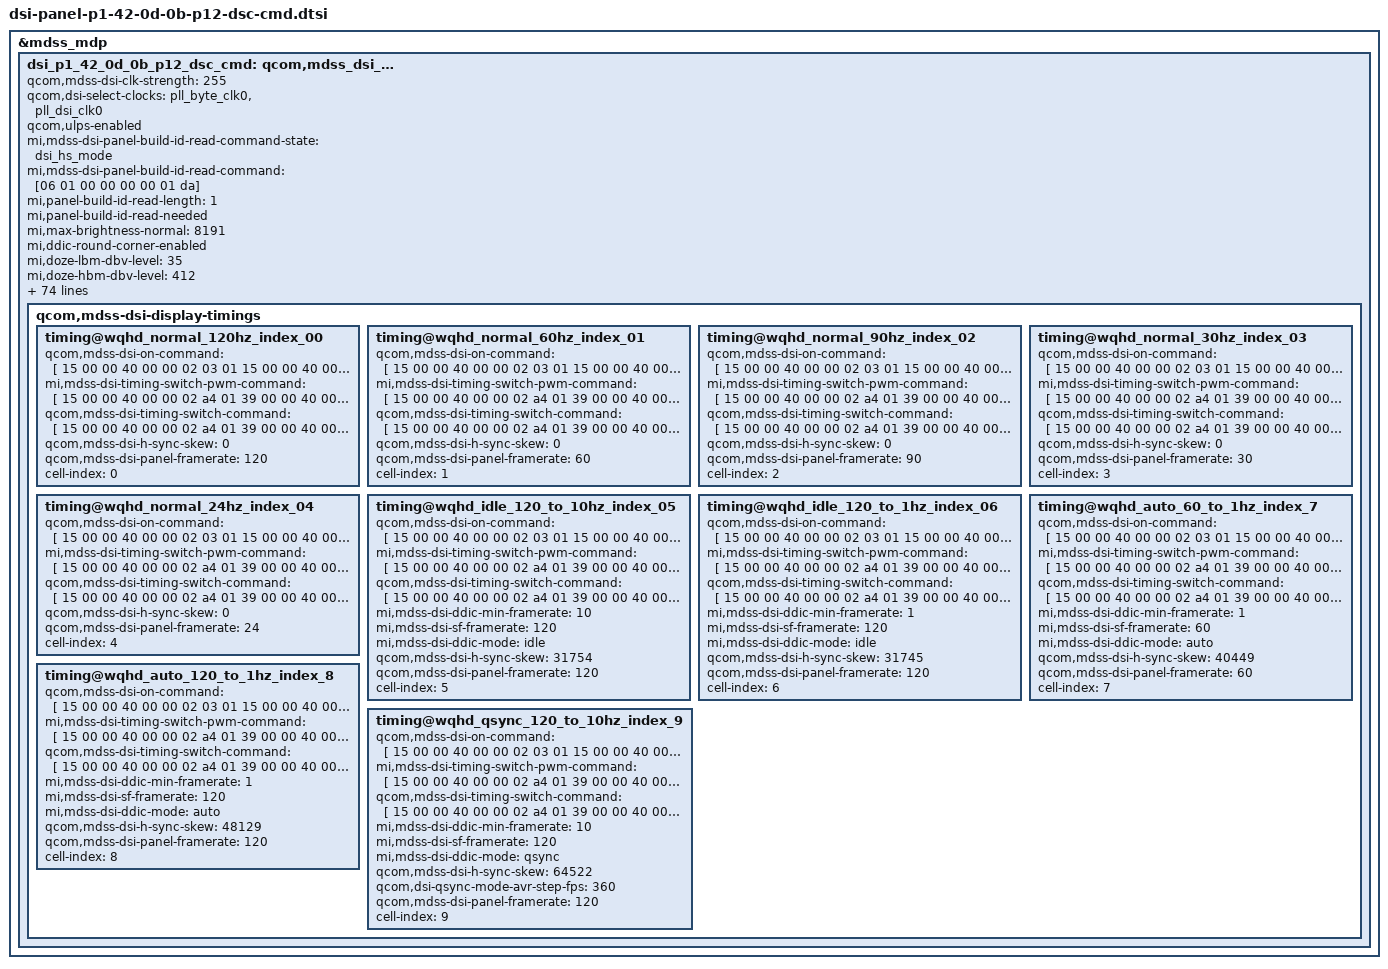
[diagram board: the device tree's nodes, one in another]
/* Xiaomi 17 Ultra panel configuration, OS4.0.7.0.XPACNXM. */

&mdss_mdp {
	dsi_p1_42_0d_0b_p12_dsc_cmd: qcom,mdss_dsi_p1_42_0d_0b_p12_dsc_cmd {
		qcom,mdss-dsi-clk-strength = <255>;
		qcom,dsi-select-clocks = "pll_byte_clk0", "pll_dsi_clk0";
		qcom,ulps-enabled;
		mi,mdss-dsi-panel-build-id-read-command-state = "dsi_hs_mode";
		mi,mdss-dsi-panel-build-id-read-command = [06 01 00 00 00 00 01 da];
		mi,panel-build-id-read-length = <1>;
		mi,panel-build-id-read-needed;
		mi,max-brightness-normal = <8191>;
		mi,ddic-round-corner-enabled;
		mi,doze-lbm-dbv-level = <35>;
		mi,doze-hbm-dbv-level = <412>;
		mi,mdss-dsi-panel-flatmode-on-status-value = <0>;
		mi,mdss-dsi-panel-flatmode-status-read-length = <1>;
		mi,mdss-dsi-panel-flatmode-status-command-state = "dsi_hs_mode";
		mi,mdss-dsi-panel-flatmode-status-command = [06 01 00 01 00 00 01 5f];
		mi,flatmode-status-check-enabled;
		mi,mdss-fac-brightness-max-level = <8191>;
		mi,mdss-dsi-fac-bl-max-level = <8191>;
		mi,mdss-dsi-panel-cell-id-read-length = <13>;
		mi,mdss-dsi-panel-cell-id-read-command-state = "dsi_hs_mode";
		mi,mdss-dsi-panel-cell-id-read-command = [06 01 00 00 00 00 01 5a];
		mi,mdss-dsi-panel-wp-read-length = <8>;
		mi,mdss-dsi-panel-wp-read-command-state = "dsi_hs_mode";
		mi,mdss-dsi-panel-wp-read-command = [06 01 00 00 00 00 01 5c];
		mi,esd-err-irq-gpio-flag = <8196>;
		mi,esd-err-irq-gpio = <&tlmm 97 8196>;
		mi,default-dc-flag;
		mi,dc-feature-enabled;
		mi,panel-on-dimming-delay = <120>;
		mi,panel-id = <20529 4328715>;
		qcom,platform-pmic-reset-gpio = <&tlmm 171 0>;
		qcom,platform-reset-gpio = <&tlmm 98 0>;
		qcom,mdss-brightness-init-level = <916>;
		qcom,mdss-brightness-max-level = <16383>;
		qcom,bl-dsc-cmd-state = "dsi_hs_mode";
		qcom,mdss-dsi-bl-max-level = <16383>;
		qcom,mdss-dsi-bl-min-level = <7>;
		qcom,mdss-dsi-bl-pmic-control-type = "bl_ctrl_dcs";
		qcom,panel-supply-entries = <&dsi_panel_pwr_supply_p1_0b>;
		qcom,mdss-disable-cesta-hw-sleep;
		qcom,mdss-dsi-dma-schedule-window = <50>;
		qcom,mdss-dsi-dma-schedule-line = <1>;
		qcom,mdss-dsi-panel-blackness-level = <3230>;
		qcom,mdss-dsi-panel-peak-brightness = <32000000>;
		qcom,mdss-dsi-panel-hdr-color-primaries = <14500 15500 32000 17000 15500 30000 8000 3000>;
		qcom,mdss-dsi-panel-hdr-enabled;
		qcom,bl-update-flag = "delay_until_first_frame";
		qcom,mdss-dsi-bl-inverted-dbv;
		qcom,mdss-dsi-lp11-init;
		qcom,mdss-dsi-tx-eot-append;
		qcom,mdss-dsi-te-dcs-command = <1>;
		qcom,mdss-dsi-wr-mem-continue = <60>;
		qcom,mdss-dsi-wr-mem-start = <44>;
		qcom,mdss-dsi-te-pin-select = <1>;
		qcom,mdss-pan-physical-height-dimension = <1580>;
		qcom,mdss-pan-physical-width-dimension = <727>;
		qcom,mdss-dsi-reset-sequence = <1 1 0 1 1 10>;
		qcom,mdss-dsi-mdp-trigger = "none";
		qcom,mdss-dsi-dma-trigger = "trigger_sw";
		qcom,mdss-dsi-color-order = "rgb_swap_rgb";
		qcom,mdss-dsi-lane-3-state;
		qcom,mdss-dsi-lane-2-state;
		qcom,mdss-dsi-lane-1-state;
		qcom,mdss-dsi-lane-0-state;
		qcom,mdss-dsi-bllp-power-mode;
		qcom,mdss-dsi-bllp-eof-power-mode;
		qcom,mdss-dsi-traffic-mode = "burst_mode";
		qcom,dsi-phy-num = <0>;
		qcom,dsi-ctrl-num = <0>;
		qcom,mdss-dsi-bpp = <30>;
		qcom,mdss-dsi-virtual-channel-id = <0>;
		qcom,mdss-dsi-panel-physical-type = "oled";
		qcom,mdss-dsi-panel-type = "dsi_cmd_mode";
		qcom,mdss-dsi-panel-name = "xiaomi p1 42 0d 0b prim cmd mode dsc dsi panel";

		qcom,mdss-dsi-display-timings {
			timing@wqhd_normal_120hz_index_00 {
				#include "dsi-panel-p1-42-0d-0b-p12-dsc-cmd-common.dtsi"
				qcom,mdss-dsi-on-command = [
					15 00 00 40 00 00 02 03 01 15 00 00 40 00 00 02
					35 00 15 00 00 40 00 00 02 53 20 39 00 00 40 00
					00 03 51 00 00 15 00 00 40 00 00 02 6f 02 15 00
					00 40 00 00 02 59 09 15 00 00 40 00 00 02 6c 00
					15 00 00 40 00 00 02 6d 00 39 00 00 40 00 00 81
					70 12 00 00 ab 30 80 0a 30 04 b0 00 10 02 58 02
					58 02 00 02 2c 00 20 01 98 00 08 00 0c 06 67 05
					b9 18 00 10 f0 07 10 20 00 06 0f 0f 33 0e 1c 2a
					38 46 54 62 69 70 77 79 7b 7d 7e 02 02 22 00 2a
					40 2a be 3a fc 3a fa 3a f8 3b 38 3b 78 3b b6 4b
					b6 4b f4 4b f4 6c 34 84 74 74 00 00 00 00 00 00
					00 00 00 00 00 00 00 00 00 00 00 00 00 00 00 00
					00 00 00 00 00 00 00 00 00 00 00 00 00 00 00 00
					00 39 00 00 40 00 00 03 ff 5a 81 15 00 00 40 00
					00 02 65 03 15 00 00 40 00 00 02 f3 04 15 00 00
					40 00 00 02 65 05 15 00 00 40 00 00 02 f3 48 39
					00 00 40 00 00 03 f0 aa 10 15 00 00 40 00 00 02
					65 0a 15 00 00 40 00 00 02 eb 10 39 00 00 40 00
					00 03 ff 5a 80 15 00 00 40 00 00 02 65 0e 15 00
					00 40 00 00 02 f9 a1 39 00 00 40 00 00 03 ff 5a
					81 15 00 00 40 00 00 02 65 02 39 00 00 40 00 00
					03 fb 63 73 39 00 00 40 00 00 03 f0 aa 10 15 00
					00 40 00 00 02 65 0b 39 00 00 40 00 00 05 d0 e4
					0f 20 40 15 00 00 40 00 00 02 65 15 39 00 00 40
					00 00 13 d1 be 40 40 40 40 0c 00 00 46 1f 1f 00
					00 40 0c 46 1f 1f 39 00 00 40 00 00 14 d9 39 68
					00 00 00 0b 0a 0d 0c 02 00 00 02 07 06 00 06 02
					0d 15 00 00 40 00 00 02 72 01 39 00 00 40 00 00
					03 ff 5a 83 15 00 00 40 00 00 02 65 0b 15 00 00
					40 00 00 02 f8 05 39 00 00 40 00 00 03 f0 aa 11
					15 00 00 40 00 00 02 c3 31 39 00 00 40 00 00 03
					f0 aa 18 15 00 00 40 00 00 02 b0 80 39 00 00 40
					00 00 03 f0 aa 19 15 00 00 40 00 00 02 c0 e0 39
					00 00 40 00 00 03 f0 aa 1a 15 00 00 40 00 00 02
					b0 01 39 00 00 40 00 00 03 f0 aa 10 39 00 00 40
					00 00 04 eb 00 00 30 39 00 00 40 00 00 08 ea 0f
					41 00 88 48 cb 01 15 00 00 40 00 00 02 65 0d 39
					00 00 40 00 00 04 ea 0c 00 01 15 00 00 40 00 00
					02 65 10 39 00 00 40 00 00 04 ea 0c 80 01 15 00
					00 40 00 00 02 65 13 39 00 00 40 00 00 04 ea c8
					ae 01 15 00 00 40 00 00 02 65 16 39 00 00 40 00
					00 04 ea 64 c1 01 15 00 00 40 00 00 02 65 19 39
					00 00 40 00 00 04 ea 98 a5 01 15 00 00 40 00 00
					02 65 28 39 00 00 40 00 00 04 ea 0c 00 00 39 00
					00 40 00 00 03 f0 aa 00 39 00 00 00 00 00 03 ff
					5a 00 05 00 00 00 78 00 01 11 39 00 00 40 00 00
					03 f0 aa 10 15 00 00 40 00 00 02 65 02 39 00 00
					40 00 00 03 cf 24 13 15 00 00 40 00 00 02 65 0b
					39 00 00 40 00 00 03 cf dd 79 39 00 00 40 00 00
					03 f0 aa 16 39 00 00 40 00 00 16 e3 00 01 00 00
					00 00 00 00 00 00 00 00 00 00 00 00 00 00 00 00
					00 39 00 00 40 00 00 16 e4 00 03 00 00 00 00 00
					00 00 00 00 00 00 00 00 00 00 00 00 00 00 39 00
					00 40 00 00 16 e5 00 04 00 00 00 00 00 00 00 00
					00 00 00 00 00 00 00 00 00 00 00 39 00 00 40 00
					00 16 e6 01 03 0b 00 00 00 00 00 00 00 00 00 00
					00 00 00 00 00 00 00 00 39 00 00 40 00 00 16 e7
					03 03 0b 0b 77 00 00 00 00 0e e0 00 00 00 00 00
					00 00 00 00 00 39 00 00 40 00 00 16 e8 02 0b 0b
					77 00 00 00 00 00 ee 00 00 00 00 00 00 00 00 00
					00 00 39 00 00 40 00 00 16 e9 02 08 08 59 00 00
					00 00 00 ee 00 00 00 00 00 00 00 00 00 00 00 39
					00 00 40 00 00 16 ea 00 0b 00 00 00 00 00 00 00
					00 00 00 00 00 00 00 00 00 00 00 00 39 00 00 40
					00 00 16 eb 02 01 03 ef 00 00 00 00 00 00 00 00
					00 00 00 00 00 00 00 00 00 39 00 00 40 00 00 16
					ec 00 01 00 00 00 00 00 00 00 40 00 00 00 00 00
					00 00 00 00 00 00 39 00 00 40 00 00 1f e0 f0 f1
					f2 f3 f4 f5 f6 00 00 00 f0 f1 f2 f3 f4 f5 f6 00
					00 00 f0 f1 f2 f3 f4 f5 f6 00 00 00 39 00 00 40
					00 00 15 ed f0 f1 f2 f3 f4 f5 f6 f7 f8 00 f0 f1
					f2 f3 f4 f5 f6 f7 f8 00 39 00 00 40 00 00 15 ee
					f0 f1 f2 f3 f4 f5 f6 f7 f8 00 f0 f1 f2 f3 f4 f5
					f6 f7 f8 00 39 00 00 40 00 00 03 f0 aa 12 15 00
					00 00 00 00 02 c7 fe 39 00 00 40 00 00 03 f0 aa
					14 15 00 00 40 00 00 02 65 0c 39 00 00 40 00 00
					03 b5 17 0b 39 00 00 40 00 00 05 bc 10 10 00 1d
					15 00 00 40 00 00 02 65 0c 39 00 00 40 00 00 03
					b6 10 0c 39 00 00 40 00 00 05 bd 10 10 00 22 15
					00 00 40 00 00 02 65 0c 39 00 00 40 00 00 05 c6
					02 06 1e 02 39 00 00 40 00 00 06 ca 10 10 00 1f
					22 39 00 00 40 00 00 03 f0 aa 1b 15 00 00 40 00
					00 02 65 09 39 00 00 00 00 00 04 de 1f 02 02 15
					00 00 40 00 00 02 6c 00 39 00 00 40 00 00 03 75
					00 00 39 00 00 40 00 00 04 71 00 00 00 39 00 00
					40 00 00 03 f0 aa 16 15 00 00 40 00 00 02 d0 00
					15 00 00 40 00 00 02 65 01 15 00 00 40 00 00 02
					d1 00 15 00 00 40 00 00 02 d2 01 15 00 00 40 00
					00 02 76 00 15 00 00 40 00 00 02 77 00 39 00 00
					40 00 00 03 f0 aa 10 15 00 00 40 00 00 02 cf 17
					39 00 00 40 00 00 03 f0 aa 17 15 00 00 40 00 00
					02 c2 80 05 00 00 00 00 00 01 29 39 00 00 40 00
					00 03 f0 aa 17 39 00 00 40 00 00 02 b0 b0 39 00
					00 40 00 00 05 b1 08 06 06 00 39 00 00 40 00 00
					37 b2 00 40 00 00 40 00 00 20 20 00 40 00 00 40
					00 00 20 20 00 00 00 00 e0 00 00 00 20 00 00 20
					00 00 20 00 00 20 00 00 00 00 00 00 00 00 18 00
					00 18 00 00 44 00 00 00 39 00 00 40 00 00 25 b3
					88 b8 00 88 b8 80 80 c0 80 00 40 00 00 40 00 00
					40 00 08 38 00 08 38 00 00 40 00 00 40 00 00 40
					00 00 40 00 39 00 00 40 00 00 1a b4 00 03 06 0c
					18 03 06 0c 18 03 06 0c 18 03 06 0c 18 03 06 0c
					18 03 06 0c 18 39 00 00 40 00 00 0a b5 00 00 00
					00 00 00 00 00 00 39 00 00 40 00 00 31 b6 1f 1f
					1f 1f 1f 1f 1f 1f 1f 1f 1f 1f 1f 1f 1f 1f 1f 1f
					1f 1f 1f 1f 1f 1f 1f 1f 1f 1f 1f 1f 1f 1f 1f 1f
					1f 1f 1f 1f 1f 1f 1f 1f 1f 1f 1f 1f 1f 1f 39 00
					00 00 00 00 1e b7 00 12 34 12 34 52 34 56 34 56
					74 56 78 33 94 26 64 19 98 0c cc 33 94 26 64 19
					98 0c cc 39 00 00 40 00 00 03 f0 aa 10 15 00 00
					40 00 00 02 65 0b 39 00 00 40 00 00 03 cf dd 79
					39 00 00 00 00 00 03 f0 aa 00 39 00 00 40 00 00
					03 f0 aa 19 39 00 00 40 00 00 03 c7 00 00 15 00
					00 40 00 00 02 c4 80 39 00 00 40 00 00 0d c8 ec
					00 00 00 00 00 03 60 00 00 00 00 39 00 00 40 00
					00 0d c8 03 f0 00 00 00 00 00 30 40 00 00 00 39
					00 00 40 00 00 0d c8 03 f0 00 fc 00 00 00 10 00
					00 00 00 39 00 00 40 00 00 0d c8 00 20 00 03 f0
					00 50 a0 c2 08 20 41 39 00 00 40 00 00 0d c8 d4
					00 00 00 00 00 2c 00 00 00 00 00 39 00 00 40 00
					00 0d c8 20 40 00 00 00 00 03 df fe 00 00 00 39
					00 00 40 00 00 0d c8 10 1f c1 f8 00 00 10 10 3e
					04 10 00 39 00 00 40 00 00 0d c8 04 00 00 fb ff
					c0 60 82 06 14 30 c1 39 00 00 40 00 00 0d c8 00
					00 00 00 00 00 03 f0 00 00 00 00 39 00 00 40 00
					00 0d c8 f7 cf 80 00 00 00 07 ef ff 00 00 00 39
					00 00 40 00 00 0d c8 03 f0 00 fc 00 00 03 f0 00
					03 f0 00 39 00 00 40 00 00 0d c8 00 2f bf 00 00
					00 50 81 83 08 20 41 15 00 00 00 00 00 02 c4 00
					39 00 00 40 00 00 03 f0 aa 19 39 00 00 40 00 00
					03 c7 00 15 15 00 00 40 00 00 02 c4 80 39 00 00
					40 00 00 0d c8 f0 00 00 00 00 00 f8 20 00 00 00
					00 39 00 00 40 00 00 0d c8 ff ff c0 00 00 00 f3
					ef ff 00 00 00 39 00 00 40 00 00 0d c8 f3 ff ff
					fc 00 00 fb ff c0 ff f0 00 39 00 00 40 00 00 0d
					c8 f7 df bf 00 0f c0 5c a1 c4 0c 20 81 39 00 00
					40 00 00 0d c8 f4 00 00 00 00 00 ff f0 00 00 00
					00 39 00 00 40 00 00 0d c8 ff ff c0 00 00 00 f7
					ff c0 00 00 00 39 00 00 40 00 00 0d c8 fb ef ff
					00 00 00 fb ff ff fc 00 00 39 00 00 40 00 00 0d
					c8 ff ff ff ff f0 00 3c 81 84 0c 20 41 39 00 00
					40 00 00 0d c8 f4 00 00 00 00 00 f4 00 00 00 00
					00 39 00 00 40 00 00 0d c8 f8 0f c0 00 00 00 f7
					ff c0 00 00 00 39 00 00 40 00 00 0d c8 f7 d0 00
					00 00 00 f7 ef fe ff f0 00 39 00 00 40 00 00 0d
					c8 f8 0f c1 03 ff c0 5c 81 02 08 20 40 15 00 00
					00 00 00 02 c4 00 39 00 00 40 00 00 03 f0 aa 19
					39 00 00 40 00 00 03 c7 00 2a 15 00 00 40 00 00
					02 c4 80 39 00 00 40 00 00 0d c8 f4 00 00 00 00
					00 f4 00 00 00 00 00 39 00 00 40 00 00 0d c8 f7
					ef c0 00 00 00 f7 ff c0 00 00 00 39 00 00 40 00
					00 0d c8 fb f0 3f 00 00 00 f3 ef bf ff f0 00 39
					00 00 40 00 00 0d c8 ff ff ff fc 00 00 54 81 84
					0c 20 41 39 00 00 40 00 00 0d c8 f8 00 00 00 00
					00 f7 f0 00 00 00 00 39 00 00 40 00 00 0d c8 f7
					f0 00 00 00 00 f7 ff c0 00 00 00 39 00 00 40 00
					00 0d c8 fb ff fe fc 00 00 f7 ff c0 00 00 00 39
					00 00 40 00 00 0d c8 ff ff c0 00 00 00 50 71 43
					08 10 41 39 00 00 40 00 00 0d c8 f8 00 00 00 00
					00 f7 f0 00 00 00 00 39 00 00 40 00 00 0d c8 f3
					ff 00 00 00 00 f7 b0 c0 00 00 00 39 00 00 40 00
					00 0d c8 f8 3f ff f0 00 00 fb ff ff fc 00 00 39
					00 00 40 00 00 0d c8 ff f0 00 13 f0 00 50 71 03
					08 20 41 15 00 00 00 00 00 02 c4 00 39 00 00 40
					00 00 03 f0 aa 19 39 00 00 40 00 00 03 c7 00 3f
					15 00 00 40 00 00 02 c4 80 39 00 00 40 00 00 0d
					c8 20 40 40 60 60 60 80 80 80 80 a0 a0 39 00 00
					40 00 00 0d c8 a0 a0 a0 c0 c0 c0 c0 c0 c0 e0 e0
					e0 39 00 00 40 00 00 0d c8 e0 e0 e0 e0 ff ff ff
					ff ff ff ff ff 39 00 00 40 00 00 0d c8 1b 1c 2f
					1e 4c 5b 1f 56 5c 6e a0 a0 39 00 00 40 00 00 0d
					c8 a0 a0 a0 c0 c0 c0 c0 c0 c0 e0 e0 e0 39 00 00
					40 00 00 0d c8 e0 e0 e0 e0 ff ff ff ff ff ff ff
					ff 39 00 00 40 00 00 0d c8 20 40 40 60 60 60 80
					80 80 80 a0 a0 39 00 00 40 00 00 0d c8 a0 a0 a0
					c0 c0 c0 c0 c0 c0 e0 e0 e0 39 00 00 40 00 00 0d
					c8 e0 e0 e0 e0 ff ff ff ff ff ff ff ff 15 00 00
					00 00 00 02 c4 00 39 00 00 40 00 00 03 f0 aa 19
					39 00 00 40 00 00 03 c7 00 c6 15 00 00 40 00 00
					02 c4 80 39 00 00 40 00 00 0d c8 f8 00 00 00 00
					00 d8 00 00 00 00 00 39 00 00 40 00 00 0d c8 03
					f0 00 00 00 00 00 00 40 00 00 00 39 00 00 40 00
					00 0d c8 ec 00 00 fc 00 00 00 00 00 00 00 00 39
					00 00 40 00 00 0d c8 00 00 00 03 f0 00 50 50 c2
					08 20 41 39 00 00 40 00 00 0d c8 c8 00 00 00 00
					00 00 00 00 00 00 00 39 00 00 40 00 00 0d c8 00
					40 00 00 00 00 0b df fe 00 00 00 39 00 00 40 00
					00 0d c8 fc 1f c1 f8 00 00 fc 10 3e 04 10 00 39
					00 00 40 00 00 0d c8 00 00 00 fb ff c0 78 82 06
					14 30 c1 39 00 00 40 00 00 0d c8 00 00 00 00 00
					00 03 f0 00 00 00 00 39 00 00 40 00 00 0d c8 f7
					cf 80 00 00 00 07 ef ff 00 00 00 39 00 00 40 00
					00 0d c8 03 f0 00 fc 00 00 03 f0 00 03 f0 00 39
					00 00 40 00 00 0d c8 00 2f bf 00 00 00 50 81 83
					08 20 41 15 00 00 00 00 00 02 c4 00 39 00 00 40
					00 00 03 f0 aa 19 39 00 00 40 00 00 03 c7 00 db
					15 00 00 40 00 00 02 c4 80 39 00 00 40 00 00 0d
					c8 f0 00 00 00 00 00 f8 20 00 00 00 00 39 00 00
					40 00 00 0d c8 ff ff c0 00 00 00 f3 ef ff 00 00
					00 39 00 00 40 00 00 0d c8 f3 ff ff fc 00 00 fb
					ff c0 ff f0 00 39 00 00 40 00 00 0d c8 f7 df bf
					00 0f c0 5c a1 c4 0c 20 81 39 00 00 40 00 00 0d
					c8 f8 00 00 00 00 00 ff f0 00 00 00 00 39 00 00
					40 00 00 0d c8 ff ff c0 00 00 00 f7 ff c0 00 00
					00 39 00 00 40 00 00 0d c8 fb ef ff 00 00 00 fb
					ff ff fc 00 00 39 00 00 40 00 00 0d c8 ff ff ff
					ff f0 00 3c 81 84 0c 20 41 39 00 00 40 00 00 0d
					c8 f4 00 00 00 00 00 f4 00 00 00 00 00 39 00 00
					40 00 00 0d c8 f8 0f c0 00 00 00 f7 ff c0 00 00
					00 39 00 00 40 00 00 0d c8 f7 d0 00 00 00 00 f7
					ef fe ff f0 00 39 00 00 40 00 00 0d c8 f8 0f c1
					03 ff c0 5c 81 02 08 20 40 15 00 00 00 00 00 02
					c4 00 39 00 00 40 00 00 03 f0 aa 19 39 00 00 40
					00 00 03 c7 01 05 15 00 00 40 00 00 02 c4 80 39
					00 00 40 00 00 0d c8 20 40 40 60 60 60 80 80 80
					80 a0 a0 39 00 00 40 00 00 0d c8 a0 a0 a0 c0 c0
					c0 c0 c0 c0 e0 e0 e0 39 00 00 40 00 00 0d c8 e0
					e0 e0 e0 ff ff ff ff ff ff ff ff 39 00 00 40 00
					00 0d c8 20 40 40 60 60 60 80 80 80 80 a0 a0 39
					00 00 40 00 00 0d c8 a0 a0 a0 c0 c0 c0 c0 c0 c0
					e0 e0 e0 39 00 00 40 00 00 0d c8 e0 e0 e0 e0 ff
					ff ff ff ff ff ff ff 39 00 00 40 00 00 0d c8 20
					40 40 60 60 60 80 80 80 80 a0 a0 39 00 00 40 00
					00 0d c8 a0 a0 a0 c0 c0 c0 c0 c0 c0 e0 e0 e0 39
					00 00 40 00 00 0d c8 e0 e0 e0 e0 ff ff ff ff ff
					ff ff ff 15 00 00 00 00 00 02 c4 00
				];
				mi,mdss-dsi-timing-switch-pwm-command = [
					15 00 00 40 00 00 02 a4 01 39 00 00 40 00 00 03
					f0 aa 14 15 00 00 40 00 00 02 65 0c 39 00 00 40
					00 00 03 b5 18 0c 39 00 00 40 00 00 05 bc 10 10
					00 1e 15 00 00 40 00 00 02 65 0c 39 00 00 40 00
					00 03 b6 0f 0b 39 00 00 40 00 00 05 bd 10 10 00
					21 15 00 00 40 00 00 02 65 0c 39 00 00 40 00 00
					05 c6 03 07 1f 03 39 00 00 40 00 00 06 ca 10 10
					00 1e 13 39 00 00 40 00 00 03 f0 aa 1b 15 00 00
					40 00 00 02 65 09 39 00 00 40 00 00 04 de 1e 01
					03 15 00 00 00 00 00 02 a4 00 15 00 00 40 00 00
					02 6c 02 39 00 00 40 00 00 03 75 00 00 39 00 00
					40 00 00 04 71 00 00 00 39 00 00 40 00 00 03 f0
					aa 16 15 00 00 40 00 00 02 d0 00 15 00 00 40 00
					00 02 65 07 15 00 00 40 00 00 02 d1 02 15 00 00
					40 00 00 02 d2 01 15 00 00 40 00 00 02 65 02 39
					00 00 40 00 00 04 d2 03 65 0f 15 00 00 40 00 00
					02 76 01 15 00 00 40 00 00 02 77 05 39 00 00 40
					00 00 03 f0 aa 10 15 00 00 40 00 00 02 cf 09 15
					00 00 00 00 00 02 a6 01
				];
				qcom,mdss-dsi-timing-switch-command = [
					15 00 00 40 00 00 02 a4 01 39 00 00 40 00 00 03
					f0 aa 14 15 00 00 40 00 00 02 65 0c 39 00 00 40
					00 00 03 b5 17 0b 39 00 00 40 00 00 05 bc 10 10
					00 1d 15 00 00 40 00 00 02 65 0c 39 00 00 40 00
					00 03 b6 10 0c 39 00 00 40 00 00 05 bd 10 10 00
					22 15 00 00 40 00 00 02 65 0c 39 00 00 40 00 00
					05 c6 02 06 1e 02 39 00 00 40 00 00 06 ca 10 10
					00 1f 22 39 00 00 40 00 00 03 f0 aa 1b 15 00 00
					40 00 00 02 65 09 39 00 00 40 00 00 04 de 1f 02
					02 15 00 00 00 00 00 02 a4 00 15 00 00 40 00 00
					02 6c 00 39 00 00 40 00 00 03 75 00 00 39 00 00
					40 00 00 04 71 00 00 00 39 00 00 40 00 00 03 f0
					aa 16 15 00 00 40 00 00 02 d0 00 15 00 00 40 00
					00 02 65 01 15 00 00 40 00 00 02 d1 00 15 00 00
					40 00 00 02 d2 01 15 00 00 40 00 00 02 76 00 15
					00 00 40 00 00 02 77 00 39 00 00 40 00 00 03 f0
					aa 10 15 00 00 40 00 00 02 cf 17 39 00 00 40 00
					00 03 f0 aa 17 15 00 00 40 00 00 02 c2 80 15 00
					00 00 00 00 02 a6 01
				];
				qcom,mdss-dsi-h-sync-skew = <0>;
				qcom,mdss-dsi-panel-framerate = <120>;
				cell-index = <0>;
			};

			timing@wqhd_normal_60hz_index_01 {
				#include "dsi-panel-p1-42-0d-0b-p12-dsc-cmd-common.dtsi"
				qcom,mdss-dsi-on-command = [
					15 00 00 40 00 00 02 03 01 15 00 00 40 00 00 02
					35 00 15 00 00 40 00 00 02 53 20 39 00 00 40 00
					00 03 51 00 00 15 00 00 40 00 00 02 6f 02 15 00
					00 40 00 00 02 59 09 15 00 00 40 00 00 02 6c 00
					15 00 00 40 00 00 02 6d 00 39 00 00 40 00 00 81
					70 12 00 00 ab 30 80 0a 30 04 b0 00 10 02 58 02
					58 02 00 02 2c 00 20 01 98 00 08 00 0c 06 67 05
					b9 18 00 10 f0 07 10 20 00 06 0f 0f 33 0e 1c 2a
					38 46 54 62 69 70 77 79 7b 7d 7e 02 02 22 00 2a
					40 2a be 3a fc 3a fa 3a f8 3b 38 3b 78 3b b6 4b
					b6 4b f4 4b f4 6c 34 84 74 74 00 00 00 00 00 00
					00 00 00 00 00 00 00 00 00 00 00 00 00 00 00 00
					00 00 00 00 00 00 00 00 00 00 00 00 00 00 00 00
					00 39 00 00 40 00 00 03 ff 5a 81 15 00 00 40 00
					00 02 65 03 15 00 00 40 00 00 02 f3 04 15 00 00
					40 00 00 02 65 05 15 00 00 40 00 00 02 f3 48 39
					00 00 40 00 00 03 f0 aa 10 15 00 00 40 00 00 02
					65 0a 15 00 00 40 00 00 02 eb 10 39 00 00 40 00
					00 03 ff 5a 80 15 00 00 40 00 00 02 65 0e 15 00
					00 40 00 00 02 f9 a1 39 00 00 40 00 00 03 ff 5a
					81 15 00 00 40 00 00 02 65 02 39 00 00 40 00 00
					03 fb 63 73 39 00 00 40 00 00 03 f0 aa 10 15 00
					00 40 00 00 02 65 0b 39 00 00 40 00 00 05 d0 e4
					0f 20 40 15 00 00 40 00 00 02 65 15 39 00 00 40
					00 00 13 d1 be 40 40 40 40 0c 00 00 46 1f 1f 00
					00 40 0c 46 1f 1f 39 00 00 40 00 00 14 d9 39 68
					00 00 00 0b 0a 0d 0c 02 00 00 02 07 06 00 06 02
					0d 15 00 00 40 00 00 02 72 01 39 00 00 40 00 00
					03 ff 5a 83 15 00 00 40 00 00 02 65 0b 15 00 00
					40 00 00 02 f8 05 39 00 00 40 00 00 03 f0 aa 11
					15 00 00 40 00 00 02 c3 31 39 00 00 40 00 00 03
					f0 aa 18 15 00 00 40 00 00 02 b0 80 39 00 00 40
					00 00 03 f0 aa 19 15 00 00 40 00 00 02 c0 e0 39
					00 00 40 00 00 03 f0 aa 1a 15 00 00 40 00 00 02
					b0 01 39 00 00 40 00 00 03 f0 aa 10 39 00 00 40
					00 00 04 eb 00 00 30 39 00 00 40 00 00 08 ea 0f
					41 00 88 48 cb 01 15 00 00 40 00 00 02 65 0d 39
					00 00 40 00 00 04 ea 0c 00 01 15 00 00 40 00 00
					02 65 10 39 00 00 40 00 00 04 ea 0c 80 01 15 00
					00 40 00 00 02 65 13 39 00 00 40 00 00 04 ea c8
					ae 01 15 00 00 40 00 00 02 65 16 39 00 00 40 00
					00 04 ea 64 c1 01 15 00 00 40 00 00 02 65 19 39
					00 00 40 00 00 04 ea 98 a5 01 15 00 00 40 00 00
					02 65 28 39 00 00 40 00 00 04 ea 0c 00 00 39 00
					00 40 00 00 03 f0 aa 00 39 00 00 00 00 00 03 ff
					5a 00 05 00 00 00 78 00 01 11 39 00 00 40 00 00
					03 f0 aa 10 15 00 00 40 00 00 02 65 02 39 00 00
					40 00 00 03 cf 24 13 15 00 00 40 00 00 02 65 0b
					39 00 00 40 00 00 03 cf dd 79 39 00 00 40 00 00
					03 f0 aa 16 39 00 00 40 00 00 16 e3 00 01 00 00
					00 00 00 00 00 00 00 00 00 00 00 00 00 00 00 00
					00 39 00 00 40 00 00 16 e4 00 03 00 00 00 00 00
					00 00 00 00 00 00 00 00 00 00 00 00 00 00 39 00
					00 40 00 00 16 e5 00 04 00 00 00 00 00 00 00 00
					00 00 00 00 00 00 00 00 00 00 00 39 00 00 40 00
					00 16 e6 01 03 0b 00 00 00 00 00 00 00 00 00 00
					00 00 00 00 00 00 00 00 39 00 00 40 00 00 16 e7
					03 03 0b 0b 77 00 00 00 00 0e e0 00 00 00 00 00
					00 00 00 00 00 39 00 00 40 00 00 16 e8 02 0b 0b
					77 00 00 00 00 00 ee 00 00 00 00 00 00 00 00 00
					00 00 39 00 00 40 00 00 16 e9 02 08 08 59 00 00
					00 00 00 ee 00 00 00 00 00 00 00 00 00 00 00 39
					00 00 40 00 00 16 ea 00 0b 00 00 00 00 00 00 00
					00 00 00 00 00 00 00 00 00 00 00 00 39 00 00 40
					00 00 16 eb 02 01 03 ef 00 00 00 00 00 00 00 00
					00 00 00 00 00 00 00 00 00 39 00 00 40 00 00 16
					ec 00 01 00 00 00 00 00 00 00 40 00 00 00 00 00
					00 00 00 00 00 00 39 00 00 40 00 00 1f e0 f0 f1
					f2 f3 f4 f5 f6 00 00 00 f0 f1 f2 f3 f4 f5 f6 00
					00 00 f0 f1 f2 f3 f4 f5 f6 00 00 00 39 00 00 40
					00 00 15 ed f0 f1 f2 f3 f4 f5 f6 f7 f8 00 f0 f1
					f2 f3 f4 f5 f6 f7 f8 00 39 00 00 40 00 00 15 ee
					f0 f1 f2 f3 f4 f5 f6 f7 f8 00 f0 f1 f2 f3 f4 f5
					f6 f7 f8 00 39 00 00 40 00 00 03 f0 aa 12 15 00
					00 00 00 00 02 c7 fe 39 00 00 40 00 00 03 f0 aa
					14 15 00 00 40 00 00 02 65 0c 39 00 00 40 00 00
					03 b5 17 0b 39 00 00 40 00 00 05 bc 10 10 00 1d
					15 00 00 40 00 00 02 65 0c 39 00 00 40 00 00 03
					b6 10 0c 39 00 00 40 00 00 05 bd 10 10 00 22 15
					00 00 40 00 00 02 65 0c 39 00 00 40 00 00 05 c6
					02 06 1e 02 39 00 00 40 00 00 06 ca 10 10 00 1f
					22 39 00 00 40 00 00 03 f0 aa 1b 15 00 00 40 00
					00 02 65 09 39 00 00 00 00 00 04 de 1f 02 02 15
					00 00 40 00 00 02 6c 00 39 00 00 40 00 00 03 75
					c0 00 39 00 00 40 00 00 04 71 01 00 01 39 00 00
					40 00 00 03 f0 aa 16 15 00 00 40 00 00 02 d0 00
					15 00 00 40 00 00 02 65 01 15 00 00 40 00 00 02
					d1 00 15 00 00 40 00 00 02 d2 01 15 00 00 40 00
					00 02 65 02 39 00 00 40 00 00 04 d2 0a 53 0f 15
					00 00 40 00 00 02 76 01 15 00 00 40 00 00 02 77
					03 39 00 00 40 00 00 03 f0 aa 10 15 00 00 40 00
					00 02 cf 09 39 00 00 40 00 00 03 f0 aa 17 15 00
					00 40 00 00 02 c2 80 05 00 00 00 00 00 01 29 39
					00 00 40 00 00 03 f0 aa 17 39 00 00 40 00 00 02
					b0 b0 39 00 00 40 00 00 05 b1 08 06 06 00 39 00
					00 40 00 00 37 b2 00 40 00 00 40 00 00 20 20 00
					40 00 00 40 00 00 20 20 00 00 00 00 e0 00 00 00
					20 00 00 20 00 00 20 00 00 20 00 00 00 00 00 00
					00 00 18 00 00 18 00 00 44 00 00 00 39 00 00 40
					00 00 25 b3 88 b8 00 88 b8 80 80 c0 80 00 40 00
					00 40 00 00 40 00 08 38 00 08 38 00 00 40 00 00
					40 00 00 40 00 00 40 00 39 00 00 40 00 00 1a b4
					00 03 06 0c 18 03 06 0c 18 03 06 0c 18 03 06 0c
					18 03 06 0c 18 03 06 0c 18 39 00 00 40 00 00 0a
					b5 00 00 00 00 00 00 00 00 00 39 00 00 40 00 00
					31 b6 1f 1f 1f 1f 1f 1f 1f 1f 1f 1f 1f 1f 1f 1f
					1f 1f 1f 1f 1f 1f 1f 1f 1f 1f 1f 1f 1f 1f 1f 1f
					1f 1f 1f 1f 1f 1f 1f 1f 1f 1f 1f 1f 1f 1f 1f 1f
					1f 1f 39 00 00 00 00 00 1e b7 00 12 34 12 34 52
					34 56 34 56 74 56 78 33 94 26 64 19 98 0c cc 33
					94 26 64 19 98 0c cc 39 00 00 40 00 00 03 f0 aa
					10 15 00 00 40 00 00 02 65 0b 39 00 00 40 00 00
					03 cf dd 79 39 00 00 00 00 00 03 f0 aa 00 39 00
					00 40 00 00 03 f0 aa 19 39 00 00 40 00 00 03 c7
					00 00 15 00 00 40 00 00 02 c4 80 39 00 00 40 00
					00 0d c8 ec 00 00 00 00 00 03 60 00 00 00 00 39
					00 00 40 00 00 0d c8 03 f0 00 00 00 00 00 30 40
					00 00 00 39 00 00 40 00 00 0d c8 03 f0 00 fc 00
					00 00 10 00 00 00 00 39 00 00 40 00 00 0d c8 00
					20 00 03 f0 00 50 a0 c2 08 20 41 39 00 00 40 00
					00 0d c8 d4 00 00 00 00 00 2c 00 00 00 00 00 39
					00 00 40 00 00 0d c8 20 40 00 00 00 00 03 df fe
					00 00 00 39 00 00 40 00 00 0d c8 10 1f c1 f8 00
					00 10 10 3e 04 10 00 39 00 00 40 00 00 0d c8 04
					00 00 fb ff c0 60 82 06 14 30 c1 39 00 00 40 00
					00 0d c8 00 00 00 00 00 00 03 f0 00 00 00 00 39
					00 00 40 00 00 0d c8 f7 cf 80 00 00 00 07 ef ff
					00 00 00 39 00 00 40 00 00 0d c8 03 f0 00 fc 00
					00 03 f0 00 03 f0 00 39 00 00 40 00 00 0d c8 00
					2f bf 00 00 00 50 81 83 08 20 41 15 00 00 00 00
					00 02 c4 00 39 00 00 40 00 00 03 f0 aa 19 39 00
					00 40 00 00 03 c7 00 15 15 00 00 40 00 00 02 c4
					80 39 00 00 40 00 00 0d c8 f0 00 00 00 00 00 f8
					20 00 00 00 00 39 00 00 40 00 00 0d c8 ff ff c0
					00 00 00 f3 ef ff 00 00 00 39 00 00 40 00 00 0d
					c8 f3 ff ff fc 00 00 fb ff c0 ff f0 00 39 00 00
					40 00 00 0d c8 f7 df bf 00 0f c0 5c a1 c4 0c 20
					81 39 00 00 40 00 00 0d c8 f4 00 00 00 00 00 ff
					f0 00 00 00 00 39 00 00 40 00 00 0d c8 ff ff c0
					00 00 00 f7 ff c0 00 00 00 39 00 00 40 00 00 0d
					c8 fb ef ff 00 00 00 fb ff ff fc 00 00 39 00 00
					40 00 00 0d c8 ff ff ff ff f0 00 3c 81 84 0c 20
					41 39 00 00 40 00 00 0d c8 f4 00 00 00 00 00 f4
					00 00 00 00 00 39 00 00 40 00 00 0d c8 f8 0f c0
					00 00 00 f7 ff c0 00 00 00 39 00 00 40 00 00 0d
					c8 f7 d0 00 00 00 00 f7 ef fe ff f0 00 39 00 00
					40 00 00 0d c8 f8 0f c1 03 ff c0 5c 81 02 08 20
					40 15 00 00 00 00 00 02 c4 00 39 00 00 40 00 00
					03 f0 aa 19 39 00 00 40 00 00 03 c7 00 2a 15 00
					00 40 00 00 02 c4 80 39 00 00 40 00 00 0d c8 f4
					00 00 00 00 00 f4 00 00 00 00 00 39 00 00 40 00
					00 0d c8 f7 ef c0 00 00 00 f7 ff c0 00 00 00 39
					00 00 40 00 00 0d c8 fb f0 3f 00 00 00 f3 ef bf
					ff f0 00 39 00 00 40 00 00 0d c8 ff ff ff fc 00
					00 54 81 84 0c 20 41 39 00 00 40 00 00 0d c8 f8
					00 00 00 00 00 f7 f0 00 00 00 00 39 00 00 40 00
					00 0d c8 f7 f0 00 00 00 00 f7 ff c0 00 00 00 39
					00 00 40 00 00 0d c8 fb ff fe fc 00 00 f7 ff c0
					00 00 00 39 00 00 40 00 00 0d c8 ff ff c0 00 00
					00 50 71 43 08 10 41 39 00 00 40 00 00 0d c8 f8
					00 00 00 00 00 f7 f0 00 00 00 00 39 00 00 40 00
					00 0d c8 f3 ff 00 00 00 00 f7 b0 c0 00 00 00 39
					00 00 40 00 00 0d c8 f8 3f ff f0 00 00 fb ff ff
					fc 00 00 39 00 00 40 00 00 0d c8 ff f0 00 13 f0
					00 50 71 03 08 20 41 15 00 00 00 00 00 02 c4 00
					39 00 00 40 00 00 03 f0 aa 19 39 00 00 40 00 00
					03 c7 00 3f 15 00 00 40 00 00 02 c4 80 39 00 00
					40 00 00 0d c8 20 40 40 60 60 60 80 80 80 80 a0
					a0 39 00 00 40 00 00 0d c8 a0 a0 a0 c0 c0 c0 c0
					c0 c0 e0 e0 e0 39 00 00 40 00 00 0d c8 e0 e0 e0
					e0 ff ff ff ff ff ff ff ff 39 00 00 40 00 00 0d
					c8 1b 1c 2f 1e 4c 5b 1f 56 5c 6e a0 a0 39 00 00
					40 00 00 0d c8 a0 a0 a0 c0 c0 c0 c0 c0 c0 e0 e0
					e0 39 00 00 40 00 00 0d c8 e0 e0 e0 e0 ff ff ff
					ff ff ff ff ff 39 00 00 40 00 00 0d c8 20 40 40
					60 60 60 80 80 80 80 a0 a0 39 00 00 40 00 00 0d
					c8 a0 a0 a0 c0 c0 c0 c0 c0 c0 e0 e0 e0 39 00 00
					40 00 00 0d c8 e0 e0 e0 e0 ff ff ff ff ff ff ff
					ff 15 00 00 00 00 00 02 c4 00 39 00 00 40 00 00
					03 f0 aa 19 39 00 00 40 00 00 03 c7 00 c6 15 00
					00 40 00 00 02 c4 80 39 00 00 40 00 00 0d c8 f8
					00 00 00 00 00 d8 00 00 00 00 00 39 00 00 40 00
					00 0d c8 03 f0 00 00 00 00 00 00 40 00 00 00 39
					00 00 40 00 00 0d c8 ec 00 00 fc 00 00 00 00 00
					00 00 00 39 00 00 40 00 00 0d c8 00 00 00 03 f0
					00 50 50 c2 08 20 41 39 00 00 40 00 00 0d c8 c8
					00 00 00 00 00 00 00 00 00 00 00 39 00 00 40 00
					00 0d c8 00 40 00 00 00 00 0b df fe 00 00 00 39
					00 00 40 00 00 0d c8 fc 1f c1 f8 00 00 fc 10 3e
					04 10 00 39 00 00 40 00 00 0d c8 00 00 00 fb ff
					c0 78 82 06 14 30 c1 39 00 00 40 00 00 0d c8 00
					00 00 00 00 00 03 f0 00 00 00 00 39 00 00 40 00
					00 0d c8 f7 cf 80 00 00 00 07 ef ff 00 00 00 39
					00 00 40 00 00 0d c8 03 f0 00 fc 00 00 03 f0 00
					03 f0 00 39 00 00 40 00 00 0d c8 00 2f bf 00 00
					00 50 81 83 08 20 41 15 00 00 00 00 00 02 c4 00
					39 00 00 40 00 00 03 f0 aa 19 39 00 00 40 00 00
					03 c7 00 db 15 00 00 40 00 00 02 c4 80 39 00 00
					40 00 00 0d c8 f0 00 00 00 00 00 f8 20 00 00 00
					00 39 00 00 40 00 00 0d c8 ff ff c0 00 00 00 f3
					ef ff 00 00 00 39 00 00 40 00 00 0d c8 f3 ff ff
					fc 00 00 fb ff c0 ff f0 00 39 00 00 40 00 00 0d
					c8 f7 df bf 00 0f c0 5c a1 c4 0c 20 81 39 00 00
					40 00 00 0d c8 f8 00 00 00 00 00 ff f0 00 00 00
					00 39 00 00 40 00 00 0d c8 ff ff c0 00 00 00 f7
					ff c0 00 00 00 39 00 00 40 00 00 0d c8 fb ef ff
					00 00 00 fb ff ff fc 00 00 39 00 00 40 00 00 0d
					c8 ff ff ff ff f0 00 3c 81 84 0c 20 41 39 00 00
					40 00 00 0d c8 f4 00 00 00 00 00 f4 00 00 00 00
					00 39 00 00 40 00 00 0d c8 f8 0f c0 00 00 00 f7
					ff c0 00 00 00 39 00 00 40 00 00 0d c8 f7 d0 00
					00 00 00 f7 ef fe ff f0 00 39 00 00 40 00 00 0d
					c8 f8 0f c1 03 ff c0 5c 81 02 08 20 40 15 00 00
					00 00 00 02 c4 00 39 00 00 40 00 00 03 f0 aa 19
					39 00 00 40 00 00 03 c7 01 05 15 00 00 40 00 00
					02 c4 80 39 00 00 40 00 00 0d c8 20 40 40 60 60
					60 80 80 80 80 a0 a0 39 00 00 40 00 00 0d c8 a0
					a0 a0 c0 c0 c0 c0 c0 c0 e0 e0 e0 39 00 00 40 00
					00 0d c8 e0 e0 e0 e0 ff ff ff ff ff ff ff ff 39
					00 00 40 00 00 0d c8 20 40 40 60 60 60 80 80 80
					80 a0 a0 39 00 00 40 00 00 0d c8 a0 a0 a0 c0 c0
					c0 c0 c0 c0 e0 e0 e0 39 00 00 40 00 00 0d c8 e0
					e0 e0 e0 ff ff ff ff ff ff ff ff 39 00 00 40 00
					00 0d c8 20 40 40 60 60 60 80 80 80 80 a0 a0 39
					00 00 40 00 00 0d c8 a0 a0 a0 c0 c0 c0 c0 c0 c0
					e0 e0 e0 39 00 00 40 00 00 0d c8 e0 e0 e0 e0 ff
					ff ff ff ff ff ff ff 15 00 00 00 00 00 02 c4 00
				];
				mi,mdss-dsi-timing-switch-pwm-command = [
					15 00 00 40 00 00 02 a4 01 39 00 00 40 00 00 03
					f0 aa 14 15 00 00 40 00 00 02 65 0c 39 00 00 40
					00 00 03 b5 18 0c 39 00 00 40 00 00 05 bc 10 10
					00 1e 15 00 00 40 00 00 02 65 0c 39 00 00 40 00
					00 03 b6 0f 0b 39 00 00 40 00 00 05 bd 10 10 00
					21 15 00 00 40 00 00 02 65 0c 39 00 00 40 00 00
					05 c6 03 07 1f 03 39 00 00 40 00 00 06 ca 10 10
					00 1e 13 39 00 00 40 00 00 03 f0 aa 1b 15 00 00
					40 00 00 02 65 09 39 00 00 40 00 00 04 de 1e 01
					03 15 00 00 00 00 00 02 a4 00 15 00 00 40 00 00
					02 6c 02 39 00 00 40 00 00 03 75 c0 00 39 00 00
					40 00 00 04 71 01 00 01 39 00 00 40 00 00 03 f0
					aa 16 15 00 00 40 00 00 02 d0 00 15 00 00 40 00
					00 02 65 07 15 00 00 40 00 00 02 d1 02 15 00 00
					40 00 00 02 d2 01 15 00 00 40 00 00 02 65 02 39
					00 00 40 00 00 04 d2 03 65 0f 15 00 00 40 00 00
					02 76 01 15 00 00 40 00 00 02 77 0b 39 00 00 40
					00 00 03 f0 aa 10 15 00 00 40 00 00 02 cf 09 15
					00 00 00 00 00 02 a6 01
				];
				qcom,mdss-dsi-timing-switch-command = [
					15 00 00 40 00 00 02 a4 01 39 00 00 40 00 00 03
					f0 aa 14 15 00 00 40 00 00 02 65 0c 39 00 00 40
					00 00 03 b5 17 0b 39 00 00 40 00 00 05 bc 10 10
					00 1d 15 00 00 40 00 00 02 65 0c 39 00 00 40 00
					00 03 b6 10 0c 39 00 00 40 00 00 05 bd 10 10 00
					22 15 00 00 40 00 00 02 65 0c 39 00 00 40 00 00
					05 c6 02 06 1e 02 39 00 00 40 00 00 06 ca 10 10
					00 1f 22 39 00 00 40 00 00 03 f0 aa 1b 15 00 00
					40 00 00 02 65 09 39 00 00 40 00 00 04 de 1f 02
					02 15 00 00 00 00 00 02 a4 00 15 00 00 40 00 00
					02 6c 00 39 00 00 40 00 00 03 75 c0 00 39 00 00
					40 00 00 04 71 01 00 01 39 00 00 40 00 00 03 f0
					aa 16 15 00 00 40 00 00 02 d0 00 15 00 00 40 00
					00 02 65 01 15 00 00 40 00 00 02 d1 00 15 00 00
					40 00 00 02 d2 01 15 00 00 40 00 00 02 65 02 39
					00 00 40 00 00 04 d2 0a 53 0f 15 00 00 40 00 00
					02 76 01 15 00 00 40 00 00 02 77 03 39 00 00 40
					00 00 03 f0 aa 10 15 00 00 40 00 00 02 cf 09 39
					00 00 40 00 00 03 f0 aa 17 15 00 00 40 00 00 02
					c2 80 15 00 00 00 00 00 02 a6 01
				];
				qcom,mdss-dsi-h-sync-skew = <0>;
				qcom,mdss-dsi-panel-framerate = <60>;
				cell-index = <1>;
			};

			timing@wqhd_normal_90hz_index_02 {
				#include "dsi-panel-p1-42-0d-0b-p12-dsc-cmd-common.dtsi"
				qcom,mdss-dsi-on-command = [
					15 00 00 40 00 00 02 03 01 15 00 00 40 00 00 02
					35 00 15 00 00 40 00 00 02 53 20 39 00 00 40 00
					00 03 51 00 00 15 00 00 40 00 00 02 6f 02 15 00
					00 40 00 00 02 59 09 15 00 00 40 00 00 02 6c 00
					15 00 00 40 00 00 02 6d 00 39 00 00 40 00 00 81
					70 12 00 00 ab 30 80 0a 30 04 b0 00 10 02 58 02
					58 02 00 02 2c 00 20 01 98 00 08 00 0c 06 67 05
					b9 18 00 10 f0 07 10 20 00 06 0f 0f 33 0e 1c 2a
					38 46 54 62 69 70 77 79 7b 7d 7e 02 02 22 00 2a
					40 2a be 3a fc 3a fa 3a f8 3b 38 3b 78 3b b6 4b
					b6 4b f4 4b f4 6c 34 84 74 74 00 00 00 00 00 00
					00 00 00 00 00 00 00 00 00 00 00 00 00 00 00 00
					00 00 00 00 00 00 00 00 00 00 00 00 00 00 00 00
					00 39 00 00 40 00 00 03 ff 5a 81 15 00 00 40 00
					00 02 65 03 15 00 00 40 00 00 02 f3 04 15 00 00
					40 00 00 02 65 05 15 00 00 40 00 00 02 f3 48 39
					00 00 40 00 00 03 f0 aa 10 15 00 00 40 00 00 02
					65 0a 15 00 00 40 00 00 02 eb 10 39 00 00 40 00
					00 03 ff 5a 80 15 00 00 40 00 00 02 65 0e 15 00
					00 40 00 00 02 f9 a1 39 00 00 40 00 00 03 ff 5a
					81 15 00 00 40 00 00 02 65 02 39 00 00 40 00 00
					03 fb 63 73 39 00 00 40 00 00 03 f0 aa 10 15 00
					00 40 00 00 02 65 0b 39 00 00 40 00 00 05 d0 e4
					0f 20 40 15 00 00 40 00 00 02 65 15 39 00 00 40
					00 00 13 d1 be 40 40 40 40 0c 00 00 46 1f 1f 00
					00 40 0c 46 1f 1f 39 00 00 40 00 00 14 d9 39 68
					00 00 00 0b 0a 0d 0c 02 00 00 02 07 06 00 06 02
					0d 15 00 00 40 00 00 02 72 01 39 00 00 40 00 00
					03 ff 5a 83 15 00 00 40 00 00 02 65 0b 15 00 00
					40 00 00 02 f8 05 39 00 00 40 00 00 03 f0 aa 11
					15 00 00 40 00 00 02 c3 31 39 00 00 40 00 00 03
					f0 aa 18 15 00 00 40 00 00 02 b0 80 39 00 00 40
					00 00 03 f0 aa 19 15 00 00 40 00 00 02 c0 e0 39
					00 00 40 00 00 03 f0 aa 1a 15 00 00 40 00 00 02
					b0 01 39 00 00 40 00 00 03 f0 aa 10 39 00 00 40
					00 00 04 eb 00 00 30 39 00 00 40 00 00 08 ea 0f
					41 00 88 48 cb 01 15 00 00 40 00 00 02 65 0d 39
					00 00 40 00 00 04 ea 0c 00 01 15 00 00 40 00 00
					02 65 10 39 00 00 40 00 00 04 ea 0c 80 01 15 00
					00 40 00 00 02 65 13 39 00 00 40 00 00 04 ea c8
					ae 01 15 00 00 40 00 00 02 65 16 39 00 00 40 00
					00 04 ea 64 c1 01 15 00 00 40 00 00 02 65 19 39
					00 00 40 00 00 04 ea 98 a5 01 15 00 00 40 00 00
					02 65 28 39 00 00 40 00 00 04 ea 0c 00 00 39 00
					00 40 00 00 03 f0 aa 00 39 00 00 00 00 00 03 ff
					5a 00 05 00 00 00 78 00 01 11 39 00 00 40 00 00
					03 f0 aa 10 15 00 00 40 00 00 02 65 02 39 00 00
					40 00 00 03 cf 24 13 15 00 00 40 00 00 02 65 0b
					39 00 00 40 00 00 03 cf dd 79 39 00 00 40 00 00
					03 f0 aa 16 39 00 00 40 00 00 16 e3 00 01 00 00
					00 00 00 00 00 00 00 00 00 00 00 00 00 00 00 00
					00 39 00 00 40 00 00 16 e4 00 03 00 00 00 00 00
					00 00 00 00 00 00 00 00 00 00 00 00 00 00 39 00
					00 40 00 00 16 e5 00 04 00 00 00 00 00 00 00 00
					00 00 00 00 00 00 00 00 00 00 00 39 00 00 40 00
					00 16 e6 01 03 0b 00 00 00 00 00 00 00 00 00 00
					00 00 00 00 00 00 00 00 39 00 00 40 00 00 16 e7
					03 03 0b 0b 77 00 00 00 00 0e e0 00 00 00 00 00
					00 00 00 00 00 39 00 00 40 00 00 16 e8 02 0b 0b
					77 00 00 00 00 00 ee 00 00 00 00 00 00 00 00 00
					00 00 39 00 00 40 00 00 16 e9 02 08 08 59 00 00
					00 00 00 ee 00 00 00 00 00 00 00 00 00 00 00 39
					00 00 40 00 00 16 ea 00 0b 00 00 00 00 00 00 00
					00 00 00 00 00 00 00 00 00 00 00 00 39 00 00 40
					00 00 16 eb 02 01 03 ef 00 00 00 00 00 00 00 00
					00 00 00 00 00 00 00 00 00 39 00 00 40 00 00 16
					ec 00 01 00 00 00 00 00 00 00 40 00 00 00 00 00
					00 00 00 00 00 00 39 00 00 40 00 00 1f e0 f0 f1
					f2 f3 f4 f5 f6 00 00 00 f0 f1 f2 f3 f4 f5 f6 00
					00 00 f0 f1 f2 f3 f4 f5 f6 00 00 00 39 00 00 40
					00 00 15 ed f0 f1 f2 f3 f4 f5 f6 f7 f8 00 f0 f1
					f2 f3 f4 f5 f6 f7 f8 00 39 00 00 40 00 00 15 ee
					f0 f1 f2 f3 f4 f5 f6 f7 f8 00 f0 f1 f2 f3 f4 f5
					f6 f7 f8 00 39 00 00 40 00 00 03 f0 aa 12 15 00
					00 00 00 00 02 c7 fe 39 00 00 40 00 00 03 f0 aa
					14 15 00 00 40 00 00 02 65 0c 39 00 00 40 00 00
					03 b5 17 0b 39 00 00 40 00 00 05 bc 10 10 00 1d
					15 00 00 40 00 00 02 65 0c 39 00 00 40 00 00 03
					b6 10 0c 39 00 00 40 00 00 05 bd 10 10 00 22 15
					00 00 40 00 00 02 65 0c 39 00 00 40 00 00 05 c6
					02 06 1e 02 39 00 00 40 00 00 06 ca 10 10 00 1f
					22 39 00 00 40 00 00 03 f0 aa 1b 15 00 00 40 00
					00 02 65 09 39 00 00 00 00 00 04 de 1f 02 02 15
					00 00 40 00 00 02 6c 01 39 00 00 40 00 00 03 75
					c0 06 39 00 00 40 00 00 04 71 00 00 00 39 00 00
					40 00 00 03 f0 aa 16 15 00 00 40 00 00 02 d0 03
					15 00 00 40 00 00 02 65 04 15 00 00 40 00 00 02
					d1 02 15 00 00 40 00 00 02 d2 01 15 00 00 40 00
					00 02 65 02 39 00 00 40 00 00 04 d2 0d ca 0f 15
					00 00 40 00 00 02 76 01 15 00 00 40 00 00 02 77
					01 39 00 00 40 00 00 03 f0 aa 10 15 00 00 40 00
					00 02 cf 09 39 00 00 40 00 00 03 f0 aa 17 15 00
					00 40 00 00 02 c2 80 05 00 00 00 00 00 01 29 39
					00 00 40 00 00 03 f0 aa 17 39 00 00 40 00 00 02
					b0 b0 39 00 00 40 00 00 05 b1 08 06 06 00 39 00
					00 40 00 00 37 b2 00 40 00 00 40 00 00 20 20 00
					40 00 00 40 00 00 20 20 00 00 00 00 e0 00 00 00
					20 00 00 20 00 00 20 00 00 20 00 00 00 00 00 00
					00 00 18 00 00 18 00 00 44 00 00 00 39 00 00 40
					00 00 25 b3 88 b8 00 88 b8 80 80 c0 80 00 40 00
					00 40 00 00 40 00 08 38 00 08 38 00 00 40 00 00
					40 00 00 40 00 00 40 00 39 00 00 40 00 00 1a b4
					00 03 06 0c 18 03 06 0c 18 03 06 0c 18 03 06 0c
					18 03 06 0c 18 03 06 0c 18 39 00 00 40 00 00 0a
					b5 00 00 00 00 00 00 00 00 00 39 00 00 40 00 00
					31 b6 1f 1f 1f 1f 1f 1f 1f 1f 1f 1f 1f 1f 1f 1f
					1f 1f 1f 1f 1f 1f 1f 1f 1f 1f 1f 1f 1f 1f 1f 1f
					1f 1f 1f 1f 1f 1f 1f 1f 1f 1f 1f 1f 1f 1f 1f 1f
					1f 1f 39 00 00 00 00 00 1e b7 00 12 34 12 34 52
					34 56 34 56 74 56 78 33 94 26 64 19 98 0c cc 33
					94 26 64 19 98 0c cc 39 00 00 40 00 00 03 f0 aa
					10 15 00 00 40 00 00 02 65 0b 39 00 00 40 00 00
					03 cf dd 79 39 00 00 00 00 00 03 f0 aa 00 39 00
					00 40 00 00 03 f0 aa 19 39 00 00 40 00 00 03 c7
					00 00 15 00 00 40 00 00 02 c4 80 39 00 00 40 00
					00 0d c8 ec 00 00 00 00 00 03 60 00 00 00 00 39
					00 00 40 00 00 0d c8 03 f0 00 00 00 00 00 30 40
					00 00 00 39 00 00 40 00 00 0d c8 03 f0 00 fc 00
					00 00 10 00 00 00 00 39 00 00 40 00 00 0d c8 00
					20 00 03 f0 00 50 a0 c2 08 20 41 39 00 00 40 00
					00 0d c8 d4 00 00 00 00 00 2c 00 00 00 00 00 39
					00 00 40 00 00 0d c8 20 40 00 00 00 00 03 df fe
					00 00 00 39 00 00 40 00 00 0d c8 10 1f c1 f8 00
					00 10 10 3e 04 10 00 39 00 00 40 00 00 0d c8 04
					00 00 fb ff c0 60 82 06 14 30 c1 39 00 00 40 00
					00 0d c8 00 00 00 00 00 00 03 f0 00 00 00 00 39
					00 00 40 00 00 0d c8 f7 cf 80 00 00 00 07 ef ff
					00 00 00 39 00 00 40 00 00 0d c8 03 f0 00 fc 00
					00 03 f0 00 03 f0 00 39 00 00 40 00 00 0d c8 00
					2f bf 00 00 00 50 81 83 08 20 41 15 00 00 00 00
					00 02 c4 00 39 00 00 40 00 00 03 f0 aa 19 39 00
					00 40 00 00 03 c7 00 15 15 00 00 40 00 00 02 c4
					80 39 00 00 40 00 00 0d c8 f0 00 00 00 00 00 f8
					20 00 00 00 00 39 00 00 40 00 00 0d c8 ff ff c0
					00 00 00 f3 ef ff 00 00 00 39 00 00 40 00 00 0d
					c8 f3 ff ff fc 00 00 fb ff c0 ff f0 00 39 00 00
					40 00 00 0d c8 f7 df bf 00 0f c0 5c a1 c4 0c 20
					81 39 00 00 40 00 00 0d c8 f4 00 00 00 00 00 ff
					f0 00 00 00 00 39 00 00 40 00 00 0d c8 ff ff c0
					00 00 00 f7 ff c0 00 00 00 39 00 00 40 00 00 0d
					c8 fb ef ff 00 00 00 fb ff ff fc 00 00 39 00 00
					40 00 00 0d c8 ff ff ff ff f0 00 3c 81 84 0c 20
					41 39 00 00 40 00 00 0d c8 f4 00 00 00 00 00 f4
					00 00 00 00 00 39 00 00 40 00 00 0d c8 f8 0f c0
					00 00 00 f7 ff c0 00 00 00 39 00 00 40 00 00 0d
					c8 f7 d0 00 00 00 00 f7 ef fe ff f0 00 39 00 00
					40 00 00 0d c8 f8 0f c1 03 ff c0 5c 81 02 08 20
					40 15 00 00 00 00 00 02 c4 00 39 00 00 40 00 00
					03 f0 aa 19 39 00 00 40 00 00 03 c7 00 2a 15 00
					00 40 00 00 02 c4 80 39 00 00 40 00 00 0d c8 f4
					00 00 00 00 00 f4 00 00 00 00 00 39 00 00 40 00
					00 0d c8 f7 ef c0 00 00 00 f7 ff c0 00 00 00 39
					00 00 40 00 00 0d c8 fb f0 3f 00 00 00 f3 ef bf
					ff f0 00 39 00 00 40 00 00 0d c8 ff ff ff fc 00
					00 54 81 84 0c 20 41 39 00 00 40 00 00 0d c8 f8
					00 00 00 00 00 f7 f0 00 00 00 00 39 00 00 40 00
					00 0d c8 f7 f0 00 00 00 00 f7 ff c0 00 00 00 39
					00 00 40 00 00 0d c8 fb ff fe fc 00 00 f7 ff c0
					00 00 00 39 00 00 40 00 00 0d c8 ff ff c0 00 00
					00 50 71 43 08 10 41 39 00 00 40 00 00 0d c8 f8
					00 00 00 00 00 f7 f0 00 00 00 00 39 00 00 40 00
					00 0d c8 f3 ff 00 00 00 00 f7 b0 c0 00 00 00 39
					00 00 40 00 00 0d c8 f8 3f ff f0 00 00 fb ff ff
					fc 00 00 39 00 00 40 00 00 0d c8 ff f0 00 13 f0
					00 50 71 03 08 20 41 15 00 00 00 00 00 02 c4 00
					39 00 00 40 00 00 03 f0 aa 19 39 00 00 40 00 00
					03 c7 00 3f 15 00 00 40 00 00 02 c4 80 39 00 00
					40 00 00 0d c8 20 40 40 60 60 60 80 80 80 80 a0
					a0 39 00 00 40 00 00 0d c8 a0 a0 a0 c0 c0 c0 c0
					c0 c0 e0 e0 e0 39 00 00 40 00 00 0d c8 e0 e0 e0
					e0 ff ff ff ff ff ff ff ff 39 00 00 40 00 00 0d
					c8 1b 1c 2f 1e 4c 5b 1f 56 5c 6e a0 a0 39 00 00
					40 00 00 0d c8 a0 a0 a0 c0 c0 c0 c0 c0 c0 e0 e0
					e0 39 00 00 40 00 00 0d c8 e0 e0 e0 e0 ff ff ff
					ff ff ff ff ff 39 00 00 40 00 00 0d c8 20 40 40
					60 60 60 80 80 80 80 a0 a0 39 00 00 40 00 00 0d
					c8 a0 a0 a0 c0 c0 c0 c0 c0 c0 e0 e0 e0 39 00 00
					40 00 00 0d c8 e0 e0 e0 e0 ff ff ff ff ff ff ff
					ff 15 00 00 00 00 00 02 c4 00 39 00 00 40 00 00
					03 f0 aa 19 39 00 00 40 00 00 03 c7 00 c6 15 00
					00 40 00 00 02 c4 80 39 00 00 40 00 00 0d c8 f8
					00 00 00 00 00 d8 00 00 00 00 00 39 00 00 40 00
					00 0d c8 03 f0 00 00 00 00 00 00 40 00 00 00 39
					00 00 40 00 00 0d c8 ec 00 00 fc 00 00 00 00 00
					00 00 00 39 00 00 40 00 00 0d c8 00 00 00 03 f0
					00 50 50 c2 08 20 41 39 00 00 40 00 00 0d c8 c8
					00 00 00 00 00 00 00 00 00 00 00 39 00 00 40 00
					00 0d c8 00 40 00 00 00 00 0b df fe 00 00 00 39
					00 00 40 00 00 0d c8 fc 1f c1 f8 00 00 fc 10 3e
					04 10 00 39 00 00 40 00 00 0d c8 00 00 00 fb ff
					c0 78 82 06 14 30 c1 39 00 00 40 00 00 0d c8 00
					00 00 00 00 00 03 f0 00 00 00 00 39 00 00 40 00
					00 0d c8 f7 cf 80 00 00 00 07 ef ff 00 00 00 39
					00 00 40 00 00 0d c8 03 f0 00 fc 00 00 03 f0 00
					03 f0 00 39 00 00 40 00 00 0d c8 00 2f bf 00 00
					00 50 81 83 08 20 41 15 00 00 00 00 00 02 c4 00
					39 00 00 40 00 00 03 f0 aa 19 39 00 00 40 00 00
					03 c7 00 db 15 00 00 40 00 00 02 c4 80 39 00 00
					40 00 00 0d c8 f0 00 00 00 00 00 f8 20 00 00 00
					00 39 00 00 40 00 00 0d c8 ff ff c0 00 00 00 f3
					ef ff 00 00 00 39 00 00 40 00 00 0d c8 f3 ff ff
					fc 00 00 fb ff c0 ff f0 00 39 00 00 40 00 00 0d
					c8 f7 df bf 00 0f c0 5c a1 c4 0c 20 81 39 00 00
					40 00 00 0d c8 f8 00 00 00 00 00 ff f0 00 00 00
					00 39 00 00 40 00 00 0d c8 ff ff c0 00 00 00 f7
					ff c0 00 00 00 39 00 00 40 00 00 0d c8 fb ef ff
					00 00 00 fb ff ff fc 00 00 39 00 00 40 00 00 0d
					c8 ff ff ff ff f0 00 3c 81 84 0c 20 41 39 00 00
					40 00 00 0d c8 f4 00 00 00 00 00 f4 00 00 00 00
					00 39 00 00 40 00 00 0d c8 f8 0f c0 00 00 00 f7
					ff c0 00 00 00 39 00 00 40 00 00 0d c8 f7 d0 00
					00 00 00 f7 ef fe ff f0 00 39 00 00 40 00 00 0d
					c8 f8 0f c1 03 ff c0 5c 81 02 08 20 40 15 00 00
					00 00 00 02 c4 00 39 00 00 40 00 00 03 f0 aa 19
					39 00 00 40 00 00 03 c7 01 05 15 00 00 40 00 00
					02 c4 80 39 00 00 40 00 00 0d c8 20 40 40 60 60
					60 80 80 80 80 a0 a0 39 00 00 40 00 00 0d c8 a0
					a0 a0 c0 c0 c0 c0 c0 c0 e0 e0 e0 39 00 00 40 00
					00 0d c8 e0 e0 e0 e0 ff ff ff ff ff ff ff ff 39
					00 00 40 00 00 0d c8 20 40 40 60 60 60 80 80 80
					80 a0 a0 39 00 00 40 00 00 0d c8 a0 a0 a0 c0 c0
					c0 c0 c0 c0 e0 e0 e0 39 00 00 40 00 00 0d c8 e0
					e0 e0 e0 ff ff ff ff ff ff ff ff 39 00 00 40 00
					00 0d c8 20 40 40 60 60 60 80 80 80 80 a0 a0 39
					00 00 40 00 00 0d c8 a0 a0 a0 c0 c0 c0 c0 c0 c0
					e0 e0 e0 39 00 00 40 00 00 0d c8 e0 e0 e0 e0 ff
					ff ff ff ff ff ff ff 15 00 00 00 00 00 02 c4 00
				];
				mi,mdss-dsi-timing-switch-pwm-command = [
					15 00 00 40 00 00 02 a4 01 39 00 00 40 00 00 03
					f0 aa 14 15 00 00 40 00 00 02 65 0c 39 00 00 40
					00 00 03 b5 18 0c 39 00 00 40 00 00 05 bc 10 10
					00 1e 15 00 00 40 00 00 02 65 0c 39 00 00 40 00
					00 03 b6 0f 0b 39 00 00 40 00 00 05 bd 10 10 00
					21 15 00 00 40 00 00 02 65 0c 39 00 00 40 00 00
					05 c6 03 07 1f 03 39 00 00 40 00 00 06 ca 10 10
					00 1e 13 39 00 00 40 00 00 03 f0 aa 1b 15 00 00
					40 00 00 02 65 09 39 00 00 40 00 00 04 de 1e 01
					03 15 00 00 00 00 00 02 a4 00 15 00 00 40 00 00
					02 6c 02 39 00 00 40 00 00 03 75 c0 00 39 00 00
					40 00 00 04 71 01 10 00 39 00 00 40 00 00 03 f0
					aa 16 15 00 00 40 00 00 02 d0 00 15 00 00 40 00
					00 02 65 07 15 00 00 40 00 00 02 d1 02 15 00 00
					40 00 00 02 d2 01 15 00 00 40 00 00 02 65 02 39
					00 00 40 00 00 04 d2 03 65 0f 15 00 00 40 00 00
					02 76 01 15 00 00 40 00 00 02 77 07 39 00 00 40
					00 00 03 f0 aa 10 15 00 00 40 00 00 02 cf 09 15
					00 00 00 00 00 02 a6 01
				];
				qcom,mdss-dsi-timing-switch-command = [
					15 00 00 40 00 00 02 a4 01 39 00 00 40 00 00 03
					f0 aa 14 15 00 00 40 00 00 02 65 0c 39 00 00 40
					00 00 03 b5 17 0b 39 00 00 40 00 00 05 bc 10 10
					00 1d 15 00 00 40 00 00 02 65 0c 39 00 00 40 00
					00 03 b6 10 0c 39 00 00 40 00 00 05 bd 10 10 00
					22 15 00 00 40 00 00 02 65 0c 39 00 00 40 00 00
					05 c6 02 06 1e 02 39 00 00 40 00 00 06 ca 10 10
					00 1f 22 39 00 00 40 00 00 03 f0 aa 1b 15 00 00
					40 00 00 02 65 09 39 00 00 40 00 00 04 de 1f 02
					02 15 00 00 00 00 00 02 a4 00 15 00 00 40 00 00
					02 6c 01 39 00 00 40 00 00 03 75 c0 06 39 00 00
					40 00 00 04 71 00 00 00 39 00 00 40 00 00 03 f0
					aa 16 15 00 00 40 00 00 02 d0 03 15 00 00 40 00
					00 02 65 04 15 00 00 40 00 00 02 d1 02 15 00 00
					40 00 00 02 d2 01 15 00 00 40 00 00 02 65 02 39
					00 00 40 00 00 04 d2 0d ca 0f 15 00 00 40 00 00
					02 76 01 15 00 00 40 00 00 02 77 01 39 00 00 40
					00 00 03 f0 aa 10 15 00 00 40 00 00 02 cf 09 39
					00 00 40 00 00 03 f0 aa 17 15 00 00 40 00 00 02
					c2 80 15 00 00 00 00 00 02 a6 01
				];
				qcom,mdss-dsi-h-sync-skew = <0>;
				qcom,mdss-dsi-panel-framerate = <90>;
				cell-index = <2>;
			};

			timing@wqhd_normal_30hz_index_03 {
				#include "dsi-panel-p1-42-0d-0b-p12-dsc-cmd-common.dtsi"
				qcom,mdss-dsi-on-command = [
					15 00 00 40 00 00 02 03 01 15 00 00 40 00 00 02
					35 00 15 00 00 40 00 00 02 53 20 39 00 00 40 00
					00 03 51 00 00 15 00 00 40 00 00 02 6f 02 15 00
					00 40 00 00 02 59 09 15 00 00 40 00 00 02 6c 00
					15 00 00 40 00 00 02 6d 00 39 00 00 40 00 00 81
					70 12 00 00 ab 30 80 0a 30 04 b0 00 10 02 58 02
					58 02 00 02 2c 00 20 01 98 00 08 00 0c 06 67 05
					b9 18 00 10 f0 07 10 20 00 06 0f 0f 33 0e 1c 2a
					38 46 54 62 69 70 77 79 7b 7d 7e 02 02 22 00 2a
					40 2a be 3a fc 3a fa 3a f8 3b 38 3b 78 3b b6 4b
					b6 4b f4 4b f4 6c 34 84 74 74 00 00 00 00 00 00
					00 00 00 00 00 00 00 00 00 00 00 00 00 00 00 00
					00 00 00 00 00 00 00 00 00 00 00 00 00 00 00 00
					00 39 00 00 40 00 00 03 ff 5a 81 15 00 00 40 00
					00 02 65 03 15 00 00 40 00 00 02 f3 04 15 00 00
					40 00 00 02 65 05 15 00 00 40 00 00 02 f3 48 39
					00 00 40 00 00 03 f0 aa 10 15 00 00 40 00 00 02
					65 0a 15 00 00 40 00 00 02 eb 10 39 00 00 40 00
					00 03 ff 5a 80 15 00 00 40 00 00 02 65 0e 15 00
					00 40 00 00 02 f9 a1 39 00 00 40 00 00 03 ff 5a
					81 15 00 00 40 00 00 02 65 02 39 00 00 40 00 00
					03 fb 63 73 39 00 00 40 00 00 03 f0 aa 10 15 00
					00 40 00 00 02 65 0b 39 00 00 40 00 00 05 d0 e4
					0f 20 40 15 00 00 40 00 00 02 65 15 39 00 00 40
					00 00 13 d1 be 40 40 40 40 0c 00 00 46 1f 1f 00
					00 40 0c 46 1f 1f 39 00 00 40 00 00 14 d9 39 68
					00 00 00 0b 0a 0d 0c 02 00 00 02 07 06 00 06 02
					0d 15 00 00 40 00 00 02 72 01 39 00 00 40 00 00
					03 ff 5a 83 15 00 00 40 00 00 02 65 0b 15 00 00
					40 00 00 02 f8 05 39 00 00 40 00 00 03 f0 aa 11
					15 00 00 40 00 00 02 c3 31 39 00 00 40 00 00 03
					f0 aa 18 15 00 00 40 00 00 02 b0 80 39 00 00 40
					00 00 03 f0 aa 19 15 00 00 40 00 00 02 c0 e0 39
					00 00 40 00 00 03 f0 aa 1a 15 00 00 40 00 00 02
					b0 01 39 00 00 40 00 00 03 f0 aa 10 39 00 00 40
					00 00 04 eb 00 00 30 39 00 00 40 00 00 08 ea 0f
					41 00 88 48 cb 01 15 00 00 40 00 00 02 65 0d 39
					00 00 40 00 00 04 ea 0c 00 01 15 00 00 40 00 00
					02 65 10 39 00 00 40 00 00 04 ea 0c 80 01 15 00
					00 40 00 00 02 65 13 39 00 00 40 00 00 04 ea c8
					ae 01 15 00 00 40 00 00 02 65 16 39 00 00 40 00
					00 04 ea 64 c1 01 15 00 00 40 00 00 02 65 19 39
					00 00 40 00 00 04 ea 98 a5 01 15 00 00 40 00 00
					02 65 28 39 00 00 40 00 00 04 ea 0c 00 00 39 00
					00 40 00 00 03 f0 aa 00 39 00 00 00 00 00 03 ff
					5a 00 05 00 00 00 78 00 01 11 39 00 00 40 00 00
					03 f0 aa 10 15 00 00 40 00 00 02 65 02 39 00 00
					40 00 00 03 cf 24 13 15 00 00 40 00 00 02 65 0b
					39 00 00 40 00 00 03 cf dd 79 39 00 00 40 00 00
					03 f0 aa 16 39 00 00 40 00 00 16 e3 00 01 00 00
					00 00 00 00 00 00 00 00 00 00 00 00 00 00 00 00
					00 39 00 00 40 00 00 16 e4 00 03 00 00 00 00 00
					00 00 00 00 00 00 00 00 00 00 00 00 00 00 39 00
					00 40 00 00 16 e5 00 04 00 00 00 00 00 00 00 00
					00 00 00 00 00 00 00 00 00 00 00 39 00 00 40 00
					00 16 e6 01 03 0b 00 00 00 00 00 00 00 00 00 00
					00 00 00 00 00 00 00 00 39 00 00 40 00 00 16 e7
					03 03 0b 0b 77 00 00 00 00 0e e0 00 00 00 00 00
					00 00 00 00 00 39 00 00 40 00 00 16 e8 02 0b 0b
					77 00 00 00 00 00 ee 00 00 00 00 00 00 00 00 00
					00 00 39 00 00 40 00 00 16 e9 02 08 08 59 00 00
					00 00 00 ee 00 00 00 00 00 00 00 00 00 00 00 39
					00 00 40 00 00 16 ea 00 0b 00 00 00 00 00 00 00
					00 00 00 00 00 00 00 00 00 00 00 00 39 00 00 40
					00 00 16 eb 02 01 03 ef 00 00 00 00 00 00 00 00
					00 00 00 00 00 00 00 00 00 39 00 00 40 00 00 16
					ec 00 01 00 00 00 00 00 00 00 40 00 00 00 00 00
					00 00 00 00 00 00 39 00 00 40 00 00 1f e0 f0 f1
					f2 f3 f4 f5 f6 00 00 00 f0 f1 f2 f3 f4 f5 f6 00
					00 00 f0 f1 f2 f3 f4 f5 f6 00 00 00 39 00 00 40
					00 00 15 ed f0 f1 f2 f3 f4 f5 f6 f7 f8 00 f0 f1
					f2 f3 f4 f5 f6 f7 f8 00 39 00 00 40 00 00 15 ee
					f0 f1 f2 f3 f4 f5 f6 f7 f8 00 f0 f1 f2 f3 f4 f5
					f6 f7 f8 00 39 00 00 40 00 00 03 f0 aa 12 15 00
					00 00 00 00 02 c7 fe 39 00 00 40 00 00 03 f0 aa
					14 15 00 00 40 00 00 02 65 0c 39 00 00 40 00 00
					03 b5 17 0b 39 00 00 40 00 00 05 bc 10 10 00 1d
					15 00 00 40 00 00 02 65 0c 39 00 00 40 00 00 03
					b6 10 0c 39 00 00 40 00 00 05 bd 10 10 00 22 15
					00 00 40 00 00 02 65 0c 39 00 00 40 00 00 05 c6
					02 06 1e 02 39 00 00 40 00 00 06 ca 10 10 00 1f
					22 39 00 00 40 00 00 03 f0 aa 1b 15 00 00 40 00
					00 02 65 09 39 00 00 00 00 00 04 de 1f 02 02 15
					00 00 40 00 00 02 6c 00 39 00 00 40 00 00 03 75
					c0 01 39 00 00 40 00 00 04 71 00 00 00 39 00 00
					40 00 00 03 f0 aa 16 15 00 00 40 00 00 02 d0 00
					15 00 00 40 00 00 02 65 01 15 00 00 40 00 00 02
					d1 01 15 00 00 40 00 00 02 d2 01 15 00 00 40 00
					00 02 65 02 39 00 00 40 00 00 04 d2 0a 53 0f 15
					00 00 40 00 00 02 76 01 15 00 00 40 00 00 02 77
					07 39 00 00 40 00 00 03 f0 aa 10 15 00 00 40 00
					00 02 cf 09 39 00 00 40 00 00 03 f0 aa 17 15 00
					00 40 00 00 02 c2 80 05 00 00 00 00 00 01 29 39
					00 00 40 00 00 03 f0 aa 17 39 00 00 40 00 00 02
					b0 b0 39 00 00 40 00 00 05 b1 08 06 06 00 39 00
					00 40 00 00 37 b2 00 40 00 00 40 00 00 20 20 00
					40 00 00 40 00 00 20 20 00 00 00 00 e0 00 00 00
					20 00 00 20 00 00 20 00 00 20 00 00 00 00 00 00
					00 00 18 00 00 18 00 00 44 00 00 00 39 00 00 40
					00 00 25 b3 88 b8 00 88 b8 80 80 c0 80 00 40 00
					00 40 00 00 40 00 08 38 00 08 38 00 00 40 00 00
					40 00 00 40 00 00 40 00 39 00 00 40 00 00 1a b4
					00 03 06 0c 18 03 06 0c 18 03 06 0c 18 03 06 0c
					18 03 06 0c 18 03 06 0c 18 39 00 00 40 00 00 0a
					b5 00 00 00 00 00 00 00 00 00 39 00 00 40 00 00
					31 b6 1f 1f 1f 1f 1f 1f 1f 1f 1f 1f 1f 1f 1f 1f
					1f 1f 1f 1f 1f 1f 1f 1f 1f 1f 1f 1f 1f 1f 1f 1f
					1f 1f 1f 1f 1f 1f 1f 1f 1f 1f 1f 1f 1f 1f 1f 1f
					1f 1f 39 00 00 00 00 00 1e b7 00 12 34 12 34 52
					34 56 34 56 74 56 78 33 94 26 64 19 98 0c cc 33
					94 26 64 19 98 0c cc 39 00 00 40 00 00 03 f0 aa
					10 15 00 00 40 00 00 02 65 0b 39 00 00 40 00 00
					03 cf dd 79 39 00 00 00 00 00 03 f0 aa 00 39 00
					00 40 00 00 03 f0 aa 19 39 00 00 40 00 00 03 c7
					00 00 15 00 00 40 00 00 02 c4 80 39 00 00 40 00
					00 0d c8 ec 00 00 00 00 00 03 60 00 00 00 00 39
					00 00 40 00 00 0d c8 03 f0 00 00 00 00 00 30 40
					00 00 00 39 00 00 40 00 00 0d c8 03 f0 00 fc 00
					00 00 10 00 00 00 00 39 00 00 40 00 00 0d c8 00
					20 00 03 f0 00 50 a0 c2 08 20 41 39 00 00 40 00
					00 0d c8 d4 00 00 00 00 00 2c 00 00 00 00 00 39
					00 00 40 00 00 0d c8 20 40 00 00 00 00 03 df fe
					00 00 00 39 00 00 40 00 00 0d c8 10 1f c1 f8 00
					00 10 10 3e 04 10 00 39 00 00 40 00 00 0d c8 04
					00 00 fb ff c0 60 82 06 14 30 c1 39 00 00 40 00
					00 0d c8 00 00 00 00 00 00 03 f0 00 00 00 00 39
					00 00 40 00 00 0d c8 f7 cf 80 00 00 00 07 ef ff
					00 00 00 39 00 00 40 00 00 0d c8 03 f0 00 fc 00
					00 03 f0 00 03 f0 00 39 00 00 40 00 00 0d c8 00
					2f bf 00 00 00 50 81 83 08 20 41 15 00 00 00 00
					00 02 c4 00 39 00 00 40 00 00 03 f0 aa 19 39 00
					00 40 00 00 03 c7 00 15 15 00 00 40 00 00 02 c4
					80 39 00 00 40 00 00 0d c8 f0 00 00 00 00 00 f8
					20 00 00 00 00 39 00 00 40 00 00 0d c8 ff ff c0
					00 00 00 f3 ef ff 00 00 00 39 00 00 40 00 00 0d
					c8 f3 ff ff fc 00 00 fb ff c0 ff f0 00 39 00 00
					40 00 00 0d c8 f7 df bf 00 0f c0 5c a1 c4 0c 20
					81 39 00 00 40 00 00 0d c8 f4 00 00 00 00 00 ff
					f0 00 00 00 00 39 00 00 40 00 00 0d c8 ff ff c0
					00 00 00 f7 ff c0 00 00 00 39 00 00 40 00 00 0d
					c8 fb ef ff 00 00 00 fb ff ff fc 00 00 39 00 00
					40 00 00 0d c8 ff ff ff ff f0 00 3c 81 84 0c 20
					41 39 00 00 40 00 00 0d c8 f4 00 00 00 00 00 f4
					00 00 00 00 00 39 00 00 40 00 00 0d c8 f8 0f c0
					00 00 00 f7 ff c0 00 00 00 39 00 00 40 00 00 0d
					c8 f7 d0 00 00 00 00 f7 ef fe ff f0 00 39 00 00
					40 00 00 0d c8 f8 0f c1 03 ff c0 5c 81 02 08 20
					40 15 00 00 00 00 00 02 c4 00 39 00 00 40 00 00
					03 f0 aa 19 39 00 00 40 00 00 03 c7 00 2a 15 00
					00 40 00 00 02 c4 80 39 00 00 40 00 00 0d c8 f4
					00 00 00 00 00 f4 00 00 00 00 00 39 00 00 40 00
					00 0d c8 f7 ef c0 00 00 00 f7 ff c0 00 00 00 39
					00 00 40 00 00 0d c8 fb f0 3f 00 00 00 f3 ef bf
					ff f0 00 39 00 00 40 00 00 0d c8 ff ff ff fc 00
					00 54 81 84 0c 20 41 39 00 00 40 00 00 0d c8 f8
					00 00 00 00 00 f7 f0 00 00 00 00 39 00 00 40 00
					00 0d c8 f7 f0 00 00 00 00 f7 ff c0 00 00 00 39
					00 00 40 00 00 0d c8 fb ff fe fc 00 00 f7 ff c0
					00 00 00 39 00 00 40 00 00 0d c8 ff ff c0 00 00
					00 50 71 43 08 10 41 39 00 00 40 00 00 0d c8 f8
					00 00 00 00 00 f7 f0 00 00 00 00 39 00 00 40 00
					00 0d c8 f3 ff 00 00 00 00 f7 b0 c0 00 00 00 39
					00 00 40 00 00 0d c8 f8 3f ff f0 00 00 fb ff ff
					fc 00 00 39 00 00 40 00 00 0d c8 ff f0 00 13 f0
					00 50 71 03 08 20 41 15 00 00 00 00 00 02 c4 00
					39 00 00 40 00 00 03 f0 aa 19 39 00 00 40 00 00
					03 c7 00 3f 15 00 00 40 00 00 02 c4 80 39 00 00
					40 00 00 0d c8 20 40 40 60 60 60 80 80 80 80 a0
					a0 39 00 00 40 00 00 0d c8 a0 a0 a0 c0 c0 c0 c0
					c0 c0 e0 e0 e0 39 00 00 40 00 00 0d c8 e0 e0 e0
					e0 ff ff ff ff ff ff ff ff 39 00 00 40 00 00 0d
					c8 1b 1c 2f 1e 4c 5b 1f 56 5c 6e a0 a0 39 00 00
					40 00 00 0d c8 a0 a0 a0 c0 c0 c0 c0 c0 c0 e0 e0
					e0 39 00 00 40 00 00 0d c8 e0 e0 e0 e0 ff ff ff
					ff ff ff ff ff 39 00 00 40 00 00 0d c8 20 40 40
					60 60 60 80 80 80 80 a0 a0 39 00 00 40 00 00 0d
					c8 a0 a0 a0 c0 c0 c0 c0 c0 c0 e0 e0 e0 39 00 00
					40 00 00 0d c8 e0 e0 e0 e0 ff ff ff ff ff ff ff
					ff 15 00 00 00 00 00 02 c4 00 39 00 00 40 00 00
					03 f0 aa 19 39 00 00 40 00 00 03 c7 00 c6 15 00
					00 40 00 00 02 c4 80 39 00 00 40 00 00 0d c8 f8
					00 00 00 00 00 d8 00 00 00 00 00 39 00 00 40 00
					00 0d c8 03 f0 00 00 00 00 00 00 40 00 00 00 39
					00 00 40 00 00 0d c8 ec 00 00 fc 00 00 00 00 00
					00 00 00 39 00 00 40 00 00 0d c8 00 00 00 03 f0
					00 50 50 c2 08 20 41 39 00 00 40 00 00 0d c8 c8
					00 00 00 00 00 00 00 00 00 00 00 39 00 00 40 00
					00 0d c8 00 40 00 00 00 00 0b df fe 00 00 00 39
					00 00 40 00 00 0d c8 fc 1f c1 f8 00 00 fc 10 3e
					04 10 00 39 00 00 40 00 00 0d c8 00 00 00 fb ff
					c0 78 82 06 14 30 c1 39 00 00 40 00 00 0d c8 00
					00 00 00 00 00 03 f0 00 00 00 00 39 00 00 40 00
					00 0d c8 f7 cf 80 00 00 00 07 ef ff 00 00 00 39
					00 00 40 00 00 0d c8 03 f0 00 fc 00 00 03 f0 00
					03 f0 00 39 00 00 40 00 00 0d c8 00 2f bf 00 00
					00 50 81 83 08 20 41 15 00 00 00 00 00 02 c4 00
					39 00 00 40 00 00 03 f0 aa 19 39 00 00 40 00 00
					03 c7 00 db 15 00 00 40 00 00 02 c4 80 39 00 00
					40 00 00 0d c8 f0 00 00 00 00 00 f8 20 00 00 00
					00 39 00 00 40 00 00 0d c8 ff ff c0 00 00 00 f3
					ef ff 00 00 00 39 00 00 40 00 00 0d c8 f3 ff ff
					fc 00 00 fb ff c0 ff f0 00 39 00 00 40 00 00 0d
					c8 f7 df bf 00 0f c0 5c a1 c4 0c 20 81 39 00 00
					40 00 00 0d c8 f8 00 00 00 00 00 ff f0 00 00 00
					00 39 00 00 40 00 00 0d c8 ff ff c0 00 00 00 f7
					ff c0 00 00 00 39 00 00 40 00 00 0d c8 fb ef ff
					00 00 00 fb ff ff fc 00 00 39 00 00 40 00 00 0d
					c8 ff ff ff ff f0 00 3c 81 84 0c 20 41 39 00 00
					40 00 00 0d c8 f4 00 00 00 00 00 f4 00 00 00 00
					00 39 00 00 40 00 00 0d c8 f8 0f c0 00 00 00 f7
					ff c0 00 00 00 39 00 00 40 00 00 0d c8 f7 d0 00
					00 00 00 f7 ef fe ff f0 00 39 00 00 40 00 00 0d
					c8 f8 0f c1 03 ff c0 5c 81 02 08 20 40 15 00 00
					00 00 00 02 c4 00 39 00 00 40 00 00 03 f0 aa 19
					39 00 00 40 00 00 03 c7 01 05 15 00 00 40 00 00
					02 c4 80 39 00 00 40 00 00 0d c8 20 40 40 60 60
					60 80 80 80 80 a0 a0 39 00 00 40 00 00 0d c8 a0
					a0 a0 c0 c0 c0 c0 c0 c0 e0 e0 e0 39 00 00 40 00
					00 0d c8 e0 e0 e0 e0 ff ff ff ff ff ff ff ff 39
					00 00 40 00 00 0d c8 20 40 40 60 60 60 80 80 80
					80 a0 a0 39 00 00 40 00 00 0d c8 a0 a0 a0 c0 c0
					c0 c0 c0 c0 e0 e0 e0 39 00 00 40 00 00 0d c8 e0
					e0 e0 e0 ff ff ff ff ff ff ff ff 39 00 00 40 00
					00 0d c8 20 40 40 60 60 60 80 80 80 80 a0 a0 39
					00 00 40 00 00 0d c8 a0 a0 a0 c0 c0 c0 c0 c0 c0
					e0 e0 e0 39 00 00 40 00 00 0d c8 e0 e0 e0 e0 ff
					ff ff ff ff ff ff ff 15 00 00 00 00 00 02 c4 00
				];
				mi,mdss-dsi-timing-switch-pwm-command = [
					15 00 00 40 00 00 02 a4 01 39 00 00 40 00 00 03
					f0 aa 14 15 00 00 40 00 00 02 65 0c 39 00 00 40
					00 00 03 b5 18 0c 39 00 00 40 00 00 05 bc 10 10
					00 1e 15 00 00 40 00 00 02 65 0c 39 00 00 40 00
					00 03 b6 0f 0b 39 00 00 40 00 00 05 bd 10 10 00
					21 15 00 00 40 00 00 02 65 0c 39 00 00 40 00 00
					05 c6 03 07 1f 03 39 00 00 40 00 00 06 ca 10 10
					00 1e 13 39 00 00 40 00 00 03 f0 aa 1b 15 00 00
					40 00 00 02 65 09 39 00 00 40 00 00 04 de 1e 01
					03 15 00 00 00 00 00 02 a4 00 15 00 00 40 00 00
					02 6c 02 39 00 00 40 00 00 03 75 c0 01 39 00 00
					40 00 00 04 71 00 00 00 39 00 00 40 00 00 03 f0
					aa 16 15 00 00 40 00 00 02 d0 00 15 00 00 40 00
					00 02 65 07 15 00 00 40 00 00 02 d1 05 15 00 00
					40 00 00 02 d2 01 15 00 00 40 00 00 02 65 02 39
					00 00 40 00 00 04 d2 03 65 0f 15 00 00 40 00 00
					02 76 01 15 00 00 40 00 00 02 77 17 39 00 00 40
					00 00 03 f0 aa 10 15 00 00 40 00 00 02 cf 09 15
					00 00 00 00 00 02 a6 01
				];
				qcom,mdss-dsi-timing-switch-command = [
					15 00 00 40 00 00 02 a4 01 39 00 00 40 00 00 03
					f0 aa 14 15 00 00 40 00 00 02 65 0c 39 00 00 40
					00 00 03 b5 17 0b 39 00 00 40 00 00 05 bc 10 10
					00 1d 15 00 00 40 00 00 02 65 0c 39 00 00 40 00
					00 03 b6 10 0c 39 00 00 40 00 00 05 bd 10 10 00
					22 15 00 00 40 00 00 02 65 0c 39 00 00 40 00 00
					05 c6 02 06 1e 02 39 00 00 40 00 00 06 ca 10 10
					00 1f 22 39 00 00 40 00 00 03 f0 aa 1b 15 00 00
					40 00 00 02 65 09 39 00 00 40 00 00 04 de 1f 02
					02 15 00 00 00 00 00 02 a4 00 15 00 00 40 00 00
					02 6c 00 39 00 00 40 00 00 03 75 c0 01 39 00 00
					40 00 00 04 71 00 00 00 39 00 00 40 00 00 03 f0
					aa 16 15 00 00 40 00 00 02 d0 00 15 00 00 40 00
					00 02 65 01 15 00 00 40 00 00 02 d1 01 15 00 00
					40 00 00 02 d2 01 15 00 00 40 00 00 02 65 02 39
					00 00 40 00 00 04 d2 0a 53 0f 15 00 00 40 00 00
					02 76 01 15 00 00 40 00 00 02 77 07 39 00 00 40
					00 00 03 f0 aa 10 15 00 00 40 00 00 02 cf 09 39
					00 00 40 00 00 03 f0 aa 17 15 00 00 40 00 00 02
					c2 80 15 00 00 00 00 00 02 a6 01
				];
				qcom,mdss-dsi-h-sync-skew = <0>;
				qcom,mdss-dsi-panel-framerate = <30>;
				cell-index = <3>;
			};

			timing@wqhd_normal_24hz_index_04 {
				#include "dsi-panel-p1-42-0d-0b-p12-dsc-cmd-common.dtsi"
				qcom,mdss-dsi-on-command = [
					15 00 00 40 00 00 02 03 01 15 00 00 40 00 00 02
					35 00 15 00 00 40 00 00 02 53 20 39 00 00 40 00
					00 03 51 00 00 15 00 00 40 00 00 02 6f 02 15 00
					00 40 00 00 02 59 09 15 00 00 40 00 00 02 6c 00
					15 00 00 40 00 00 02 6d 00 39 00 00 40 00 00 81
					70 12 00 00 ab 30 80 0a 30 04 b0 00 10 02 58 02
					58 02 00 02 2c 00 20 01 98 00 08 00 0c 06 67 05
					b9 18 00 10 f0 07 10 20 00 06 0f 0f 33 0e 1c 2a
					38 46 54 62 69 70 77 79 7b 7d 7e 02 02 22 00 2a
					40 2a be 3a fc 3a fa 3a f8 3b 38 3b 78 3b b6 4b
					b6 4b f4 4b f4 6c 34 84 74 74 00 00 00 00 00 00
					00 00 00 00 00 00 00 00 00 00 00 00 00 00 00 00
					00 00 00 00 00 00 00 00 00 00 00 00 00 00 00 00
					00 39 00 00 40 00 00 03 ff 5a 81 15 00 00 40 00
					00 02 65 03 15 00 00 40 00 00 02 f3 04 15 00 00
					40 00 00 02 65 05 15 00 00 40 00 00 02 f3 48 39
					00 00 40 00 00 03 f0 aa 10 15 00 00 40 00 00 02
					65 0a 15 00 00 40 00 00 02 eb 10 39 00 00 40 00
					00 03 ff 5a 80 15 00 00 40 00 00 02 65 0e 15 00
					00 40 00 00 02 f9 a1 39 00 00 40 00 00 03 ff 5a
					81 15 00 00 40 00 00 02 65 02 39 00 00 40 00 00
					03 fb 63 73 39 00 00 40 00 00 03 f0 aa 10 15 00
					00 40 00 00 02 65 0b 39 00 00 40 00 00 05 d0 e4
					0f 20 40 15 00 00 40 00 00 02 65 15 39 00 00 40
					00 00 13 d1 be 40 40 40 40 0c 00 00 46 1f 1f 00
					00 40 0c 46 1f 1f 39 00 00 40 00 00 14 d9 39 68
					00 00 00 0b 0a 0d 0c 02 00 00 02 07 06 00 06 02
					0d 15 00 00 40 00 00 02 72 01 39 00 00 40 00 00
					03 ff 5a 83 15 00 00 40 00 00 02 65 0b 15 00 00
					40 00 00 02 f8 05 39 00 00 40 00 00 03 f0 aa 11
					15 00 00 40 00 00 02 c3 31 39 00 00 40 00 00 03
					f0 aa 18 15 00 00 40 00 00 02 b0 80 39 00 00 40
					00 00 03 f0 aa 19 15 00 00 40 00 00 02 c0 e0 39
					00 00 40 00 00 03 f0 aa 1a 15 00 00 40 00 00 02
					b0 01 39 00 00 40 00 00 03 f0 aa 10 39 00 00 40
					00 00 04 eb 00 00 30 39 00 00 40 00 00 08 ea 0f
					41 00 88 48 cb 01 15 00 00 40 00 00 02 65 0d 39
					00 00 40 00 00 04 ea 0c 00 01 15 00 00 40 00 00
					02 65 10 39 00 00 40 00 00 04 ea 0c 80 01 15 00
					00 40 00 00 02 65 13 39 00 00 40 00 00 04 ea c8
					ae 01 15 00 00 40 00 00 02 65 16 39 00 00 40 00
					00 04 ea 64 c1 01 15 00 00 40 00 00 02 65 19 39
					00 00 40 00 00 04 ea 98 a5 01 15 00 00 40 00 00
					02 65 28 39 00 00 40 00 00 04 ea 0c 00 00 39 00
					00 40 00 00 03 f0 aa 00 39 00 00 00 00 00 03 ff
					5a 00 05 00 00 00 78 00 01 11 39 00 00 40 00 00
					03 f0 aa 10 15 00 00 40 00 00 02 65 02 39 00 00
					40 00 00 03 cf 24 13 15 00 00 40 00 00 02 65 0b
					39 00 00 40 00 00 03 cf dd 79 39 00 00 40 00 00
					03 f0 aa 16 39 00 00 40 00 00 16 e3 00 01 00 00
					00 00 00 00 00 00 00 00 00 00 00 00 00 00 00 00
					00 39 00 00 40 00 00 16 e4 00 03 00 00 00 00 00
					00 00 00 00 00 00 00 00 00 00 00 00 00 00 39 00
					00 40 00 00 16 e5 00 04 00 00 00 00 00 00 00 00
					00 00 00 00 00 00 00 00 00 00 00 39 00 00 40 00
					00 16 e6 01 03 0b 00 00 00 00 00 00 00 00 00 00
					00 00 00 00 00 00 00 00 39 00 00 40 00 00 16 e7
					03 03 0b 0b 77 00 00 00 00 0e e0 00 00 00 00 00
					00 00 00 00 00 39 00 00 40 00 00 16 e8 02 0b 0b
					77 00 00 00 00 00 ee 00 00 00 00 00 00 00 00 00
					00 00 39 00 00 40 00 00 16 e9 02 08 08 59 00 00
					00 00 00 ee 00 00 00 00 00 00 00 00 00 00 00 39
					00 00 40 00 00 16 ea 00 0b 00 00 00 00 00 00 00
					00 00 00 00 00 00 00 00 00 00 00 00 39 00 00 40
					00 00 16 eb 02 01 03 ef 00 00 00 00 00 00 00 00
					00 00 00 00 00 00 00 00 00 39 00 00 40 00 00 16
					ec 00 01 00 00 00 00 00 00 00 40 00 00 00 00 00
					00 00 00 00 00 00 39 00 00 40 00 00 1f e0 f0 f1
					f2 f3 f4 f5 f6 00 00 00 f0 f1 f2 f3 f4 f5 f6 00
					00 00 f0 f1 f2 f3 f4 f5 f6 00 00 00 39 00 00 40
					00 00 15 ed f0 f1 f2 f3 f4 f5 f6 f7 f8 00 f0 f1
					f2 f3 f4 f5 f6 f7 f8 00 39 00 00 40 00 00 15 ee
					f0 f1 f2 f3 f4 f5 f6 f7 f8 00 f0 f1 f2 f3 f4 f5
					f6 f7 f8 00 39 00 00 40 00 00 03 f0 aa 12 15 00
					00 00 00 00 02 c7 fe 39 00 00 40 00 00 03 f0 aa
					14 15 00 00 40 00 00 02 65 0c 39 00 00 40 00 00
					03 b5 17 0b 39 00 00 40 00 00 05 bc 10 10 00 1d
					15 00 00 40 00 00 02 65 0c 39 00 00 40 00 00 03
					b6 10 0c 39 00 00 40 00 00 05 bd 10 10 00 22 15
					00 00 40 00 00 02 65 0c 39 00 00 40 00 00 05 c6
					02 06 1e 02 39 00 00 40 00 00 06 ca 10 10 00 1f
					22 39 00 00 40 00 00 03 f0 aa 1b 15 00 00 40 00
					00 02 65 09 39 00 00 00 00 00 04 de 1f 02 02 15
					00 00 40 00 00 02 6c 00 39 00 00 40 00 00 03 75
					c0 02 39 00 00 40 00 00 04 71 00 00 00 39 00 00
					40 00 00 03 f0 aa 16 15 00 00 40 00 00 02 d0 00
					15 00 00 40 00 00 02 65 01 15 00 00 40 00 00 02
					d1 01 15 00 00 40 00 00 02 d2 01 15 00 00 40 00
					00 02 65 02 39 00 00 40 00 00 04 d2 0a 53 0f 15
					00 00 40 00 00 02 76 01 15 00 00 40 00 00 02 77
					09 39 00 00 40 00 00 03 f0 aa 10 15 00 00 40 00
					00 02 cf 09 39 00 00 40 00 00 03 f0 aa 17 15 00
					00 40 00 00 02 c2 80 05 00 00 00 00 00 01 29 39
					00 00 40 00 00 03 f0 aa 17 39 00 00 40 00 00 02
					b0 b0 39 00 00 40 00 00 05 b1 08 06 06 00 39 00
					00 40 00 00 37 b2 00 40 00 00 40 00 00 20 20 00
					40 00 00 40 00 00 20 20 00 00 00 00 e0 00 00 00
					20 00 00 20 00 00 20 00 00 20 00 00 00 00 00 00
					00 00 18 00 00 18 00 00 44 00 00 00 39 00 00 40
					00 00 25 b3 88 b8 00 88 b8 80 80 c0 80 00 40 00
					00 40 00 00 40 00 08 38 00 08 38 00 00 40 00 00
					40 00 00 40 00 00 40 00 39 00 00 40 00 00 1a b4
					00 03 06 0c 18 03 06 0c 18 03 06 0c 18 03 06 0c
					18 03 06 0c 18 03 06 0c 18 39 00 00 40 00 00 0a
					b5 00 00 00 00 00 00 00 00 00 39 00 00 40 00 00
					31 b6 1f 1f 1f 1f 1f 1f 1f 1f 1f 1f 1f 1f 1f 1f
					1f 1f 1f 1f 1f 1f 1f 1f 1f 1f 1f 1f 1f 1f 1f 1f
					1f 1f 1f 1f 1f 1f 1f 1f 1f 1f 1f 1f 1f 1f 1f 1f
					1f 1f 39 00 00 00 00 00 1e b7 00 12 34 12 34 52
					34 56 34 56 74 56 78 33 94 26 64 19 98 0c cc 33
					94 26 64 19 98 0c cc 39 00 00 40 00 00 03 f0 aa
					10 15 00 00 40 00 00 02 65 0b 39 00 00 40 00 00
					03 cf dd 79 39 00 00 00 00 00 03 f0 aa 00 39 00
					00 40 00 00 03 f0 aa 19 39 00 00 40 00 00 03 c7
					00 00 15 00 00 40 00 00 02 c4 80 39 00 00 40 00
					00 0d c8 ec 00 00 00 00 00 03 60 00 00 00 00 39
					00 00 40 00 00 0d c8 03 f0 00 00 00 00 00 30 40
					00 00 00 39 00 00 40 00 00 0d c8 03 f0 00 fc 00
					00 00 10 00 00 00 00 39 00 00 40 00 00 0d c8 00
					20 00 03 f0 00 50 a0 c2 08 20 41 39 00 00 40 00
					00 0d c8 d4 00 00 00 00 00 2c 00 00 00 00 00 39
					00 00 40 00 00 0d c8 20 40 00 00 00 00 03 df fe
					00 00 00 39 00 00 40 00 00 0d c8 10 1f c1 f8 00
					00 10 10 3e 04 10 00 39 00 00 40 00 00 0d c8 04
					00 00 fb ff c0 60 82 06 14 30 c1 39 00 00 40 00
					00 0d c8 00 00 00 00 00 00 03 f0 00 00 00 00 39
					00 00 40 00 00 0d c8 f7 cf 80 00 00 00 07 ef ff
					00 00 00 39 00 00 40 00 00 0d c8 03 f0 00 fc 00
					00 03 f0 00 03 f0 00 39 00 00 40 00 00 0d c8 00
					2f bf 00 00 00 50 81 83 08 20 41 15 00 00 00 00
					00 02 c4 00 39 00 00 40 00 00 03 f0 aa 19 39 00
					00 40 00 00 03 c7 00 15 15 00 00 40 00 00 02 c4
					80 39 00 00 40 00 00 0d c8 f0 00 00 00 00 00 f8
					20 00 00 00 00 39 00 00 40 00 00 0d c8 ff ff c0
					00 00 00 f3 ef ff 00 00 00 39 00 00 40 00 00 0d
					c8 f3 ff ff fc 00 00 fb ff c0 ff f0 00 39 00 00
					40 00 00 0d c8 f7 df bf 00 0f c0 5c a1 c4 0c 20
					81 39 00 00 40 00 00 0d c8 f4 00 00 00 00 00 ff
					f0 00 00 00 00 39 00 00 40 00 00 0d c8 ff ff c0
					00 00 00 f7 ff c0 00 00 00 39 00 00 40 00 00 0d
					c8 fb ef ff 00 00 00 fb ff ff fc 00 00 39 00 00
					40 00 00 0d c8 ff ff ff ff f0 00 3c 81 84 0c 20
					41 39 00 00 40 00 00 0d c8 f4 00 00 00 00 00 f4
					00 00 00 00 00 39 00 00 40 00 00 0d c8 f8 0f c0
					00 00 00 f7 ff c0 00 00 00 39 00 00 40 00 00 0d
					c8 f7 d0 00 00 00 00 f7 ef fe ff f0 00 39 00 00
					40 00 00 0d c8 f8 0f c1 03 ff c0 5c 81 02 08 20
					40 15 00 00 00 00 00 02 c4 00 39 00 00 40 00 00
					03 f0 aa 19 39 00 00 40 00 00 03 c7 00 2a 15 00
					00 40 00 00 02 c4 80 39 00 00 40 00 00 0d c8 f4
					00 00 00 00 00 f4 00 00 00 00 00 39 00 00 40 00
					00 0d c8 f7 ef c0 00 00 00 f7 ff c0 00 00 00 39
					00 00 40 00 00 0d c8 fb f0 3f 00 00 00 f3 ef bf
					ff f0 00 39 00 00 40 00 00 0d c8 ff ff ff fc 00
					00 54 81 84 0c 20 41 39 00 00 40 00 00 0d c8 f8
					00 00 00 00 00 f7 f0 00 00 00 00 39 00 00 40 00
					00 0d c8 f7 f0 00 00 00 00 f7 ff c0 00 00 00 39
					00 00 40 00 00 0d c8 fb ff fe fc 00 00 f7 ff c0
					00 00 00 39 00 00 40 00 00 0d c8 ff ff c0 00 00
					00 50 71 43 08 10 41 39 00 00 40 00 00 0d c8 f8
					00 00 00 00 00 f7 f0 00 00 00 00 39 00 00 40 00
					00 0d c8 f3 ff 00 00 00 00 f7 b0 c0 00 00 00 39
					00 00 40 00 00 0d c8 f8 3f ff f0 00 00 fb ff ff
					fc 00 00 39 00 00 40 00 00 0d c8 ff f0 00 13 f0
					00 50 71 03 08 20 41 15 00 00 00 00 00 02 c4 00
					39 00 00 40 00 00 03 f0 aa 19 39 00 00 40 00 00
					03 c7 00 3f 15 00 00 40 00 00 02 c4 80 39 00 00
					40 00 00 0d c8 20 40 40 60 60 60 80 80 80 80 a0
					a0 39 00 00 40 00 00 0d c8 a0 a0 a0 c0 c0 c0 c0
					c0 c0 e0 e0 e0 39 00 00 40 00 00 0d c8 e0 e0 e0
					e0 ff ff ff ff ff ff ff ff 39 00 00 40 00 00 0d
					c8 1b 1c 2f 1e 4c 5b 1f 56 5c 6e a0 a0 39 00 00
					40 00 00 0d c8 a0 a0 a0 c0 c0 c0 c0 c0 c0 e0 e0
					e0 39 00 00 40 00 00 0d c8 e0 e0 e0 e0 ff ff ff
					ff ff ff ff ff 39 00 00 40 00 00 0d c8 20 40 40
					60 60 60 80 80 80 80 a0 a0 39 00 00 40 00 00 0d
					c8 a0 a0 a0 c0 c0 c0 c0 c0 c0 e0 e0 e0 39 00 00
					40 00 00 0d c8 e0 e0 e0 e0 ff ff ff ff ff ff ff
					ff 15 00 00 00 00 00 02 c4 00 39 00 00 40 00 00
					03 f0 aa 19 39 00 00 40 00 00 03 c7 00 c6 15 00
					00 40 00 00 02 c4 80 39 00 00 40 00 00 0d c8 f8
					00 00 00 00 00 d8 00 00 00 00 00 39 00 00 40 00
					00 0d c8 03 f0 00 00 00 00 00 00 40 00 00 00 39
					00 00 40 00 00 0d c8 ec 00 00 fc 00 00 00 00 00
					00 00 00 39 00 00 40 00 00 0d c8 00 00 00 03 f0
					00 50 50 c2 08 20 41 39 00 00 40 00 00 0d c8 c8
					00 00 00 00 00 00 00 00 00 00 00 39 00 00 40 00
					00 0d c8 00 40 00 00 00 00 0b df fe 00 00 00 39
					00 00 40 00 00 0d c8 fc 1f c1 f8 00 00 fc 10 3e
					04 10 00 39 00 00 40 00 00 0d c8 00 00 00 fb ff
					c0 78 82 06 14 30 c1 39 00 00 40 00 00 0d c8 00
					00 00 00 00 00 03 f0 00 00 00 00 39 00 00 40 00
					00 0d c8 f7 cf 80 00 00 00 07 ef ff 00 00 00 39
					00 00 40 00 00 0d c8 03 f0 00 fc 00 00 03 f0 00
					03 f0 00 39 00 00 40 00 00 0d c8 00 2f bf 00 00
					00 50 81 83 08 20 41 15 00 00 00 00 00 02 c4 00
					39 00 00 40 00 00 03 f0 aa 19 39 00 00 40 00 00
					03 c7 00 db 15 00 00 40 00 00 02 c4 80 39 00 00
					40 00 00 0d c8 f0 00 00 00 00 00 f8 20 00 00 00
					00 39 00 00 40 00 00 0d c8 ff ff c0 00 00 00 f3
					ef ff 00 00 00 39 00 00 40 00 00 0d c8 f3 ff ff
					fc 00 00 fb ff c0 ff f0 00 39 00 00 40 00 00 0d
					c8 f7 df bf 00 0f c0 5c a1 c4 0c 20 81 39 00 00
					40 00 00 0d c8 f8 00 00 00 00 00 ff f0 00 00 00
					00 39 00 00 40 00 00 0d c8 ff ff c0 00 00 00 f7
					ff c0 00 00 00 39 00 00 40 00 00 0d c8 fb ef ff
					00 00 00 fb ff ff fc 00 00 39 00 00 40 00 00 0d
					c8 ff ff ff ff f0 00 3c 81 84 0c 20 41 39 00 00
					40 00 00 0d c8 f4 00 00 00 00 00 f4 00 00 00 00
					00 39 00 00 40 00 00 0d c8 f8 0f c0 00 00 00 f7
					ff c0 00 00 00 39 00 00 40 00 00 0d c8 f7 d0 00
					00 00 00 f7 ef fe ff f0 00 39 00 00 40 00 00 0d
					c8 f8 0f c1 03 ff c0 5c 81 02 08 20 40 15 00 00
					00 00 00 02 c4 00 39 00 00 40 00 00 03 f0 aa 19
					39 00 00 40 00 00 03 c7 01 05 15 00 00 40 00 00
					02 c4 80 39 00 00 40 00 00 0d c8 20 40 40 60 60
					60 80 80 80 80 a0 a0 39 00 00 40 00 00 0d c8 a0
					a0 a0 c0 c0 c0 c0 c0 c0 e0 e0 e0 39 00 00 40 00
					00 0d c8 e0 e0 e0 e0 ff ff ff ff ff ff ff ff 39
					00 00 40 00 00 0d c8 20 40 40 60 60 60 80 80 80
					80 a0 a0 39 00 00 40 00 00 0d c8 a0 a0 a0 c0 c0
					c0 c0 c0 c0 e0 e0 e0 39 00 00 40 00 00 0d c8 e0
					e0 e0 e0 ff ff ff ff ff ff ff ff 39 00 00 40 00
					00 0d c8 20 40 40 60 60 60 80 80 80 80 a0 a0 39
					00 00 40 00 00 0d c8 a0 a0 a0 c0 c0 c0 c0 c0 c0
					e0 e0 e0 39 00 00 40 00 00 0d c8 e0 e0 e0 e0 ff
					ff ff ff ff ff ff ff 15 00 00 00 00 00 02 c4 00
				];
				mi,mdss-dsi-timing-switch-pwm-command = [
					15 00 00 40 00 00 02 a4 01 39 00 00 40 00 00 03
					f0 aa 14 15 00 00 40 00 00 02 65 0c 39 00 00 40
					00 00 03 b5 18 0c 39 00 00 40 00 00 05 bc 10 10
					00 1e 15 00 00 40 00 00 02 65 0c 39 00 00 40 00
					00 03 b6 0f 0b 39 00 00 40 00 00 05 bd 10 10 00
					21 15 00 00 40 00 00 02 65 0c 39 00 00 40 00 00
					05 c6 03 07 1f 03 39 00 00 40 00 00 06 ca 10 10
					00 1e 13 39 00 00 40 00 00 03 f0 aa 1b 15 00 00
					40 00 00 02 65 09 39 00 00 40 00 00 04 de 1e 01
					03 15 00 00 00 00 00 02 a4 00 15 00 00 40 00 00
					02 6c 02 39 00 00 40 00 00 03 75 c0 02 39 00 00
					40 00 00 04 71 00 00 00 39 00 00 40 00 00 03 f0
					aa 16 15 00 00 40 00 00 02 d0 00 15 00 00 40 00
					00 02 65 07 15 00 00 40 00 00 02 d1 0b 15 00 00
					40 00 00 02 d2 01 15 00 00 40 00 00 02 65 02 39
					00 00 40 00 00 04 d2 03 65 0f 15 00 00 40 00 00
					02 76 01 15 00 00 40 00 00 02 77 1d 39 00 00 40
					00 00 03 f0 aa 10 15 00 00 40 00 00 02 cf 09 15
					00 00 00 00 00 02 a6 01
				];
				qcom,mdss-dsi-timing-switch-command = [
					15 00 00 40 00 00 02 a4 01 39 00 00 40 00 00 03
					f0 aa 14 15 00 00 40 00 00 02 65 0c 39 00 00 40
					00 00 03 b5 17 0b 39 00 00 40 00 00 05 bc 10 10
					00 1d 15 00 00 40 00 00 02 65 0c 39 00 00 40 00
					00 03 b6 10 0c 39 00 00 40 00 00 05 bd 10 10 00
					22 15 00 00 40 00 00 02 65 0c 39 00 00 40 00 00
					05 c6 02 06 1e 02 39 00 00 40 00 00 06 ca 10 10
					00 1f 22 39 00 00 40 00 00 03 f0 aa 1b 15 00 00
					40 00 00 02 65 09 39 00 00 40 00 00 04 de 1f 02
					02 15 00 00 00 00 00 02 a4 00 15 00 00 40 00 00
					02 6c 00 39 00 00 40 00 00 03 75 c0 02 39 00 00
					40 00 00 04 71 00 00 00 39 00 00 40 00 00 03 f0
					aa 16 15 00 00 40 00 00 02 d0 00 15 00 00 40 00
					00 02 65 01 15 00 00 40 00 00 02 d1 01 15 00 00
					40 00 00 02 d2 01 15 00 00 40 00 00 02 65 02 39
					00 00 40 00 00 04 d2 0a 53 0f 15 00 00 40 00 00
					02 76 01 15 00 00 40 00 00 02 77 09 39 00 00 40
					00 00 03 f0 aa 10 15 00 00 40 00 00 02 cf 09 39
					00 00 40 00 00 03 f0 aa 17 15 00 00 40 00 00 02
					c2 80 15 00 00 00 00 00 02 a6 01
				];
				qcom,mdss-dsi-h-sync-skew = <0>;
				qcom,mdss-dsi-panel-framerate = <24>;
				cell-index = <4>;
			};

			timing@wqhd_idle_120_to_10hz_index_05 {
				#include "dsi-panel-p1-42-0d-0b-p12-dsc-cmd-common.dtsi"
				qcom,mdss-dsi-on-command = [
					15 00 00 40 00 00 02 03 01 15 00 00 40 00 00 02
					35 00 15 00 00 40 00 00 02 53 20 39 00 00 40 00
					00 03 51 00 00 15 00 00 40 00 00 02 6f 02 15 00
					00 40 00 00 02 59 09 15 00 00 40 00 00 02 6c 00
					15 00 00 40 00 00 02 6d 00 39 00 00 40 00 00 81
					70 12 00 00 ab 30 80 0a 30 04 b0 00 10 02 58 02
					58 02 00 02 2c 00 20 01 98 00 08 00 0c 06 67 05
					b9 18 00 10 f0 07 10 20 00 06 0f 0f 33 0e 1c 2a
					38 46 54 62 69 70 77 79 7b 7d 7e 02 02 22 00 2a
					40 2a be 3a fc 3a fa 3a f8 3b 38 3b 78 3b b6 4b
					b6 4b f4 4b f4 6c 34 84 74 74 00 00 00 00 00 00
					00 00 00 00 00 00 00 00 00 00 00 00 00 00 00 00
					00 00 00 00 00 00 00 00 00 00 00 00 00 00 00 00
					00 39 00 00 40 00 00 03 ff 5a 81 15 00 00 40 00
					00 02 65 03 15 00 00 40 00 00 02 f3 04 15 00 00
					40 00 00 02 65 05 15 00 00 40 00 00 02 f3 48 39
					00 00 40 00 00 03 f0 aa 10 15 00 00 40 00 00 02
					65 0a 15 00 00 40 00 00 02 eb 10 39 00 00 40 00
					00 03 ff 5a 80 15 00 00 40 00 00 02 65 0e 15 00
					00 40 00 00 02 f9 a1 39 00 00 40 00 00 03 ff 5a
					81 15 00 00 40 00 00 02 65 02 39 00 00 40 00 00
					03 fb 63 73 39 00 00 40 00 00 03 f0 aa 10 15 00
					00 40 00 00 02 65 0b 39 00 00 40 00 00 05 d0 e4
					0f 20 40 15 00 00 40 00 00 02 65 15 39 00 00 40
					00 00 13 d1 be 40 40 40 40 0c 00 00 46 1f 1f 00
					00 40 0c 46 1f 1f 39 00 00 40 00 00 14 d9 39 68
					00 00 00 0b 0a 0d 0c 02 00 00 02 07 06 00 06 02
					0d 15 00 00 40 00 00 02 72 01 39 00 00 40 00 00
					03 ff 5a 83 15 00 00 40 00 00 02 65 0b 15 00 00
					40 00 00 02 f8 05 39 00 00 40 00 00 03 f0 aa 11
					15 00 00 40 00 00 02 c3 31 39 00 00 40 00 00 03
					f0 aa 18 15 00 00 40 00 00 02 b0 80 39 00 00 40
					00 00 03 f0 aa 19 15 00 00 40 00 00 02 c0 e0 39
					00 00 40 00 00 03 f0 aa 1a 15 00 00 40 00 00 02
					b0 01 39 00 00 40 00 00 03 f0 aa 10 39 00 00 40
					00 00 04 eb 00 00 30 39 00 00 40 00 00 08 ea 0f
					41 00 88 48 cb 01 15 00 00 40 00 00 02 65 0d 39
					00 00 40 00 00 04 ea 0c 00 01 15 00 00 40 00 00
					02 65 10 39 00 00 40 00 00 04 ea 0c 80 01 15 00
					00 40 00 00 02 65 13 39 00 00 40 00 00 04 ea c8
					ae 01 15 00 00 40 00 00 02 65 16 39 00 00 40 00
					00 04 ea 64 c1 01 15 00 00 40 00 00 02 65 19 39
					00 00 40 00 00 04 ea 98 a5 01 15 00 00 40 00 00
					02 65 28 39 00 00 40 00 00 04 ea 0c 00 00 39 00
					00 40 00 00 03 f0 aa 00 39 00 00 00 00 00 03 ff
					5a 00 05 00 00 00 78 00 01 11 39 00 00 40 00 00
					03 f0 aa 10 15 00 00 40 00 00 02 65 02 39 00 00
					40 00 00 03 cf 24 13 15 00 00 40 00 00 02 65 0b
					39 00 00 40 00 00 03 cf dd 79 39 00 00 40 00 00
					03 f0 aa 16 39 00 00 40 00 00 16 e3 00 01 00 00
					00 00 00 00 00 00 00 00 00 00 00 00 00 00 00 00
					00 39 00 00 40 00 00 16 e4 00 03 00 00 00 00 00
					00 00 00 00 00 00 00 00 00 00 00 00 00 00 39 00
					00 40 00 00 16 e5 00 04 00 00 00 00 00 00 00 00
					00 00 00 00 00 00 00 00 00 00 00 39 00 00 40 00
					00 16 e6 01 03 0b 00 00 00 00 00 00 00 00 00 00
					00 00 00 00 00 00 00 00 39 00 00 40 00 00 16 e7
					03 03 0b 0b 77 00 00 00 00 0e e0 00 00 00 00 00
					00 00 00 00 00 39 00 00 40 00 00 16 e8 02 0b 0b
					77 00 00 00 00 00 ee 00 00 00 00 00 00 00 00 00
					00 00 39 00 00 40 00 00 16 e9 02 08 08 59 00 00
					00 00 00 ee 00 00 00 00 00 00 00 00 00 00 00 39
					00 00 40 00 00 16 ea 00 0b 00 00 00 00 00 00 00
					00 00 00 00 00 00 00 00 00 00 00 00 39 00 00 40
					00 00 16 eb 02 01 03 ef 00 00 00 00 00 00 00 00
					00 00 00 00 00 00 00 00 00 39 00 00 40 00 00 16
					ec 00 01 00 00 00 00 00 00 00 40 00 00 00 00 00
					00 00 00 00 00 00 39 00 00 40 00 00 1f e0 f0 f1
					f2 f3 f4 f5 f6 00 00 00 f0 f1 f2 f3 f4 f5 f6 00
					00 00 f0 f1 f2 f3 f4 f5 f6 00 00 00 39 00 00 40
					00 00 15 ed f0 f1 f2 f3 f4 f5 f6 f7 f8 00 f0 f1
					f2 f3 f4 f5 f6 f7 f8 00 39 00 00 40 00 00 15 ee
					f0 f1 f2 f3 f4 f5 f6 f7 f8 00 f0 f1 f2 f3 f4 f5
					f6 f7 f8 00 39 00 00 40 00 00 03 f0 aa 12 15 00
					00 00 00 00 02 c7 fe 39 00 00 40 00 00 03 f0 aa
					14 15 00 00 40 00 00 02 65 0c 39 00 00 40 00 00
					03 b5 17 0b 39 00 00 40 00 00 05 bc 10 10 00 1d
					15 00 00 40 00 00 02 65 0c 39 00 00 40 00 00 03
					b6 10 0c 39 00 00 40 00 00 05 bd 10 10 00 22 15
					00 00 40 00 00 02 65 0c 39 00 00 40 00 00 05 c6
					02 06 1e 02 39 00 00 40 00 00 06 ca 10 10 00 1f
					22 39 00 00 40 00 00 03 f0 aa 1b 15 00 00 40 00
					00 02 65 09 39 00 00 00 00 00 04 de 1f 02 02 15
					00 00 40 00 00 02 6c 00 39 00 00 40 00 00 03 75
					c0 03 39 00 00 40 00 00 04 71 00 00 00 39 00 00
					40 00 00 03 f0 aa 16 15 00 00 40 00 00 02 d0 03
					15 00 00 40 00 00 02 65 01 15 00 00 40 00 00 02
					d1 01 15 00 00 40 00 00 02 d2 01 15 00 00 40 00
					00 02 65 02 39 00 00 40 00 00 04 d2 0a 53 0f 15
					00 00 40 00 00 02 76 01 15 00 00 40 00 00 02 77
					01 39 00 00 40 00 00 03 f0 aa 10 15 00 00 40 00
					00 02 cf 09 39 00 00 40 00 00 03 f0 aa 17 15 00
					00 40 00 00 02 c2 80 05 00 00 00 00 00 01 29 39
					00 00 40 00 00 03 f0 aa 17 39 00 00 40 00 00 02
					b0 b0 39 00 00 40 00 00 05 b1 08 06 06 00 39 00
					00 40 00 00 37 b2 00 40 00 00 40 00 00 20 20 00
					40 00 00 40 00 00 20 20 00 00 00 00 e0 00 00 00
					20 00 00 20 00 00 20 00 00 20 00 00 00 00 00 00
					00 00 18 00 00 18 00 00 44 00 00 00 39 00 00 40
					00 00 25 b3 88 b8 00 88 b8 80 80 c0 80 00 40 00
					00 40 00 00 40 00 08 38 00 08 38 00 00 40 00 00
					40 00 00 40 00 00 40 00 39 00 00 40 00 00 1a b4
					00 03 06 0c 18 03 06 0c 18 03 06 0c 18 03 06 0c
					18 03 06 0c 18 03 06 0c 18 39 00 00 40 00 00 0a
					b5 00 00 00 00 00 00 00 00 00 39 00 00 40 00 00
					31 b6 1f 1f 1f 1f 1f 1f 1f 1f 1f 1f 1f 1f 1f 1f
					1f 1f 1f 1f 1f 1f 1f 1f 1f 1f 1f 1f 1f 1f 1f 1f
					1f 1f 1f 1f 1f 1f 1f 1f 1f 1f 1f 1f 1f 1f 1f 1f
					1f 1f 39 00 00 00 00 00 1e b7 00 12 34 12 34 52
					34 56 34 56 74 56 78 33 94 26 64 19 98 0c cc 33
					94 26 64 19 98 0c cc 39 00 00 40 00 00 03 f0 aa
					10 15 00 00 40 00 00 02 65 0b 39 00 00 40 00 00
					03 cf dd 79 39 00 00 00 00 00 03 f0 aa 00 39 00
					00 40 00 00 03 f0 aa 19 39 00 00 40 00 00 03 c7
					00 00 15 00 00 40 00 00 02 c4 80 39 00 00 40 00
					00 0d c8 ec 00 00 00 00 00 03 60 00 00 00 00 39
					00 00 40 00 00 0d c8 03 f0 00 00 00 00 00 30 40
					00 00 00 39 00 00 40 00 00 0d c8 03 f0 00 fc 00
					00 00 10 00 00 00 00 39 00 00 40 00 00 0d c8 00
					20 00 03 f0 00 50 a0 c2 08 20 41 39 00 00 40 00
					00 0d c8 d4 00 00 00 00 00 2c 00 00 00 00 00 39
					00 00 40 00 00 0d c8 20 40 00 00 00 00 03 df fe
					00 00 00 39 00 00 40 00 00 0d c8 10 1f c1 f8 00
					00 10 10 3e 04 10 00 39 00 00 40 00 00 0d c8 04
					00 00 fb ff c0 60 82 06 14 30 c1 39 00 00 40 00
					00 0d c8 00 00 00 00 00 00 03 f0 00 00 00 00 39
					00 00 40 00 00 0d c8 f7 cf 80 00 00 00 07 ef ff
					00 00 00 39 00 00 40 00 00 0d c8 03 f0 00 fc 00
					00 03 f0 00 03 f0 00 39 00 00 40 00 00 0d c8 00
					2f bf 00 00 00 50 81 83 08 20 41 15 00 00 00 00
					00 02 c4 00 39 00 00 40 00 00 03 f0 aa 19 39 00
					00 40 00 00 03 c7 00 15 15 00 00 40 00 00 02 c4
					80 39 00 00 40 00 00 0d c8 f0 00 00 00 00 00 f8
					20 00 00 00 00 39 00 00 40 00 00 0d c8 ff ff c0
					00 00 00 f3 ef ff 00 00 00 39 00 00 40 00 00 0d
					c8 f3 ff ff fc 00 00 fb ff c0 ff f0 00 39 00 00
					40 00 00 0d c8 f7 df bf 00 0f c0 5c a1 c4 0c 20
					81 39 00 00 40 00 00 0d c8 f4 00 00 00 00 00 ff
					f0 00 00 00 00 39 00 00 40 00 00 0d c8 ff ff c0
					00 00 00 f7 ff c0 00 00 00 39 00 00 40 00 00 0d
					c8 fb ef ff 00 00 00 fb ff ff fc 00 00 39 00 00
					40 00 00 0d c8 ff ff ff ff f0 00 3c 81 84 0c 20
					41 39 00 00 40 00 00 0d c8 f4 00 00 00 00 00 f4
					00 00 00 00 00 39 00 00 40 00 00 0d c8 f8 0f c0
					00 00 00 f7 ff c0 00 00 00 39 00 00 40 00 00 0d
					c8 f7 d0 00 00 00 00 f7 ef fe ff f0 00 39 00 00
					40 00 00 0d c8 f8 0f c1 03 ff c0 5c 81 02 08 20
					40 15 00 00 00 00 00 02 c4 00 39 00 00 40 00 00
					03 f0 aa 19 39 00 00 40 00 00 03 c7 00 2a 15 00
					00 40 00 00 02 c4 80 39 00 00 40 00 00 0d c8 f4
					00 00 00 00 00 f4 00 00 00 00 00 39 00 00 40 00
					00 0d c8 f7 ef c0 00 00 00 f7 ff c0 00 00 00 39
					00 00 40 00 00 0d c8 fb f0 3f 00 00 00 f3 ef bf
					ff f0 00 39 00 00 40 00 00 0d c8 ff ff ff fc 00
					00 54 81 84 0c 20 41 39 00 00 40 00 00 0d c8 f8
					00 00 00 00 00 f7 f0 00 00 00 00 39 00 00 40 00
					00 0d c8 f7 f0 00 00 00 00 f7 ff c0 00 00 00 39
					00 00 40 00 00 0d c8 fb ff fe fc 00 00 f7 ff c0
					00 00 00 39 00 00 40 00 00 0d c8 ff ff c0 00 00
					00 50 71 43 08 10 41 39 00 00 40 00 00 0d c8 f8
					00 00 00 00 00 f7 f0 00 00 00 00 39 00 00 40 00
					00 0d c8 f3 ff 00 00 00 00 f7 b0 c0 00 00 00 39
					00 00 40 00 00 0d c8 f8 3f ff f0 00 00 fb ff ff
					fc 00 00 39 00 00 40 00 00 0d c8 ff f0 00 13 f0
					00 50 71 03 08 20 41 15 00 00 00 00 00 02 c4 00
					39 00 00 40 00 00 03 f0 aa 19 39 00 00 40 00 00
					03 c7 00 3f 15 00 00 40 00 00 02 c4 80 39 00 00
					40 00 00 0d c8 20 40 40 60 60 60 80 80 80 80 a0
					a0 39 00 00 40 00 00 0d c8 a0 a0 a0 c0 c0 c0 c0
					c0 c0 e0 e0 e0 39 00 00 40 00 00 0d c8 e0 e0 e0
					e0 ff ff ff ff ff ff ff ff 39 00 00 40 00 00 0d
					c8 1b 1c 2f 1e 4c 5b 1f 56 5c 6e a0 a0 39 00 00
					40 00 00 0d c8 a0 a0 a0 c0 c0 c0 c0 c0 c0 e0 e0
					e0 39 00 00 40 00 00 0d c8 e0 e0 e0 e0 ff ff ff
					ff ff ff ff ff 39 00 00 40 00 00 0d c8 20 40 40
					60 60 60 80 80 80 80 a0 a0 39 00 00 40 00 00 0d
					c8 a0 a0 a0 c0 c0 c0 c0 c0 c0 e0 e0 e0 39 00 00
					40 00 00 0d c8 e0 e0 e0 e0 ff ff ff ff ff ff ff
					ff 15 00 00 00 00 00 02 c4 00 39 00 00 40 00 00
					03 f0 aa 19 39 00 00 40 00 00 03 c7 00 c6 15 00
					00 40 00 00 02 c4 80 39 00 00 40 00 00 0d c8 f8
					00 00 00 00 00 d8 00 00 00 00 00 39 00 00 40 00
					00 0d c8 03 f0 00 00 00 00 00 00 40 00 00 00 39
					00 00 40 00 00 0d c8 ec 00 00 fc 00 00 00 00 00
					00 00 00 39 00 00 40 00 00 0d c8 00 00 00 03 f0
					00 50 50 c2 08 20 41 39 00 00 40 00 00 0d c8 c8
					00 00 00 00 00 00 00 00 00 00 00 39 00 00 40 00
					00 0d c8 00 40 00 00 00 00 0b df fe 00 00 00 39
					00 00 40 00 00 0d c8 fc 1f c1 f8 00 00 fc 10 3e
					04 10 00 39 00 00 40 00 00 0d c8 00 00 00 fb ff
					c0 78 82 06 14 30 c1 39 00 00 40 00 00 0d c8 00
					00 00 00 00 00 03 f0 00 00 00 00 39 00 00 40 00
					00 0d c8 f7 cf 80 00 00 00 07 ef ff 00 00 00 39
					00 00 40 00 00 0d c8 03 f0 00 fc 00 00 03 f0 00
					03 f0 00 39 00 00 40 00 00 0d c8 00 2f bf 00 00
					00 50 81 83 08 20 41 15 00 00 00 00 00 02 c4 00
					39 00 00 40 00 00 03 f0 aa 19 39 00 00 40 00 00
					03 c7 00 db 15 00 00 40 00 00 02 c4 80 39 00 00
					40 00 00 0d c8 f0 00 00 00 00 00 f8 20 00 00 00
					00 39 00 00 40 00 00 0d c8 ff ff c0 00 00 00 f3
					ef ff 00 00 00 39 00 00 40 00 00 0d c8 f3 ff ff
					fc 00 00 fb ff c0 ff f0 00 39 00 00 40 00 00 0d
					c8 f7 df bf 00 0f c0 5c a1 c4 0c 20 81 39 00 00
					40 00 00 0d c8 f8 00 00 00 00 00 ff f0 00 00 00
					00 39 00 00 40 00 00 0d c8 ff ff c0 00 00 00 f7
					ff c0 00 00 00 39 00 00 40 00 00 0d c8 fb ef ff
					00 00 00 fb ff ff fc 00 00 39 00 00 40 00 00 0d
					c8 ff ff ff ff f0 00 3c 81 84 0c 20 41 39 00 00
					40 00 00 0d c8 f4 00 00 00 00 00 f4 00 00 00 00
					00 39 00 00 40 00 00 0d c8 f8 0f c0 00 00 00 f7
					ff c0 00 00 00 39 00 00 40 00 00 0d c8 f7 d0 00
					00 00 00 f7 ef fe ff f0 00 39 00 00 40 00 00 0d
					c8 f8 0f c1 03 ff c0 5c 81 02 08 20 40 15 00 00
					00 00 00 02 c4 00 39 00 00 40 00 00 03 f0 aa 19
					39 00 00 40 00 00 03 c7 01 05 15 00 00 40 00 00
					02 c4 80 39 00 00 40 00 00 0d c8 20 40 40 60 60
					60 80 80 80 80 a0 a0 39 00 00 40 00 00 0d c8 a0
					a0 a0 c0 c0 c0 c0 c0 c0 e0 e0 e0 39 00 00 40 00
					00 0d c8 e0 e0 e0 e0 ff ff ff ff ff ff ff ff 39
					00 00 40 00 00 0d c8 20 40 40 60 60 60 80 80 80
					80 a0 a0 39 00 00 40 00 00 0d c8 a0 a0 a0 c0 c0
					c0 c0 c0 c0 e0 e0 e0 39 00 00 40 00 00 0d c8 e0
					e0 e0 e0 ff ff ff ff ff ff ff ff 39 00 00 40 00
					00 0d c8 20 40 40 60 60 60 80 80 80 80 a0 a0 39
					00 00 40 00 00 0d c8 a0 a0 a0 c0 c0 c0 c0 c0 c0
					e0 e0 e0 39 00 00 40 00 00 0d c8 e0 e0 e0 e0 ff
					ff ff ff ff ff ff ff 15 00 00 00 00 00 02 c4 00
				];
				mi,mdss-dsi-timing-switch-pwm-command = [
					15 00 00 40 00 00 02 a4 01 39 00 00 40 00 00 03
					f0 aa 14 15 00 00 40 00 00 02 65 0c 39 00 00 40
					00 00 03 b5 18 0c 39 00 00 40 00 00 05 bc 10 10
					00 1e 15 00 00 40 00 00 02 65 0c 39 00 00 40 00
					00 03 b6 0f 0b 39 00 00 40 00 00 05 bd 10 10 00
					21 15 00 00 40 00 00 02 65 0c 39 00 00 40 00 00
					05 c6 03 07 1f 03 39 00 00 40 00 00 06 ca 10 10
					00 1e 13 39 00 00 40 00 00 03 f0 aa 1b 15 00 00
					40 00 00 02 65 09 39 00 00 40 00 00 04 de 1e 01
					03 15 00 00 00 00 00 02 a4 00 15 00 00 40 00 00
					02 6c 02 39 00 00 40 00 00 03 75 c0 07 39 00 00
					40 00 00 04 71 00 00 00 39 00 00 40 00 00 03 f0
					aa 16 15 00 00 40 00 00 02 d0 03 15 00 00 40 00
					00 02 65 07 15 00 00 40 00 00 02 d1 0b 15 00 00
					40 00 00 02 d2 01 15 00 00 40 00 00 02 65 02 39
					00 00 40 00 00 04 d2 03 65 0f 15 00 00 40 00 00
					02 76 01 15 00 00 40 00 00 02 77 05 39 00 00 40
					00 00 03 f0 aa 10 15 00 00 40 00 00 02 cf 09 15
					00 00 00 00 00 02 a6 01
				];
				qcom,mdss-dsi-timing-switch-command = [
					15 00 00 40 00 00 02 a4 01 39 00 00 40 00 00 03
					f0 aa 14 15 00 00 40 00 00 02 65 0c 39 00 00 40
					00 00 03 b5 17 0b 39 00 00 40 00 00 05 bc 10 10
					00 1d 15 00 00 40 00 00 02 65 0c 39 00 00 40 00
					00 03 b6 10 0c 39 00 00 40 00 00 05 bd 10 10 00
					22 15 00 00 40 00 00 02 65 0c 39 00 00 40 00 00
					05 c6 02 06 1e 02 39 00 00 40 00 00 06 ca 10 10
					00 1f 22 39 00 00 40 00 00 03 f0 aa 1b 15 00 00
					40 00 00 02 65 09 39 00 00 40 00 00 04 de 1f 02
					02 15 00 00 00 00 00 02 a4 00 15 00 00 40 00 00
					02 6c 00 39 00 00 40 00 00 03 75 c0 03 39 00 00
					40 00 00 04 71 00 00 00 39 00 00 40 00 00 03 f0
					aa 16 15 00 00 40 00 00 02 d0 03 15 00 00 40 00
					00 02 65 01 15 00 00 40 00 00 02 d1 01 15 00 00
					40 00 00 02 d2 01 15 00 00 40 00 00 02 65 02 39
					00 00 40 00 00 04 d2 0a 53 0f 15 00 00 40 00 00
					02 76 01 15 00 00 40 00 00 02 77 01 39 00 00 40
					00 00 03 f0 aa 10 15 00 00 40 00 00 02 cf 09 39
					00 00 40 00 00 03 f0 aa 17 15 00 00 40 00 00 02
					c2 80 15 00 00 00 00 00 02 a6 01
				];
				mi,mdss-dsi-ddic-min-framerate = <10>;
				mi,mdss-dsi-sf-framerate = <120>;
				mi,mdss-dsi-ddic-mode = "idle";
				qcom,mdss-dsi-h-sync-skew = <31754>;
				qcom,mdss-dsi-panel-framerate = <120>;
				cell-index = <5>;
			};

			timing@wqhd_idle_120_to_1hz_index_06 {
				#include "dsi-panel-p1-42-0d-0b-p12-dsc-cmd-common.dtsi"
				qcom,mdss-dsi-on-command = [
					15 00 00 40 00 00 02 03 01 15 00 00 40 00 00 02
					35 00 15 00 00 40 00 00 02 53 20 39 00 00 40 00
					00 03 51 00 00 15 00 00 40 00 00 02 6f 02 15 00
					00 40 00 00 02 59 09 15 00 00 40 00 00 02 6c 00
					15 00 00 40 00 00 02 6d 00 39 00 00 40 00 00 81
					70 12 00 00 ab 30 80 0a 30 04 b0 00 10 02 58 02
					58 02 00 02 2c 00 20 01 98 00 08 00 0c 06 67 05
					b9 18 00 10 f0 07 10 20 00 06 0f 0f 33 0e 1c 2a
					38 46 54 62 69 70 77 79 7b 7d 7e 02 02 22 00 2a
					40 2a be 3a fc 3a fa 3a f8 3b 38 3b 78 3b b6 4b
					b6 4b f4 4b f4 6c 34 84 74 74 00 00 00 00 00 00
					00 00 00 00 00 00 00 00 00 00 00 00 00 00 00 00
					00 00 00 00 00 00 00 00 00 00 00 00 00 00 00 00
					00 39 00 00 40 00 00 03 ff 5a 81 15 00 00 40 00
					00 02 65 03 15 00 00 40 00 00 02 f3 04 15 00 00
					40 00 00 02 65 05 15 00 00 40 00 00 02 f3 48 39
					00 00 40 00 00 03 f0 aa 10 15 00 00 40 00 00 02
					65 0a 15 00 00 40 00 00 02 eb 10 39 00 00 40 00
					00 03 ff 5a 80 15 00 00 40 00 00 02 65 0e 15 00
					00 40 00 00 02 f9 a1 39 00 00 40 00 00 03 ff 5a
					81 15 00 00 40 00 00 02 65 02 39 00 00 40 00 00
					03 fb 63 73 39 00 00 40 00 00 03 f0 aa 10 15 00
					00 40 00 00 02 65 0b 39 00 00 40 00 00 05 d0 e4
					0f 20 40 15 00 00 40 00 00 02 65 15 39 00 00 40
					00 00 13 d1 be 40 40 40 40 0c 00 00 46 1f 1f 00
					00 40 0c 46 1f 1f 39 00 00 40 00 00 14 d9 39 68
					00 00 00 0b 0a 0d 0c 02 00 00 02 07 06 00 06 02
					0d 15 00 00 40 00 00 02 72 01 39 00 00 40 00 00
					03 ff 5a 83 15 00 00 40 00 00 02 65 0b 15 00 00
					40 00 00 02 f8 05 39 00 00 40 00 00 03 f0 aa 11
					15 00 00 40 00 00 02 c3 31 39 00 00 40 00 00 03
					f0 aa 18 15 00 00 40 00 00 02 b0 80 39 00 00 40
					00 00 03 f0 aa 19 15 00 00 40 00 00 02 c0 e0 39
					00 00 40 00 00 03 f0 aa 1a 15 00 00 40 00 00 02
					b0 01 39 00 00 40 00 00 03 f0 aa 10 39 00 00 40
					00 00 04 eb 00 00 30 39 00 00 40 00 00 08 ea 0f
					41 00 88 48 cb 01 15 00 00 40 00 00 02 65 0d 39
					00 00 40 00 00 04 ea 0c 00 01 15 00 00 40 00 00
					02 65 10 39 00 00 40 00 00 04 ea 0c 80 01 15 00
					00 40 00 00 02 65 13 39 00 00 40 00 00 04 ea c8
					ae 01 15 00 00 40 00 00 02 65 16 39 00 00 40 00
					00 04 ea 64 c1 01 15 00 00 40 00 00 02 65 19 39
					00 00 40 00 00 04 ea 98 a5 01 15 00 00 40 00 00
					02 65 28 39 00 00 40 00 00 04 ea 0c 00 00 39 00
					00 40 00 00 03 f0 aa 00 39 00 00 00 00 00 03 ff
					5a 00 05 00 00 00 78 00 01 11 39 00 00 40 00 00
					03 f0 aa 10 15 00 00 40 00 00 02 65 02 39 00 00
					40 00 00 03 cf 24 13 15 00 00 40 00 00 02 65 0b
					39 00 00 40 00 00 03 cf dd 79 39 00 00 40 00 00
					03 f0 aa 16 39 00 00 40 00 00 16 e3 00 01 00 00
					00 00 00 00 00 00 00 00 00 00 00 00 00 00 00 00
					00 39 00 00 40 00 00 16 e4 00 03 00 00 00 00 00
					00 00 00 00 00 00 00 00 00 00 00 00 00 00 39 00
					00 40 00 00 16 e5 00 04 00 00 00 00 00 00 00 00
					00 00 00 00 00 00 00 00 00 00 00 39 00 00 40 00
					00 16 e6 01 03 0b 00 00 00 00 00 00 00 00 00 00
					00 00 00 00 00 00 00 00 39 00 00 40 00 00 16 e7
					03 03 0b 0b 77 00 00 00 00 0e e0 00 00 00 00 00
					00 00 00 00 00 39 00 00 40 00 00 16 e8 02 0b 0b
					77 00 00 00 00 00 ee 00 00 00 00 00 00 00 00 00
					00 00 39 00 00 40 00 00 16 e9 02 08 08 59 00 00
					00 00 00 ee 00 00 00 00 00 00 00 00 00 00 00 39
					00 00 40 00 00 16 ea 00 0b 00 00 00 00 00 00 00
					00 00 00 00 00 00 00 00 00 00 00 00 39 00 00 40
					00 00 16 eb 02 01 03 ef 00 00 00 00 00 00 00 00
					00 00 00 00 00 00 00 00 00 39 00 00 40 00 00 16
					ec 00 01 00 00 00 00 00 00 00 40 00 00 00 00 00
					00 00 00 00 00 00 39 00 00 40 00 00 1f e0 f0 f1
					f2 f3 f4 f5 f6 00 00 00 f0 f1 f2 f3 f4 f5 f6 00
					00 00 f0 f1 f2 f3 f4 f5 f6 00 00 00 39 00 00 40
					00 00 15 ed f0 f1 f2 f3 f4 f5 f6 f7 f8 00 f0 f1
					f2 f3 f4 f5 f6 f7 f8 00 39 00 00 40 00 00 15 ee
					f0 f1 f2 f3 f4 f5 f6 f7 f8 00 f0 f1 f2 f3 f4 f5
					f6 f7 f8 00 39 00 00 40 00 00 03 f0 aa 12 15 00
					00 00 00 00 02 c7 fe 39 00 00 40 00 00 03 f0 aa
					14 15 00 00 40 00 00 02 65 0c 39 00 00 40 00 00
					03 b5 17 0b 39 00 00 40 00 00 05 bc 10 10 00 1d
					15 00 00 40 00 00 02 65 0c 39 00 00 40 00 00 03
					b6 10 0c 39 00 00 40 00 00 05 bd 10 10 00 22 15
					00 00 40 00 00 02 65 0c 39 00 00 40 00 00 05 c6
					02 06 1e 02 39 00 00 40 00 00 06 ca 10 10 00 1f
					22 39 00 00 40 00 00 03 f0 aa 1b 15 00 00 40 00
					00 02 65 09 39 00 00 00 00 00 04 de 1f 02 02 15
					00 00 40 00 00 02 6c 00 39 00 00 40 00 00 03 75
					c0 04 39 00 00 40 00 00 04 71 00 00 00 39 00 00
					40 00 00 03 f0 aa 16 15 00 00 40 00 00 02 d0 03
					15 00 00 40 00 00 02 65 01 15 00 00 40 00 00 02
					d1 01 15 00 00 40 00 00 02 d2 01 15 00 00 40 00
					00 02 65 02 39 00 00 40 00 00 04 d2 0a 53 0f 15
					00 00 40 00 00 02 76 01 15 00 00 40 00 00 02 77
					01 39 00 00 40 00 00 03 f0 aa 10 15 00 00 40 00
					00 02 cf 09 39 00 00 40 00 00 03 f0 aa 17 15 00
					00 40 00 00 02 c2 80 05 00 00 00 00 00 01 29 39
					00 00 40 00 00 03 f0 aa 17 39 00 00 40 00 00 02
					b0 b0 39 00 00 40 00 00 05 b1 08 06 06 00 39 00
					00 40 00 00 37 b2 00 40 00 00 40 00 00 20 20 00
					40 00 00 40 00 00 20 20 00 00 00 00 e0 00 00 00
					20 00 00 20 00 00 20 00 00 20 00 00 00 00 00 00
					00 00 18 00 00 18 00 00 44 00 00 00 39 00 00 40
					00 00 25 b3 88 b8 00 88 b8 80 80 c0 80 00 40 00
					00 40 00 00 40 00 08 38 00 08 38 00 00 40 00 00
					40 00 00 40 00 00 40 00 39 00 00 40 00 00 1a b4
					00 03 06 0c 18 03 06 0c 18 03 06 0c 18 03 06 0c
					18 03 06 0c 18 03 06 0c 18 39 00 00 40 00 00 0a
					b5 00 00 00 00 00 00 00 00 00 39 00 00 40 00 00
					31 b6 1f 1f 1f 1f 1f 1f 1f 1f 1f 1f 1f 1f 1f 1f
					1f 1f 1f 1f 1f 1f 1f 1f 1f 1f 1f 1f 1f 1f 1f 1f
					1f 1f 1f 1f 1f 1f 1f 1f 1f 1f 1f 1f 1f 1f 1f 1f
					1f 1f 39 00 00 00 00 00 1e b7 00 12 34 12 34 52
					34 56 34 56 74 56 78 33 94 26 64 19 98 0c cc 33
					94 26 64 19 98 0c cc 39 00 00 40 00 00 03 f0 aa
					10 15 00 00 40 00 00 02 65 0b 39 00 00 40 00 00
					03 cf dd 79 39 00 00 00 00 00 03 f0 aa 00 39 00
					00 40 00 00 03 f0 aa 19 39 00 00 40 00 00 03 c7
					00 00 15 00 00 40 00 00 02 c4 80 39 00 00 40 00
					00 0d c8 ec 00 00 00 00 00 03 60 00 00 00 00 39
					00 00 40 00 00 0d c8 03 f0 00 00 00 00 00 30 40
					00 00 00 39 00 00 40 00 00 0d c8 03 f0 00 fc 00
					00 00 10 00 00 00 00 39 00 00 40 00 00 0d c8 00
					20 00 03 f0 00 50 a0 c2 08 20 41 39 00 00 40 00
					00 0d c8 d4 00 00 00 00 00 2c 00 00 00 00 00 39
					00 00 40 00 00 0d c8 20 40 00 00 00 00 03 df fe
					00 00 00 39 00 00 40 00 00 0d c8 10 1f c1 f8 00
					00 10 10 3e 04 10 00 39 00 00 40 00 00 0d c8 04
					00 00 fb ff c0 60 82 06 14 30 c1 39 00 00 40 00
					00 0d c8 00 00 00 00 00 00 03 f0 00 00 00 00 39
					00 00 40 00 00 0d c8 f7 cf 80 00 00 00 07 ef ff
					00 00 00 39 00 00 40 00 00 0d c8 03 f0 00 fc 00
					00 03 f0 00 03 f0 00 39 00 00 40 00 00 0d c8 00
					2f bf 00 00 00 50 81 83 08 20 41 15 00 00 00 00
					00 02 c4 00 39 00 00 40 00 00 03 f0 aa 19 39 00
					00 40 00 00 03 c7 00 15 15 00 00 40 00 00 02 c4
					80 39 00 00 40 00 00 0d c8 f0 00 00 00 00 00 f8
					20 00 00 00 00 39 00 00 40 00 00 0d c8 ff ff c0
					00 00 00 f3 ef ff 00 00 00 39 00 00 40 00 00 0d
					c8 f3 ff ff fc 00 00 fb ff c0 ff f0 00 39 00 00
					40 00 00 0d c8 f7 df bf 00 0f c0 5c a1 c4 0c 20
					81 39 00 00 40 00 00 0d c8 f4 00 00 00 00 00 ff
					f0 00 00 00 00 39 00 00 40 00 00 0d c8 ff ff c0
					00 00 00 f7 ff c0 00 00 00 39 00 00 40 00 00 0d
					c8 fb ef ff 00 00 00 fb ff ff fc 00 00 39 00 00
					40 00 00 0d c8 ff ff ff ff f0 00 3c 81 84 0c 20
					41 39 00 00 40 00 00 0d c8 f4 00 00 00 00 00 f4
					00 00 00 00 00 39 00 00 40 00 00 0d c8 f8 0f c0
					00 00 00 f7 ff c0 00 00 00 39 00 00 40 00 00 0d
					c8 f7 d0 00 00 00 00 f7 ef fe ff f0 00 39 00 00
					40 00 00 0d c8 f8 0f c1 03 ff c0 5c 81 02 08 20
					40 15 00 00 00 00 00 02 c4 00 39 00 00 40 00 00
					03 f0 aa 19 39 00 00 40 00 00 03 c7 00 2a 15 00
					00 40 00 00 02 c4 80 39 00 00 40 00 00 0d c8 f4
					00 00 00 00 00 f4 00 00 00 00 00 39 00 00 40 00
					00 0d c8 f7 ef c0 00 00 00 f7 ff c0 00 00 00 39
					00 00 40 00 00 0d c8 fb f0 3f 00 00 00 f3 ef bf
					ff f0 00 39 00 00 40 00 00 0d c8 ff ff ff fc 00
					00 54 81 84 0c 20 41 39 00 00 40 00 00 0d c8 f8
					00 00 00 00 00 f7 f0 00 00 00 00 39 00 00 40 00
					00 0d c8 f7 f0 00 00 00 00 f7 ff c0 00 00 00 39
					00 00 40 00 00 0d c8 fb ff fe fc 00 00 f7 ff c0
					00 00 00 39 00 00 40 00 00 0d c8 ff ff c0 00 00
					00 50 71 43 08 10 41 39 00 00 40 00 00 0d c8 f8
					00 00 00 00 00 f7 f0 00 00 00 00 39 00 00 40 00
					00 0d c8 f3 ff 00 00 00 00 f7 b0 c0 00 00 00 39
					00 00 40 00 00 0d c8 f8 3f ff f0 00 00 fb ff ff
					fc 00 00 39 00 00 40 00 00 0d c8 ff f0 00 13 f0
					00 50 71 03 08 20 41 15 00 00 00 00 00 02 c4 00
					39 00 00 40 00 00 03 f0 aa 19 39 00 00 40 00 00
					03 c7 00 3f 15 00 00 40 00 00 02 c4 80 39 00 00
					40 00 00 0d c8 20 40 40 60 60 60 80 80 80 80 a0
					a0 39 00 00 40 00 00 0d c8 a0 a0 a0 c0 c0 c0 c0
					c0 c0 e0 e0 e0 39 00 00 40 00 00 0d c8 e0 e0 e0
					e0 ff ff ff ff ff ff ff ff 39 00 00 40 00 00 0d
					c8 1b 1c 2f 1e 4c 5b 1f 56 5c 6e a0 a0 39 00 00
					40 00 00 0d c8 a0 a0 a0 c0 c0 c0 c0 c0 c0 e0 e0
					e0 39 00 00 40 00 00 0d c8 e0 e0 e0 e0 ff ff ff
					ff ff ff ff ff 39 00 00 40 00 00 0d c8 20 40 40
					60 60 60 80 80 80 80 a0 a0 39 00 00 40 00 00 0d
					c8 a0 a0 a0 c0 c0 c0 c0 c0 c0 e0 e0 e0 39 00 00
					40 00 00 0d c8 e0 e0 e0 e0 ff ff ff ff ff ff ff
					ff 15 00 00 00 00 00 02 c4 00 39 00 00 40 00 00
					03 f0 aa 19 39 00 00 40 00 00 03 c7 00 c6 15 00
					00 40 00 00 02 c4 80 39 00 00 40 00 00 0d c8 f8
					00 00 00 00 00 d8 00 00 00 00 00 39 00 00 40 00
					00 0d c8 03 f0 00 00 00 00 00 00 40 00 00 00 39
					00 00 40 00 00 0d c8 ec 00 00 fc 00 00 00 00 00
					00 00 00 39 00 00 40 00 00 0d c8 00 00 00 03 f0
					00 50 50 c2 08 20 41 39 00 00 40 00 00 0d c8 c8
					00 00 00 00 00 00 00 00 00 00 00 39 00 00 40 00
					00 0d c8 00 40 00 00 00 00 0b df fe 00 00 00 39
					00 00 40 00 00 0d c8 fc 1f c1 f8 00 00 fc 10 3e
					04 10 00 39 00 00 40 00 00 0d c8 00 00 00 fb ff
					c0 78 82 06 14 30 c1 39 00 00 40 00 00 0d c8 00
					00 00 00 00 00 03 f0 00 00 00 00 39 00 00 40 00
					00 0d c8 f7 cf 80 00 00 00 07 ef ff 00 00 00 39
					00 00 40 00 00 0d c8 03 f0 00 fc 00 00 03 f0 00
					03 f0 00 39 00 00 40 00 00 0d c8 00 2f bf 00 00
					00 50 81 83 08 20 41 15 00 00 00 00 00 02 c4 00
					39 00 00 40 00 00 03 f0 aa 19 39 00 00 40 00 00
					03 c7 00 db 15 00 00 40 00 00 02 c4 80 39 00 00
					40 00 00 0d c8 f0 00 00 00 00 00 f8 20 00 00 00
					00 39 00 00 40 00 00 0d c8 ff ff c0 00 00 00 f3
					ef ff 00 00 00 39 00 00 40 00 00 0d c8 f3 ff ff
					fc 00 00 fb ff c0 ff f0 00 39 00 00 40 00 00 0d
					c8 f7 df bf 00 0f c0 5c a1 c4 0c 20 81 39 00 00
					40 00 00 0d c8 f8 00 00 00 00 00 ff f0 00 00 00
					00 39 00 00 40 00 00 0d c8 ff ff c0 00 00 00 f7
					ff c0 00 00 00 39 00 00 40 00 00 0d c8 fb ef ff
					00 00 00 fb ff ff fc 00 00 39 00 00 40 00 00 0d
					c8 ff ff ff ff f0 00 3c 81 84 0c 20 41 39 00 00
					40 00 00 0d c8 f4 00 00 00 00 00 f4 00 00 00 00
					00 39 00 00 40 00 00 0d c8 f8 0f c0 00 00 00 f7
					ff c0 00 00 00 39 00 00 40 00 00 0d c8 f7 d0 00
					00 00 00 f7 ef fe ff f0 00 39 00 00 40 00 00 0d
					c8 f8 0f c1 03 ff c0 5c 81 02 08 20 40 15 00 00
					00 00 00 02 c4 00 39 00 00 40 00 00 03 f0 aa 19
					39 00 00 40 00 00 03 c7 01 05 15 00 00 40 00 00
					02 c4 80 39 00 00 40 00 00 0d c8 20 40 40 60 60
					60 80 80 80 80 a0 a0 39 00 00 40 00 00 0d c8 a0
					a0 a0 c0 c0 c0 c0 c0 c0 e0 e0 e0 39 00 00 40 00
					00 0d c8 e0 e0 e0 e0 ff ff ff ff ff ff ff ff 39
					00 00 40 00 00 0d c8 20 40 40 60 60 60 80 80 80
					80 a0 a0 39 00 00 40 00 00 0d c8 a0 a0 a0 c0 c0
					c0 c0 c0 c0 e0 e0 e0 39 00 00 40 00 00 0d c8 e0
					e0 e0 e0 ff ff ff ff ff ff ff ff 39 00 00 40 00
					00 0d c8 20 40 40 60 60 60 80 80 80 80 a0 a0 39
					00 00 40 00 00 0d c8 a0 a0 a0 c0 c0 c0 c0 c0 c0
					e0 e0 e0 39 00 00 40 00 00 0d c8 e0 e0 e0 e0 ff
					ff ff ff ff ff ff ff 15 00 00 00 00 00 02 c4 00
				];
				mi,mdss-dsi-timing-switch-pwm-command = [
					15 00 00 40 00 00 02 a4 01 39 00 00 40 00 00 03
					f0 aa 14 15 00 00 40 00 00 02 65 0c 39 00 00 40
					00 00 03 b5 18 0c 39 00 00 40 00 00 05 bc 10 10
					00 1e 15 00 00 40 00 00 02 65 0c 39 00 00 40 00
					00 03 b6 0f 0b 39 00 00 40 00 00 05 bd 10 10 00
					21 15 00 00 40 00 00 02 65 0c 39 00 00 40 00 00
					05 c6 03 07 1f 03 39 00 00 40 00 00 06 ca 10 10
					00 1e 13 39 00 00 40 00 00 03 f0 aa 1b 15 00 00
					40 00 00 02 65 09 39 00 00 40 00 00 04 de 1e 01
					03 15 00 00 00 00 00 02 a4 00 15 00 00 40 00 00
					02 6c 02 39 00 00 40 00 00 03 75 c0 05 39 00 00
					40 00 00 04 71 00 00 00 39 00 00 40 00 00 03 f0
					aa 16 15 00 00 40 00 00 02 d0 03 15 00 00 40 00
					00 02 65 07 15 00 00 40 00 00 02 d1 0b 15 00 00
					40 00 00 02 d2 01 15 00 00 40 00 00 02 65 02 39
					00 00 40 00 00 04 d2 03 65 0f 15 00 00 40 00 00
					02 76 01 15 00 00 40 00 00 02 77 05 39 00 00 40
					00 00 03 f0 aa 10 15 00 00 40 00 00 02 cf 09 15
					00 00 00 00 00 02 a6 01
				];
				qcom,mdss-dsi-timing-switch-command = [
					15 00 00 40 00 00 02 a4 01 39 00 00 40 00 00 03
					f0 aa 14 15 00 00 40 00 00 02 65 0c 39 00 00 40
					00 00 03 b5 17 0b 39 00 00 40 00 00 05 bc 10 10
					00 1d 15 00 00 40 00 00 02 65 0c 39 00 00 40 00
					00 03 b6 10 0c 39 00 00 40 00 00 05 bd 10 10 00
					22 15 00 00 40 00 00 02 65 0c 39 00 00 40 00 00
					05 c6 02 06 1e 02 39 00 00 40 00 00 06 ca 10 10
					00 1f 22 39 00 00 40 00 00 03 f0 aa 1b 15 00 00
					40 00 00 02 65 09 39 00 00 40 00 00 04 de 1f 02
					02 15 00 00 00 00 00 02 a4 00 15 00 00 40 00 00
					02 6c 00 39 00 00 40 00 00 03 75 c0 04 39 00 00
					40 00 00 04 71 00 00 00 39 00 00 40 00 00 03 f0
					aa 16 15 00 00 40 00 00 02 d0 03 15 00 00 40 00
					00 02 65 01 15 00 00 40 00 00 02 d1 01 15 00 00
					40 00 00 02 d2 01 15 00 00 40 00 00 02 65 02 39
					00 00 40 00 00 04 d2 0a 53 0f 15 00 00 40 00 00
					02 76 01 15 00 00 40 00 00 02 77 01 39 00 00 40
					00 00 03 f0 aa 10 15 00 00 40 00 00 02 cf 09 39
					00 00 40 00 00 03 f0 aa 17 15 00 00 40 00 00 02
					c2 80 15 00 00 00 00 00 02 a6 01
				];
				mi,mdss-dsi-ddic-min-framerate = <1>;
				mi,mdss-dsi-sf-framerate = <120>;
				mi,mdss-dsi-ddic-mode = "idle";
				qcom,mdss-dsi-h-sync-skew = <31745>;
				qcom,mdss-dsi-panel-framerate = <120>;
				cell-index = <6>;
			};

			timing@wqhd_auto_60_to_1hz_index_7 {
				#include "dsi-panel-p1-42-0d-0b-p12-dsc-cmd-common.dtsi"
				qcom,mdss-dsi-on-command = [
					15 00 00 40 00 00 02 03 01 15 00 00 40 00 00 02
					35 00 15 00 00 40 00 00 02 53 20 39 00 00 40 00
					00 03 51 00 00 15 00 00 40 00 00 02 6f 02 15 00
					00 40 00 00 02 59 09 15 00 00 40 00 00 02 6c 00
					15 00 00 40 00 00 02 6d 00 39 00 00 40 00 00 81
					70 12 00 00 ab 30 80 0a 30 04 b0 00 10 02 58 02
					58 02 00 02 2c 00 20 01 98 00 08 00 0c 06 67 05
					b9 18 00 10 f0 07 10 20 00 06 0f 0f 33 0e 1c 2a
					38 46 54 62 69 70 77 79 7b 7d 7e 02 02 22 00 2a
					40 2a be 3a fc 3a fa 3a f8 3b 38 3b 78 3b b6 4b
					b6 4b f4 4b f4 6c 34 84 74 74 00 00 00 00 00 00
					00 00 00 00 00 00 00 00 00 00 00 00 00 00 00 00
					00 00 00 00 00 00 00 00 00 00 00 00 00 00 00 00
					00 39 00 00 40 00 00 03 ff 5a 81 15 00 00 40 00
					00 02 65 03 15 00 00 40 00 00 02 f3 04 15 00 00
					40 00 00 02 65 05 15 00 00 40 00 00 02 f3 48 39
					00 00 40 00 00 03 f0 aa 10 15 00 00 40 00 00 02
					65 0a 15 00 00 40 00 00 02 eb 10 39 00 00 40 00
					00 03 ff 5a 80 15 00 00 40 00 00 02 65 0e 15 00
					00 40 00 00 02 f9 a1 39 00 00 40 00 00 03 ff 5a
					81 15 00 00 40 00 00 02 65 02 39 00 00 40 00 00
					03 fb 63 73 39 00 00 40 00 00 03 f0 aa 10 15 00
					00 40 00 00 02 65 0b 39 00 00 40 00 00 05 d0 e4
					0f 20 40 15 00 00 40 00 00 02 65 15 39 00 00 40
					00 00 13 d1 be 40 40 40 40 0c 00 00 46 1f 1f 00
					00 40 0c 46 1f 1f 39 00 00 40 00 00 14 d9 39 68
					00 00 00 0b 0a 0d 0c 02 00 00 02 07 06 00 06 02
					0d 15 00 00 40 00 00 02 72 01 39 00 00 40 00 00
					03 ff 5a 83 15 00 00 40 00 00 02 65 0b 15 00 00
					40 00 00 02 f8 05 39 00 00 40 00 00 03 f0 aa 11
					15 00 00 40 00 00 02 c3 31 39 00 00 40 00 00 03
					f0 aa 18 15 00 00 40 00 00 02 b0 80 39 00 00 40
					00 00 03 f0 aa 19 15 00 00 40 00 00 02 c0 e0 39
					00 00 40 00 00 03 f0 aa 1a 15 00 00 40 00 00 02
					b0 01 39 00 00 40 00 00 03 f0 aa 10 39 00 00 40
					00 00 04 eb 00 00 30 39 00 00 40 00 00 08 ea 0f
					41 00 88 48 cb 01 15 00 00 40 00 00 02 65 0d 39
					00 00 40 00 00 04 ea 0c 00 01 15 00 00 40 00 00
					02 65 10 39 00 00 40 00 00 04 ea 0c 80 01 15 00
					00 40 00 00 02 65 13 39 00 00 40 00 00 04 ea c8
					ae 01 15 00 00 40 00 00 02 65 16 39 00 00 40 00
					00 04 ea 64 c1 01 15 00 00 40 00 00 02 65 19 39
					00 00 40 00 00 04 ea 98 a5 01 15 00 00 40 00 00
					02 65 28 39 00 00 40 00 00 04 ea 0c 00 00 39 00
					00 40 00 00 03 f0 aa 00 39 00 00 00 00 00 03 ff
					5a 00 05 00 00 00 78 00 01 11 39 00 00 40 00 00
					03 f0 aa 10 15 00 00 40 00 00 02 65 02 39 00 00
					40 00 00 03 cf 24 13 15 00 00 40 00 00 02 65 0b
					39 00 00 40 00 00 03 cf dd 79 39 00 00 40 00 00
					03 f0 aa 16 39 00 00 40 00 00 16 e3 00 01 00 00
					00 00 00 00 00 00 00 00 00 00 00 00 00 00 00 00
					00 39 00 00 40 00 00 16 e4 00 03 00 00 00 00 00
					00 00 00 00 00 00 00 00 00 00 00 00 00 00 39 00
					00 40 00 00 16 e5 00 04 00 00 00 00 00 00 00 00
					00 00 00 00 00 00 00 00 00 00 00 39 00 00 40 00
					00 16 e6 01 03 0b 00 00 00 00 00 00 00 00 00 00
					00 00 00 00 00 00 00 00 39 00 00 40 00 00 16 e7
					03 03 0b 0b 77 00 00 00 00 0e e0 00 00 00 00 00
					00 00 00 00 00 39 00 00 40 00 00 16 e8 02 0b 0b
					77 00 00 00 00 00 ee 00 00 00 00 00 00 00 00 00
					00 00 39 00 00 40 00 00 16 e9 02 08 08 59 00 00
					00 00 00 ee 00 00 00 00 00 00 00 00 00 00 00 39
					00 00 40 00 00 16 ea 00 0b 00 00 00 00 00 00 00
					00 00 00 00 00 00 00 00 00 00 00 00 39 00 00 40
					00 00 16 eb 02 01 03 ef 00 00 00 00 00 00 00 00
					00 00 00 00 00 00 00 00 00 39 00 00 40 00 00 16
					ec 00 01 00 00 00 00 00 00 00 40 00 00 00 00 00
					00 00 00 00 00 00 39 00 00 40 00 00 1f e0 f0 f1
					f2 f3 f4 f5 f6 00 00 00 f0 f1 f2 f3 f4 f5 f6 00
					00 00 f0 f1 f2 f3 f4 f5 f6 00 00 00 39 00 00 40
					00 00 15 ed f0 f1 f2 f3 f4 f5 f6 f7 f8 00 f0 f1
					f2 f3 f4 f5 f6 f7 f8 00 39 00 00 40 00 00 15 ee
					f0 f1 f2 f3 f4 f5 f6 f7 f8 00 f0 f1 f2 f3 f4 f5
					f6 f7 f8 00 39 00 00 40 00 00 03 f0 aa 12 15 00
					00 00 00 00 02 c7 fe 39 00 00 40 00 00 03 f0 aa
					14 15 00 00 40 00 00 02 65 0c 39 00 00 40 00 00
					03 b5 17 0b 39 00 00 40 00 00 05 bc 10 10 00 1d
					15 00 00 40 00 00 02 65 0c 39 00 00 40 00 00 03
					b6 10 0c 39 00 00 40 00 00 05 bd 10 10 00 22 15
					00 00 40 00 00 02 65 0c 39 00 00 40 00 00 05 c6
					02 06 1e 02 39 00 00 40 00 00 06 ca 10 10 00 1f
					22 39 00 00 40 00 00 03 f0 aa 1b 15 00 00 40 00
					00 02 65 09 39 00 00 00 00 00 04 de 1f 02 02 15
					00 00 40 00 00 02 6c 00 39 00 00 40 00 00 03 75
					c0 05 39 00 00 40 00 00 04 71 00 00 00 39 00 00
					40 00 00 03 f0 aa 16 15 00 00 40 00 00 02 d0 01
					15 00 00 40 00 00 02 65 01 15 00 00 40 00 00 02
					d1 03 15 00 00 40 00 00 02 d2 01 15 00 00 40 00
					00 02 65 02 39 00 00 40 00 00 04 d2 0a 53 0f 15
					00 00 40 00 00 02 76 01 15 00 00 40 00 00 02 77
					03 39 00 00 40 00 00 03 f0 aa 10 15 00 00 40 00
					00 02 cf 09 39 00 00 40 00 00 03 f0 aa 17 15 00
					00 40 00 00 02 c2 80 05 00 00 00 00 00 01 29 39
					00 00 40 00 00 03 f0 aa 17 39 00 00 40 00 00 02
					b0 b0 39 00 00 40 00 00 05 b1 08 06 06 00 39 00
					00 40 00 00 37 b2 00 40 00 00 40 00 00 20 20 00
					40 00 00 40 00 00 20 20 00 00 00 00 e0 00 00 00
					20 00 00 20 00 00 20 00 00 20 00 00 00 00 00 00
					00 00 18 00 00 18 00 00 44 00 00 00 39 00 00 40
					00 00 25 b3 88 b8 00 88 b8 80 80 c0 80 00 40 00
					00 40 00 00 40 00 08 38 00 08 38 00 00 40 00 00
					40 00 00 40 00 00 40 00 39 00 00 40 00 00 1a b4
					00 03 06 0c 18 03 06 0c 18 03 06 0c 18 03 06 0c
					18 03 06 0c 18 03 06 0c 18 39 00 00 40 00 00 0a
					b5 00 00 00 00 00 00 00 00 00 39 00 00 40 00 00
					31 b6 1f 1f 1f 1f 1f 1f 1f 1f 1f 1f 1f 1f 1f 1f
					1f 1f 1f 1f 1f 1f 1f 1f 1f 1f 1f 1f 1f 1f 1f 1f
					1f 1f 1f 1f 1f 1f 1f 1f 1f 1f 1f 1f 1f 1f 1f 1f
					1f 1f 39 00 00 00 00 00 1e b7 00 12 34 12 34 52
					34 56 34 56 74 56 78 33 94 26 64 19 98 0c cc 33
					94 26 64 19 98 0c cc 39 00 00 40 00 00 03 f0 aa
					10 15 00 00 40 00 00 02 65 0b 39 00 00 40 00 00
					03 cf dd 79 39 00 00 00 00 00 03 f0 aa 00 39 00
					00 40 00 00 03 f0 aa 19 39 00 00 40 00 00 03 c7
					00 00 15 00 00 40 00 00 02 c4 80 39 00 00 40 00
					00 0d c8 ec 00 00 00 00 00 03 60 00 00 00 00 39
					00 00 40 00 00 0d c8 03 f0 00 00 00 00 00 30 40
					00 00 00 39 00 00 40 00 00 0d c8 03 f0 00 fc 00
					00 00 10 00 00 00 00 39 00 00 40 00 00 0d c8 00
					20 00 03 f0 00 50 a0 c2 08 20 41 39 00 00 40 00
					00 0d c8 d4 00 00 00 00 00 2c 00 00 00 00 00 39
					00 00 40 00 00 0d c8 20 40 00 00 00 00 03 df fe
					00 00 00 39 00 00 40 00 00 0d c8 10 1f c1 f8 00
					00 10 10 3e 04 10 00 39 00 00 40 00 00 0d c8 04
					00 00 fb ff c0 60 82 06 14 30 c1 39 00 00 40 00
					00 0d c8 00 00 00 00 00 00 03 f0 00 00 00 00 39
					00 00 40 00 00 0d c8 f7 cf 80 00 00 00 07 ef ff
					00 00 00 39 00 00 40 00 00 0d c8 03 f0 00 fc 00
					00 03 f0 00 03 f0 00 39 00 00 40 00 00 0d c8 00
					2f bf 00 00 00 50 81 83 08 20 41 15 00 00 00 00
					00 02 c4 00 39 00 00 40 00 00 03 f0 aa 19 39 00
					00 40 00 00 03 c7 00 15 15 00 00 40 00 00 02 c4
					80 39 00 00 40 00 00 0d c8 f0 00 00 00 00 00 f8
					20 00 00 00 00 39 00 00 40 00 00 0d c8 ff ff c0
					00 00 00 f3 ef ff 00 00 00 39 00 00 40 00 00 0d
					c8 f3 ff ff fc 00 00 fb ff c0 ff f0 00 39 00 00
					40 00 00 0d c8 f7 df bf 00 0f c0 5c a1 c4 0c 20
					81 39 00 00 40 00 00 0d c8 f4 00 00 00 00 00 ff
					f0 00 00 00 00 39 00 00 40 00 00 0d c8 ff ff c0
					00 00 00 f7 ff c0 00 00 00 39 00 00 40 00 00 0d
					c8 fb ef ff 00 00 00 fb ff ff fc 00 00 39 00 00
					40 00 00 0d c8 ff ff ff ff f0 00 3c 81 84 0c 20
					41 39 00 00 40 00 00 0d c8 f4 00 00 00 00 00 f4
					00 00 00 00 00 39 00 00 40 00 00 0d c8 f8 0f c0
					00 00 00 f7 ff c0 00 00 00 39 00 00 40 00 00 0d
					c8 f7 d0 00 00 00 00 f7 ef fe ff f0 00 39 00 00
					40 00 00 0d c8 f8 0f c1 03 ff c0 5c 81 02 08 20
					40 15 00 00 00 00 00 02 c4 00 39 00 00 40 00 00
					03 f0 aa 19 39 00 00 40 00 00 03 c7 00 2a 15 00
					00 40 00 00 02 c4 80 39 00 00 40 00 00 0d c8 f4
					00 00 00 00 00 f4 00 00 00 00 00 39 00 00 40 00
					00 0d c8 f7 ef c0 00 00 00 f7 ff c0 00 00 00 39
					00 00 40 00 00 0d c8 fb f0 3f 00 00 00 f3 ef bf
					ff f0 00 39 00 00 40 00 00 0d c8 ff ff ff fc 00
					00 54 81 84 0c 20 41 39 00 00 40 00 00 0d c8 f8
					00 00 00 00 00 f7 f0 00 00 00 00 39 00 00 40 00
					00 0d c8 f7 f0 00 00 00 00 f7 ff c0 00 00 00 39
					00 00 40 00 00 0d c8 fb ff fe fc 00 00 f7 ff c0
					00 00 00 39 00 00 40 00 00 0d c8 ff ff c0 00 00
					00 50 71 43 08 10 41 39 00 00 40 00 00 0d c8 f8
					00 00 00 00 00 f7 f0 00 00 00 00 39 00 00 40 00
					00 0d c8 f3 ff 00 00 00 00 f7 b0 c0 00 00 00 39
					00 00 40 00 00 0d c8 f8 3f ff f0 00 00 fb ff ff
					fc 00 00 39 00 00 40 00 00 0d c8 ff f0 00 13 f0
					00 50 71 03 08 20 41 15 00 00 00 00 00 02 c4 00
					39 00 00 40 00 00 03 f0 aa 19 39 00 00 40 00 00
					03 c7 00 3f 15 00 00 40 00 00 02 c4 80 39 00 00
					40 00 00 0d c8 20 40 40 60 60 60 80 80 80 80 a0
					a0 39 00 00 40 00 00 0d c8 a0 a0 a0 c0 c0 c0 c0
					c0 c0 e0 e0 e0 39 00 00 40 00 00 0d c8 e0 e0 e0
					e0 ff ff ff ff ff ff ff ff 39 00 00 40 00 00 0d
					c8 1b 1c 2f 1e 4c 5b 1f 56 5c 6e a0 a0 39 00 00
					40 00 00 0d c8 a0 a0 a0 c0 c0 c0 c0 c0 c0 e0 e0
					e0 39 00 00 40 00 00 0d c8 e0 e0 e0 e0 ff ff ff
					ff ff ff ff ff 39 00 00 40 00 00 0d c8 20 40 40
					60 60 60 80 80 80 80 a0 a0 39 00 00 40 00 00 0d
					c8 a0 a0 a0 c0 c0 c0 c0 c0 c0 e0 e0 e0 39 00 00
					40 00 00 0d c8 e0 e0 e0 e0 ff ff ff ff ff ff ff
					ff 15 00 00 00 00 00 02 c4 00 39 00 00 40 00 00
					03 f0 aa 19 39 00 00 40 00 00 03 c7 00 c6 15 00
					00 40 00 00 02 c4 80 39 00 00 40 00 00 0d c8 f8
					00 00 00 00 00 d8 00 00 00 00 00 39 00 00 40 00
					00 0d c8 03 f0 00 00 00 00 00 00 40 00 00 00 39
					00 00 40 00 00 0d c8 ec 00 00 fc 00 00 00 00 00
					00 00 00 39 00 00 40 00 00 0d c8 00 00 00 03 f0
					00 50 50 c2 08 20 41 39 00 00 40 00 00 0d c8 c8
					00 00 00 00 00 00 00 00 00 00 00 39 00 00 40 00
					00 0d c8 00 40 00 00 00 00 0b df fe 00 00 00 39
					00 00 40 00 00 0d c8 fc 1f c1 f8 00 00 fc 10 3e
					04 10 00 39 00 00 40 00 00 0d c8 00 00 00 fb ff
					c0 78 82 06 14 30 c1 39 00 00 40 00 00 0d c8 00
					00 00 00 00 00 03 f0 00 00 00 00 39 00 00 40 00
					00 0d c8 f7 cf 80 00 00 00 07 ef ff 00 00 00 39
					00 00 40 00 00 0d c8 03 f0 00 fc 00 00 03 f0 00
					03 f0 00 39 00 00 40 00 00 0d c8 00 2f bf 00 00
					00 50 81 83 08 20 41 15 00 00 00 00 00 02 c4 00
					39 00 00 40 00 00 03 f0 aa 19 39 00 00 40 00 00
					03 c7 00 db 15 00 00 40 00 00 02 c4 80 39 00 00
					40 00 00 0d c8 f0 00 00 00 00 00 f8 20 00 00 00
					00 39 00 00 40 00 00 0d c8 ff ff c0 00 00 00 f3
					ef ff 00 00 00 39 00 00 40 00 00 0d c8 f3 ff ff
					fc 00 00 fb ff c0 ff f0 00 39 00 00 40 00 00 0d
					c8 f7 df bf 00 0f c0 5c a1 c4 0c 20 81 39 00 00
					40 00 00 0d c8 f8 00 00 00 00 00 ff f0 00 00 00
					00 39 00 00 40 00 00 0d c8 ff ff c0 00 00 00 f7
					ff c0 00 00 00 39 00 00 40 00 00 0d c8 fb ef ff
					00 00 00 fb ff ff fc 00 00 39 00 00 40 00 00 0d
					c8 ff ff ff ff f0 00 3c 81 84 0c 20 41 39 00 00
					40 00 00 0d c8 f4 00 00 00 00 00 f4 00 00 00 00
					00 39 00 00 40 00 00 0d c8 f8 0f c0 00 00 00 f7
					ff c0 00 00 00 39 00 00 40 00 00 0d c8 f7 d0 00
					00 00 00 f7 ef fe ff f0 00 39 00 00 40 00 00 0d
					c8 f8 0f c1 03 ff c0 5c 81 02 08 20 40 15 00 00
					00 00 00 02 c4 00 39 00 00 40 00 00 03 f0 aa 19
					39 00 00 40 00 00 03 c7 01 05 15 00 00 40 00 00
					02 c4 80 39 00 00 40 00 00 0d c8 20 40 40 60 60
					60 80 80 80 80 a0 a0 39 00 00 40 00 00 0d c8 a0
					a0 a0 c0 c0 c0 c0 c0 c0 e0 e0 e0 39 00 00 40 00
					00 0d c8 e0 e0 e0 e0 ff ff ff ff ff ff ff ff 39
					00 00 40 00 00 0d c8 20 40 40 60 60 60 80 80 80
					80 a0 a0 39 00 00 40 00 00 0d c8 a0 a0 a0 c0 c0
					c0 c0 c0 c0 e0 e0 e0 39 00 00 40 00 00 0d c8 e0
					e0 e0 e0 ff ff ff ff ff ff ff ff 39 00 00 40 00
					00 0d c8 20 40 40 60 60 60 80 80 80 80 a0 a0 39
					00 00 40 00 00 0d c8 a0 a0 a0 c0 c0 c0 c0 c0 c0
					e0 e0 e0 39 00 00 40 00 00 0d c8 e0 e0 e0 e0 ff
					ff ff ff ff ff ff ff 15 00 00 00 00 00 02 c4 00
				];
				mi,mdss-dsi-timing-switch-pwm-command = [
					15 00 00 40 00 00 02 a4 01 39 00 00 40 00 00 03
					f0 aa 14 15 00 00 40 00 00 02 65 0c 39 00 00 40
					00 00 03 b5 18 0c 39 00 00 40 00 00 05 bc 10 10
					00 1e 15 00 00 40 00 00 02 65 0c 39 00 00 40 00
					00 03 b6 0f 0b 39 00 00 40 00 00 05 bd 10 10 00
					21 15 00 00 40 00 00 02 65 0c 39 00 00 40 00 00
					05 c6 03 07 1f 03 39 00 00 40 00 00 06 ca 10 10
					00 1e 13 39 00 00 40 00 00 03 f0 aa 1b 15 00 00
					40 00 00 02 65 09 39 00 00 40 00 00 04 de 1e 01
					03 15 00 00 00 00 00 02 a4 00 15 00 00 40 00 00
					02 6c 02 39 00 00 40 00 00 03 75 c0 05 39 00 00
					40 00 00 04 71 00 00 00 39 00 00 40 00 00 03 f0
					aa 16 15 00 00 40 00 00 02 d0 01 15 00 00 40 00
					00 02 65 07 15 00 00 40 00 00 02 d1 0b 15 00 00
					40 00 00 02 d2 01 15 00 00 40 00 00 02 65 02 39
					00 00 40 00 00 04 d2 03 65 0f 15 00 00 40 00 00
					02 76 01 15 00 00 40 00 00 02 77 0b 39 00 00 40
					00 00 03 f0 aa 10 15 00 00 40 00 00 02 cf 09 15
					00 00 00 00 00 02 a6 01
				];
				qcom,mdss-dsi-timing-switch-command = [
					15 00 00 40 00 00 02 a4 01 39 00 00 40 00 00 03
					f0 aa 14 15 00 00 40 00 00 02 65 0c 39 00 00 40
					00 00 03 b5 17 0b 39 00 00 40 00 00 05 bc 10 10
					00 1d 15 00 00 40 00 00 02 65 0c 39 00 00 40 00
					00 03 b6 10 0c 39 00 00 40 00 00 05 bd 10 10 00
					22 15 00 00 40 00 00 02 65 0c 39 00 00 40 00 00
					05 c6 02 06 1e 02 39 00 00 40 00 00 06 ca 10 10
					00 1f 22 39 00 00 40 00 00 03 f0 aa 1b 15 00 00
					40 00 00 02 65 09 39 00 00 40 00 00 04 de 1f 02
					02 15 00 00 00 00 00 02 a4 00 15 00 00 40 00 00
					02 6c 00 39 00 00 40 00 00 03 75 c0 05 39 00 00
					40 00 00 04 71 00 00 00 39 00 00 40 00 00 03 f0
					aa 16 15 00 00 40 00 00 02 d0 01 15 00 00 40 00
					00 02 65 01 15 00 00 40 00 00 02 d1 03 15 00 00
					40 00 00 02 d2 01 15 00 00 40 00 00 02 65 02 39
					00 00 40 00 00 04 d2 0a 53 0f 15 00 00 40 00 00
					02 76 01 15 00 00 40 00 00 02 77 03 39 00 00 40
					00 00 03 f0 aa 10 15 00 00 40 00 00 02 cf 09 39
					00 00 40 00 00 03 f0 aa 17 15 00 00 40 00 00 02
					c2 80 15 00 00 00 00 00 02 a6 01
				];
				mi,mdss-dsi-ddic-min-framerate = <1>;
				mi,mdss-dsi-sf-framerate = <60>;
				mi,mdss-dsi-ddic-mode = "auto";
				qcom,mdss-dsi-h-sync-skew = <40449>;
				qcom,mdss-dsi-panel-framerate = <60>;
				cell-index = <7>;
			};

			timing@wqhd_auto_120_to_1hz_index_8 {
				#include "dsi-panel-p1-42-0d-0b-p12-dsc-cmd-common.dtsi"
				qcom,mdss-dsi-on-command = [
					15 00 00 40 00 00 02 03 01 15 00 00 40 00 00 02
					35 00 15 00 00 40 00 00 02 53 20 39 00 00 40 00
					00 03 51 00 00 15 00 00 40 00 00 02 6f 02 15 00
					00 40 00 00 02 59 09 15 00 00 40 00 00 02 6c 00
					15 00 00 40 00 00 02 6d 00 39 00 00 40 00 00 81
					70 12 00 00 ab 30 80 0a 30 04 b0 00 10 02 58 02
					58 02 00 02 2c 00 20 01 98 00 08 00 0c 06 67 05
					b9 18 00 10 f0 07 10 20 00 06 0f 0f 33 0e 1c 2a
					38 46 54 62 69 70 77 79 7b 7d 7e 02 02 22 00 2a
					40 2a be 3a fc 3a fa 3a f8 3b 38 3b 78 3b b6 4b
					b6 4b f4 4b f4 6c 34 84 74 74 00 00 00 00 00 00
					00 00 00 00 00 00 00 00 00 00 00 00 00 00 00 00
					00 00 00 00 00 00 00 00 00 00 00 00 00 00 00 00
					00 39 00 00 40 00 00 03 ff 5a 81 15 00 00 40 00
					00 02 65 03 15 00 00 40 00 00 02 f3 04 15 00 00
					40 00 00 02 65 05 15 00 00 40 00 00 02 f3 48 39
					00 00 40 00 00 03 f0 aa 10 15 00 00 40 00 00 02
					65 0a 15 00 00 40 00 00 02 eb 10 39 00 00 40 00
					00 03 ff 5a 80 15 00 00 40 00 00 02 65 0e 15 00
					00 40 00 00 02 f9 a1 39 00 00 40 00 00 03 ff 5a
					81 15 00 00 40 00 00 02 65 02 39 00 00 40 00 00
					03 fb 63 73 39 00 00 40 00 00 03 f0 aa 10 15 00
					00 40 00 00 02 65 0b 39 00 00 40 00 00 05 d0 e4
					0f 20 40 15 00 00 40 00 00 02 65 15 39 00 00 40
					00 00 13 d1 be 40 40 40 40 0c 00 00 46 1f 1f 00
					00 40 0c 46 1f 1f 39 00 00 40 00 00 14 d9 39 68
					00 00 00 0b 0a 0d 0c 02 00 00 02 07 06 00 06 02
					0d 15 00 00 40 00 00 02 72 01 39 00 00 40 00 00
					03 ff 5a 83 15 00 00 40 00 00 02 65 0b 15 00 00
					40 00 00 02 f8 05 39 00 00 40 00 00 03 f0 aa 11
					15 00 00 40 00 00 02 c3 31 39 00 00 40 00 00 03
					f0 aa 18 15 00 00 40 00 00 02 b0 80 39 00 00 40
					00 00 03 f0 aa 19 15 00 00 40 00 00 02 c0 e0 39
					00 00 40 00 00 03 f0 aa 1a 15 00 00 40 00 00 02
					b0 01 39 00 00 40 00 00 03 f0 aa 10 39 00 00 40
					00 00 04 eb 00 00 30 39 00 00 40 00 00 08 ea 0f
					41 00 88 48 cb 01 15 00 00 40 00 00 02 65 0d 39
					00 00 40 00 00 04 ea 0c 00 01 15 00 00 40 00 00
					02 65 10 39 00 00 40 00 00 04 ea 0c 80 01 15 00
					00 40 00 00 02 65 13 39 00 00 40 00 00 04 ea c8
					ae 01 15 00 00 40 00 00 02 65 16 39 00 00 40 00
					00 04 ea 64 c1 01 15 00 00 40 00 00 02 65 19 39
					00 00 40 00 00 04 ea 98 a5 01 15 00 00 40 00 00
					02 65 28 39 00 00 40 00 00 04 ea 0c 00 00 39 00
					00 40 00 00 03 f0 aa 00 39 00 00 00 00 00 03 ff
					5a 00 05 00 00 00 78 00 01 11 39 00 00 40 00 00
					03 f0 aa 10 15 00 00 40 00 00 02 65 02 39 00 00
					40 00 00 03 cf 24 13 15 00 00 40 00 00 02 65 0b
					39 00 00 40 00 00 03 cf dd 79 39 00 00 40 00 00
					03 f0 aa 16 39 00 00 40 00 00 16 e3 00 01 00 00
					00 00 00 00 00 00 00 00 00 00 00 00 00 00 00 00
					00 39 00 00 40 00 00 16 e4 00 03 00 00 00 00 00
					00 00 00 00 00 00 00 00 00 00 00 00 00 00 39 00
					00 40 00 00 16 e5 00 04 00 00 00 00 00 00 00 00
					00 00 00 00 00 00 00 00 00 00 00 39 00 00 40 00
					00 16 e6 01 03 0b 00 00 00 00 00 00 00 00 00 00
					00 00 00 00 00 00 00 00 39 00 00 40 00 00 16 e7
					03 03 0b 0b 77 00 00 00 00 0e e0 00 00 00 00 00
					00 00 00 00 00 39 00 00 40 00 00 16 e8 02 0b 0b
					77 00 00 00 00 00 ee 00 00 00 00 00 00 00 00 00
					00 00 39 00 00 40 00 00 16 e9 02 08 08 59 00 00
					00 00 00 ee 00 00 00 00 00 00 00 00 00 00 00 39
					00 00 40 00 00 16 ea 00 0b 00 00 00 00 00 00 00
					00 00 00 00 00 00 00 00 00 00 00 00 39 00 00 40
					00 00 16 eb 02 01 03 ef 00 00 00 00 00 00 00 00
					00 00 00 00 00 00 00 00 00 39 00 00 40 00 00 16
					ec 00 01 00 00 00 00 00 00 00 40 00 00 00 00 00
					00 00 00 00 00 00 39 00 00 40 00 00 1f e0 f0 f1
					f2 f3 f4 f5 f6 00 00 00 f0 f1 f2 f3 f4 f5 f6 00
					00 00 f0 f1 f2 f3 f4 f5 f6 00 00 00 39 00 00 40
					00 00 15 ed f0 f1 f2 f3 f4 f5 f6 f7 f8 00 f0 f1
					f2 f3 f4 f5 f6 f7 f8 00 39 00 00 40 00 00 15 ee
					f0 f1 f2 f3 f4 f5 f6 f7 f8 00 f0 f1 f2 f3 f4 f5
					f6 f7 f8 00 39 00 00 40 00 00 03 f0 aa 12 15 00
					00 00 00 00 02 c7 fe 39 00 00 40 00 00 03 f0 aa
					14 15 00 00 40 00 00 02 65 0c 39 00 00 40 00 00
					03 b5 17 0b 39 00 00 40 00 00 05 bc 10 10 00 1d
					15 00 00 40 00 00 02 65 0c 39 00 00 40 00 00 03
					b6 10 0c 39 00 00 40 00 00 05 bd 10 10 00 22 15
					00 00 40 00 00 02 65 0c 39 00 00 40 00 00 05 c6
					02 06 1e 02 39 00 00 40 00 00 06 ca 10 10 00 1f
					22 39 00 00 40 00 00 03 f0 aa 1b 15 00 00 40 00
					00 02 65 09 39 00 00 00 00 00 04 de 1f 02 02 15
					00 00 40 00 00 02 6c 00 39 00 00 40 00 00 03 75
					c0 04 39 00 00 40 00 00 04 71 00 00 00 39 00 00
					40 00 00 03 f0 aa 16 15 00 00 40 00 00 02 d0 03
					15 00 00 40 00 00 02 65 01 15 00 00 40 00 00 02
					d1 01 15 00 00 40 00 00 02 d2 01 15 00 00 40 00
					00 02 65 02 39 00 00 40 00 00 04 d2 0a 53 0f 15
					00 00 40 00 00 02 76 01 15 00 00 40 00 00 02 77
					01 39 00 00 40 00 00 03 f0 aa 10 15 00 00 40 00
					00 02 cf 09 39 00 00 40 00 00 03 f0 aa 17 15 00
					00 40 00 00 02 c2 80 05 00 00 00 00 00 01 29 39
					00 00 40 00 00 03 f0 aa 17 39 00 00 40 00 00 02
					b0 b0 39 00 00 40 00 00 05 b1 08 06 06 00 39 00
					00 40 00 00 37 b2 00 40 00 00 40 00 00 20 20 00
					40 00 00 40 00 00 20 20 00 00 00 00 e0 00 00 00
					20 00 00 20 00 00 20 00 00 20 00 00 00 00 00 00
					00 00 18 00 00 18 00 00 44 00 00 00 39 00 00 40
					00 00 25 b3 88 b8 00 88 b8 80 80 c0 80 00 40 00
					00 40 00 00 40 00 08 38 00 08 38 00 00 40 00 00
					40 00 00 40 00 00 40 00 39 00 00 40 00 00 1a b4
					00 03 06 0c 18 03 06 0c 18 03 06 0c 18 03 06 0c
					18 03 06 0c 18 03 06 0c 18 39 00 00 40 00 00 0a
					b5 00 00 00 00 00 00 00 00 00 39 00 00 40 00 00
					31 b6 1f 1f 1f 1f 1f 1f 1f 1f 1f 1f 1f 1f 1f 1f
					1f 1f 1f 1f 1f 1f 1f 1f 1f 1f 1f 1f 1f 1f 1f 1f
					1f 1f 1f 1f 1f 1f 1f 1f 1f 1f 1f 1f 1f 1f 1f 1f
					1f 1f 39 00 00 00 00 00 1e b7 00 12 34 12 34 52
					34 56 34 56 74 56 78 33 94 26 64 19 98 0c cc 33
					94 26 64 19 98 0c cc 39 00 00 40 00 00 03 f0 aa
					10 15 00 00 40 00 00 02 65 0b 39 00 00 40 00 00
					03 cf dd 79 39 00 00 00 00 00 03 f0 aa 00 39 00
					00 40 00 00 03 f0 aa 19 39 00 00 40 00 00 03 c7
					00 00 15 00 00 40 00 00 02 c4 80 39 00 00 40 00
					00 0d c8 ec 00 00 00 00 00 03 60 00 00 00 00 39
					00 00 40 00 00 0d c8 03 f0 00 00 00 00 00 30 40
					00 00 00 39 00 00 40 00 00 0d c8 03 f0 00 fc 00
					00 00 10 00 00 00 00 39 00 00 40 00 00 0d c8 00
					20 00 03 f0 00 50 a0 c2 08 20 41 39 00 00 40 00
					00 0d c8 d4 00 00 00 00 00 2c 00 00 00 00 00 39
					00 00 40 00 00 0d c8 20 40 00 00 00 00 03 df fe
					00 00 00 39 00 00 40 00 00 0d c8 10 1f c1 f8 00
					00 10 10 3e 04 10 00 39 00 00 40 00 00 0d c8 04
					00 00 fb ff c0 60 82 06 14 30 c1 39 00 00 40 00
					00 0d c8 00 00 00 00 00 00 03 f0 00 00 00 00 39
					00 00 40 00 00 0d c8 f7 cf 80 00 00 00 07 ef ff
					00 00 00 39 00 00 40 00 00 0d c8 03 f0 00 fc 00
					00 03 f0 00 03 f0 00 39 00 00 40 00 00 0d c8 00
					2f bf 00 00 00 50 81 83 08 20 41 15 00 00 00 00
					00 02 c4 00 39 00 00 40 00 00 03 f0 aa 19 39 00
					00 40 00 00 03 c7 00 15 15 00 00 40 00 00 02 c4
					80 39 00 00 40 00 00 0d c8 f0 00 00 00 00 00 f8
					20 00 00 00 00 39 00 00 40 00 00 0d c8 ff ff c0
					00 00 00 f3 ef ff 00 00 00 39 00 00 40 00 00 0d
					c8 f3 ff ff fc 00 00 fb ff c0 ff f0 00 39 00 00
					40 00 00 0d c8 f7 df bf 00 0f c0 5c a1 c4 0c 20
					81 39 00 00 40 00 00 0d c8 f4 00 00 00 00 00 ff
					f0 00 00 00 00 39 00 00 40 00 00 0d c8 ff ff c0
					00 00 00 f7 ff c0 00 00 00 39 00 00 40 00 00 0d
					c8 fb ef ff 00 00 00 fb ff ff fc 00 00 39 00 00
					40 00 00 0d c8 ff ff ff ff f0 00 3c 81 84 0c 20
					41 39 00 00 40 00 00 0d c8 f4 00 00 00 00 00 f4
					00 00 00 00 00 39 00 00 40 00 00 0d c8 f8 0f c0
					00 00 00 f7 ff c0 00 00 00 39 00 00 40 00 00 0d
					c8 f7 d0 00 00 00 00 f7 ef fe ff f0 00 39 00 00
					40 00 00 0d c8 f8 0f c1 03 ff c0 5c 81 02 08 20
					40 15 00 00 00 00 00 02 c4 00 39 00 00 40 00 00
					03 f0 aa 19 39 00 00 40 00 00 03 c7 00 2a 15 00
					00 40 00 00 02 c4 80 39 00 00 40 00 00 0d c8 f4
					00 00 00 00 00 f4 00 00 00 00 00 39 00 00 40 00
					00 0d c8 f7 ef c0 00 00 00 f7 ff c0 00 00 00 39
					00 00 40 00 00 0d c8 fb f0 3f 00 00 00 f3 ef bf
					ff f0 00 39 00 00 40 00 00 0d c8 ff ff ff fc 00
					00 54 81 84 0c 20 41 39 00 00 40 00 00 0d c8 f8
					00 00 00 00 00 f7 f0 00 00 00 00 39 00 00 40 00
					00 0d c8 f7 f0 00 00 00 00 f7 ff c0 00 00 00 39
					00 00 40 00 00 0d c8 fb ff fe fc 00 00 f7 ff c0
					00 00 00 39 00 00 40 00 00 0d c8 ff ff c0 00 00
					00 50 71 43 08 10 41 39 00 00 40 00 00 0d c8 f8
					00 00 00 00 00 f7 f0 00 00 00 00 39 00 00 40 00
					00 0d c8 f3 ff 00 00 00 00 f7 b0 c0 00 00 00 39
					00 00 40 00 00 0d c8 f8 3f ff f0 00 00 fb ff ff
					fc 00 00 39 00 00 40 00 00 0d c8 ff f0 00 13 f0
					00 50 71 03 08 20 41 15 00 00 00 00 00 02 c4 00
					39 00 00 40 00 00 03 f0 aa 19 39 00 00 40 00 00
					03 c7 00 3f 15 00 00 40 00 00 02 c4 80 39 00 00
					40 00 00 0d c8 20 40 40 60 60 60 80 80 80 80 a0
					a0 39 00 00 40 00 00 0d c8 a0 a0 a0 c0 c0 c0 c0
					c0 c0 e0 e0 e0 39 00 00 40 00 00 0d c8 e0 e0 e0
					e0 ff ff ff ff ff ff ff ff 39 00 00 40 00 00 0d
					c8 1b 1c 2f 1e 4c 5b 1f 56 5c 6e a0 a0 39 00 00
					40 00 00 0d c8 a0 a0 a0 c0 c0 c0 c0 c0 c0 e0 e0
					e0 39 00 00 40 00 00 0d c8 e0 e0 e0 e0 ff ff ff
					ff ff ff ff ff 39 00 00 40 00 00 0d c8 20 40 40
					60 60 60 80 80 80 80 a0 a0 39 00 00 40 00 00 0d
					c8 a0 a0 a0 c0 c0 c0 c0 c0 c0 e0 e0 e0 39 00 00
					40 00 00 0d c8 e0 e0 e0 e0 ff ff ff ff ff ff ff
					ff 15 00 00 00 00 00 02 c4 00 39 00 00 40 00 00
					03 f0 aa 19 39 00 00 40 00 00 03 c7 00 c6 15 00
					00 40 00 00 02 c4 80 39 00 00 40 00 00 0d c8 f8
					00 00 00 00 00 d8 00 00 00 00 00 39 00 00 40 00
					00 0d c8 03 f0 00 00 00 00 00 00 40 00 00 00 39
					00 00 40 00 00 0d c8 ec 00 00 fc 00 00 00 00 00
					00 00 00 39 00 00 40 00 00 0d c8 00 00 00 03 f0
					00 50 50 c2 08 20 41 39 00 00 40 00 00 0d c8 c8
					00 00 00 00 00 00 00 00 00 00 00 39 00 00 40 00
					00 0d c8 00 40 00 00 00 00 0b df fe 00 00 00 39
					00 00 40 00 00 0d c8 fc 1f c1 f8 00 00 fc 10 3e
					04 10 00 39 00 00 40 00 00 0d c8 00 00 00 fb ff
					c0 78 82 06 14 30 c1 39 00 00 40 00 00 0d c8 00
					00 00 00 00 00 03 f0 00 00 00 00 39 00 00 40 00
					00 0d c8 f7 cf 80 00 00 00 07 ef ff 00 00 00 39
					00 00 40 00 00 0d c8 03 f0 00 fc 00 00 03 f0 00
					03 f0 00 39 00 00 40 00 00 0d c8 00 2f bf 00 00
					00 50 81 83 08 20 41 15 00 00 00 00 00 02 c4 00
					39 00 00 40 00 00 03 f0 aa 19 39 00 00 40 00 00
					03 c7 00 db 15 00 00 40 00 00 02 c4 80 39 00 00
					40 00 00 0d c8 f0 00 00 00 00 00 f8 20 00 00 00
					00 39 00 00 40 00 00 0d c8 ff ff c0 00 00 00 f3
					ef ff 00 00 00 39 00 00 40 00 00 0d c8 f3 ff ff
					fc 00 00 fb ff c0 ff f0 00 39 00 00 40 00 00 0d
					c8 f7 df bf 00 0f c0 5c a1 c4 0c 20 81 39 00 00
					40 00 00 0d c8 f8 00 00 00 00 00 ff f0 00 00 00
					00 39 00 00 40 00 00 0d c8 ff ff c0 00 00 00 f7
					ff c0 00 00 00 39 00 00 40 00 00 0d c8 fb ef ff
					00 00 00 fb ff ff fc 00 00 39 00 00 40 00 00 0d
					c8 ff ff ff ff f0 00 3c 81 84 0c 20 41 39 00 00
					40 00 00 0d c8 f4 00 00 00 00 00 f4 00 00 00 00
					00 39 00 00 40 00 00 0d c8 f8 0f c0 00 00 00 f7
					ff c0 00 00 00 39 00 00 40 00 00 0d c8 f7 d0 00
					00 00 00 f7 ef fe ff f0 00 39 00 00 40 00 00 0d
					c8 f8 0f c1 03 ff c0 5c 81 02 08 20 40 15 00 00
					00 00 00 02 c4 00 39 00 00 40 00 00 03 f0 aa 19
					39 00 00 40 00 00 03 c7 01 05 15 00 00 40 00 00
					02 c4 80 39 00 00 40 00 00 0d c8 20 40 40 60 60
					60 80 80 80 80 a0 a0 39 00 00 40 00 00 0d c8 a0
					a0 a0 c0 c0 c0 c0 c0 c0 e0 e0 e0 39 00 00 40 00
					00 0d c8 e0 e0 e0 e0 ff ff ff ff ff ff ff ff 39
					00 00 40 00 00 0d c8 20 40 40 60 60 60 80 80 80
					80 a0 a0 39 00 00 40 00 00 0d c8 a0 a0 a0 c0 c0
					c0 c0 c0 c0 e0 e0 e0 39 00 00 40 00 00 0d c8 e0
					e0 e0 e0 ff ff ff ff ff ff ff ff 39 00 00 40 00
					00 0d c8 20 40 40 60 60 60 80 80 80 80 a0 a0 39
					00 00 40 00 00 0d c8 a0 a0 a0 c0 c0 c0 c0 c0 c0
					e0 e0 e0 39 00 00 40 00 00 0d c8 e0 e0 e0 e0 ff
					ff ff ff ff ff ff ff 15 00 00 00 00 00 02 c4 00
				];
				mi,mdss-dsi-timing-switch-pwm-command = [
					15 00 00 40 00 00 02 a4 01 39 00 00 40 00 00 03
					f0 aa 14 15 00 00 40 00 00 02 65 0c 39 00 00 40
					00 00 03 b5 18 0c 39 00 00 40 00 00 05 bc 10 10
					00 1e 15 00 00 40 00 00 02 65 0c 39 00 00 40 00
					00 03 b6 0f 0b 39 00 00 40 00 00 05 bd 10 10 00
					21 15 00 00 40 00 00 02 65 0c 39 00 00 40 00 00
					05 c6 03 07 1f 03 39 00 00 40 00 00 06 ca 10 10
					00 1e 13 39 00 00 40 00 00 03 f0 aa 1b 15 00 00
					40 00 00 02 65 09 39 00 00 40 00 00 04 de 1e 01
					03 15 00 00 00 00 00 02 a4 00 15 00 00 40 00 00
					02 6c 02 39 00 00 40 00 00 03 75 c0 05 39 00 00
					40 00 00 04 71 00 00 00 39 00 00 40 00 00 03 f0
					aa 16 15 00 00 40 00 00 02 d0 03 15 00 00 40 00
					00 02 65 07 15 00 00 40 00 00 02 d1 0b 15 00 00
					40 00 00 02 d2 01 15 00 00 40 00 00 02 65 02 39
					00 00 40 00 00 04 d2 03 65 0f 15 00 00 40 00 00
					02 76 01 15 00 00 40 00 00 02 77 05 39 00 00 40
					00 00 03 f0 aa 10 15 00 00 40 00 00 02 cf 09 15
					00 00 00 00 00 02 a6 01
				];
				qcom,mdss-dsi-timing-switch-command = [
					15 00 00 40 00 00 02 a4 01 39 00 00 40 00 00 03
					f0 aa 14 15 00 00 40 00 00 02 65 0c 39 00 00 40
					00 00 03 b5 17 0b 39 00 00 40 00 00 05 bc 10 10
					00 1d 15 00 00 40 00 00 02 65 0c 39 00 00 40 00
					00 03 b6 10 0c 39 00 00 40 00 00 05 bd 10 10 00
					22 15 00 00 40 00 00 02 65 0c 39 00 00 40 00 00
					05 c6 02 06 1e 02 39 00 00 40 00 00 06 ca 10 10
					00 1f 22 39 00 00 40 00 00 03 f0 aa 1b 15 00 00
					40 00 00 02 65 09 39 00 00 40 00 00 04 de 1f 02
					02 15 00 00 00 00 00 02 a4 00 15 00 00 40 00 00
					02 6c 00 39 00 00 40 00 00 03 75 c0 04 39 00 00
					40 00 00 04 71 00 00 00 39 00 00 40 00 00 03 f0
					aa 16 15 00 00 40 00 00 02 d0 03 15 00 00 40 00
					00 02 65 01 15 00 00 40 00 00 02 d1 01 15 00 00
					40 00 00 02 d2 01 15 00 00 40 00 00 02 65 02 39
					00 00 40 00 00 04 d2 0a 53 0f 15 00 00 40 00 00
					02 76 01 15 00 00 40 00 00 02 77 01 39 00 00 40
					00 00 03 f0 aa 10 15 00 00 40 00 00 02 cf 09 39
					00 00 40 00 00 03 f0 aa 17 15 00 00 40 00 00 02
					c2 80 15 00 00 00 00 00 02 a6 01
				];
				mi,mdss-dsi-ddic-min-framerate = <1>;
				mi,mdss-dsi-sf-framerate = <120>;
				mi,mdss-dsi-ddic-mode = "auto";
				qcom,mdss-dsi-h-sync-skew = <48129>;
				qcom,mdss-dsi-panel-framerate = <120>;
				cell-index = <8>;
			};

			timing@wqhd_qsync_120_to_10hz_index_9 {
				#include "dsi-panel-p1-42-0d-0b-p12-dsc-cmd-common.dtsi"
				qcom,mdss-dsi-on-command = [
					15 00 00 40 00 00 02 03 01 15 00 00 40 00 00 02
					35 00 15 00 00 40 00 00 02 53 20 39 00 00 40 00
					00 03 51 00 00 15 00 00 40 00 00 02 6f 02 15 00
					00 40 00 00 02 59 09 15 00 00 40 00 00 02 6c 00
					15 00 00 40 00 00 02 6d 00 39 00 00 40 00 00 81
					70 12 00 00 ab 30 80 0a 30 04 b0 00 10 02 58 02
					58 02 00 02 2c 00 20 01 98 00 08 00 0c 06 67 05
					b9 18 00 10 f0 07 10 20 00 06 0f 0f 33 0e 1c 2a
					38 46 54 62 69 70 77 79 7b 7d 7e 02 02 22 00 2a
					40 2a be 3a fc 3a fa 3a f8 3b 38 3b 78 3b b6 4b
					b6 4b f4 4b f4 6c 34 84 74 74 00 00 00 00 00 00
					00 00 00 00 00 00 00 00 00 00 00 00 00 00 00 00
					00 00 00 00 00 00 00 00 00 00 00 00 00 00 00 00
					00 39 00 00 40 00 00 03 ff 5a 81 15 00 00 40 00
					00 02 65 03 15 00 00 40 00 00 02 f3 04 15 00 00
					40 00 00 02 65 05 15 00 00 40 00 00 02 f3 48 39
					00 00 40 00 00 03 f0 aa 10 15 00 00 40 00 00 02
					65 0a 15 00 00 40 00 00 02 eb 10 39 00 00 40 00
					00 03 ff 5a 80 15 00 00 40 00 00 02 65 0e 15 00
					00 40 00 00 02 f9 a1 39 00 00 40 00 00 03 ff 5a
					81 15 00 00 40 00 00 02 65 02 39 00 00 40 00 00
					03 fb 63 73 39 00 00 40 00 00 03 f0 aa 10 15 00
					00 40 00 00 02 65 0b 39 00 00 40 00 00 05 d0 e4
					0f 20 40 15 00 00 40 00 00 02 65 15 39 00 00 40
					00 00 13 d1 be 40 40 40 40 0c 00 00 46 1f 1f 00
					00 40 0c 46 1f 1f 39 00 00 40 00 00 14 d9 39 68
					00 00 00 0b 0a 0d 0c 02 00 00 02 07 06 00 06 02
					0d 15 00 00 40 00 00 02 72 01 39 00 00 40 00 00
					03 ff 5a 83 15 00 00 40 00 00 02 65 0b 15 00 00
					40 00 00 02 f8 05 39 00 00 40 00 00 03 f0 aa 11
					15 00 00 40 00 00 02 c3 31 39 00 00 40 00 00 03
					f0 aa 18 15 00 00 40 00 00 02 b0 80 39 00 00 40
					00 00 03 f0 aa 19 15 00 00 40 00 00 02 c0 e0 39
					00 00 40 00 00 03 f0 aa 1a 15 00 00 40 00 00 02
					b0 01 39 00 00 40 00 00 03 f0 aa 10 39 00 00 40
					00 00 04 eb 00 00 30 39 00 00 40 00 00 08 ea 0f
					41 00 88 48 cb 01 15 00 00 40 00 00 02 65 0d 39
					00 00 40 00 00 04 ea 0c 00 01 15 00 00 40 00 00
					02 65 10 39 00 00 40 00 00 04 ea 0c 80 01 15 00
					00 40 00 00 02 65 13 39 00 00 40 00 00 04 ea c8
					ae 01 15 00 00 40 00 00 02 65 16 39 00 00 40 00
					00 04 ea 64 c1 01 15 00 00 40 00 00 02 65 19 39
					00 00 40 00 00 04 ea 98 a5 01 15 00 00 40 00 00
					02 65 28 39 00 00 40 00 00 04 ea 0c 00 00 39 00
					00 40 00 00 03 f0 aa 00 39 00 00 00 00 00 03 ff
					5a 00 05 00 00 00 78 00 01 11 39 00 00 40 00 00
					03 f0 aa 10 15 00 00 40 00 00 02 65 02 39 00 00
					40 00 00 03 cf 24 13 15 00 00 40 00 00 02 65 0b
					39 00 00 40 00 00 03 cf dd 79 39 00 00 40 00 00
					03 f0 aa 16 39 00 00 40 00 00 16 e3 00 01 00 00
					00 00 00 00 00 00 00 00 00 00 00 00 00 00 00 00
					00 39 00 00 40 00 00 16 e4 00 03 00 00 00 00 00
					00 00 00 00 00 00 00 00 00 00 00 00 00 00 39 00
					00 40 00 00 16 e5 00 04 00 00 00 00 00 00 00 00
					00 00 00 00 00 00 00 00 00 00 00 39 00 00 40 00
					00 16 e6 01 03 0b 00 00 00 00 00 00 00 00 00 00
					00 00 00 00 00 00 00 00 39 00 00 40 00 00 16 e7
					03 03 0b 0b 77 00 00 00 00 0e e0 00 00 00 00 00
					00 00 00 00 00 39 00 00 40 00 00 16 e8 02 0b 0b
					77 00 00 00 00 00 ee 00 00 00 00 00 00 00 00 00
					00 00 39 00 00 40 00 00 16 e9 02 08 08 59 00 00
					00 00 00 ee 00 00 00 00 00 00 00 00 00 00 00 39
					00 00 40 00 00 16 ea 00 0b 00 00 00 00 00 00 00
					00 00 00 00 00 00 00 00 00 00 00 00 39 00 00 40
					00 00 16 eb 02 01 03 ef 00 00 00 00 00 00 00 00
					00 00 00 00 00 00 00 00 00 39 00 00 40 00 00 16
					ec 00 01 00 00 00 00 00 00 00 40 00 00 00 00 00
					00 00 00 00 00 00 39 00 00 40 00 00 1f e0 f0 f1
					f2 f3 f4 f5 f6 00 00 00 f0 f1 f2 f3 f4 f5 f6 00
					00 00 f0 f1 f2 f3 f4 f5 f6 00 00 00 39 00 00 40
					00 00 15 ed f0 f1 f2 f3 f4 f5 f6 f7 f8 00 f0 f1
					f2 f3 f4 f5 f6 f7 f8 00 39 00 00 40 00 00 15 ee
					f0 f1 f2 f3 f4 f5 f6 f7 f8 00 f0 f1 f2 f3 f4 f5
					f6 f7 f8 00 39 00 00 40 00 00 03 f0 aa 12 15 00
					00 00 00 00 02 c7 fe 39 00 00 40 00 00 03 f0 aa
					14 15 00 00 40 00 00 02 65 0c 39 00 00 40 00 00
					03 b5 18 0c 39 00 00 40 00 00 05 bc 10 10 00 1e
					15 00 00 40 00 00 02 65 0c 39 00 00 40 00 00 03
					b6 0f 0b 39 00 00 40 00 00 05 bd 10 10 00 21 15
					00 00 40 00 00 02 65 0c 39 00 00 40 00 00 05 c6
					03 07 1f 03 39 00 00 40 00 00 06 ca 10 10 00 1e
					13 39 00 00 40 00 00 03 f0 aa 1b 15 00 00 40 00
					00 02 65 09 39 00 00 00 00 00 04 de 1e 01 03 15
					00 00 40 00 00 02 6c 02 39 00 00 40 00 00 03 75
					c0 07 39 00 00 40 00 00 04 71 00 00 00 39 00 00
					40 00 00 03 f0 aa 16 15 00 00 40 00 00 02 d0 01
					15 00 00 40 00 00 02 65 07 15 00 00 40 00 00 02
					d1 0b 15 00 00 40 00 00 02 d2 02 15 00 00 40 00
					00 02 76 00 15 00 00 40 00 00 02 77 00 39 00 00
					40 00 00 03 f0 aa 10 15 00 00 40 00 00 02 cf 17
					05 00 00 00 00 00 01 29 39 00 00 40 00 00 03 f0
					aa 17 39 00 00 40 00 00 02 b0 b0 39 00 00 40 00
					00 05 b1 08 06 06 00 39 00 00 40 00 00 37 b2 00
					40 00 00 40 00 00 20 20 00 40 00 00 40 00 00 20
					20 00 00 00 00 e0 00 00 00 20 00 00 20 00 00 20
					00 00 20 00 00 00 00 00 00 00 00 18 00 00 18 00
					00 44 00 00 00 39 00 00 40 00 00 25 b3 88 b8 00
					88 b8 80 80 c0 80 00 40 00 00 40 00 00 40 00 08
					38 00 08 38 00 00 40 00 00 40 00 00 40 00 00 40
					00 39 00 00 40 00 00 1a b4 00 03 06 0c 18 03 06
					0c 18 03 06 0c 18 03 06 0c 18 03 06 0c 18 03 06
					0c 18 39 00 00 40 00 00 0a b5 00 00 00 00 00 00
					00 00 00 39 00 00 40 00 00 31 b6 1f 1f 1f 1f 1f
					1f 1f 1f 1f 1f 1f 1f 1f 1f 1f 1f 1f 1f 1f 1f 1f
					1f 1f 1f 1f 1f 1f 1f 1f 1f 1f 1f 1f 1f 1f 1f 1f
					1f 1f 1f 1f 1f 1f 1f 1f 1f 1f 1f 39 00 00 00 00
					00 1e b7 00 12 34 12 34 52 34 56 34 56 74 56 78
					33 94 26 64 19 98 0c cc 33 94 26 64 19 98 0c cc
					39 00 00 40 00 00 03 f0 aa 10 15 00 00 40 00 00
					02 65 0b 39 00 00 40 00 00 03 cf dd 79 39 00 00
					00 00 00 03 f0 aa 00 39 00 00 40 00 00 03 f0 aa
					19 39 00 00 40 00 00 03 c7 00 00 15 00 00 40 00
					00 02 c4 80 39 00 00 40 00 00 0d c8 ec 00 00 00
					00 00 03 60 00 00 00 00 39 00 00 40 00 00 0d c8
					03 f0 00 00 00 00 00 30 40 00 00 00 39 00 00 40
					00 00 0d c8 03 f0 00 fc 00 00 00 10 00 00 00 00
					39 00 00 40 00 00 0d c8 00 20 00 03 f0 00 50 a0
					c2 08 20 41 39 00 00 40 00 00 0d c8 d4 00 00 00
					00 00 2c 00 00 00 00 00 39 00 00 40 00 00 0d c8
					20 40 00 00 00 00 03 df fe 00 00 00 39 00 00 40
					00 00 0d c8 10 1f c1 f8 00 00 10 10 3e 04 10 00
					39 00 00 40 00 00 0d c8 04 00 00 fb ff c0 60 82
					06 14 30 c1 39 00 00 40 00 00 0d c8 00 00 00 00
					00 00 03 f0 00 00 00 00 39 00 00 40 00 00 0d c8
					f7 cf 80 00 00 00 07 ef ff 00 00 00 39 00 00 40
					00 00 0d c8 03 f0 00 fc 00 00 03 f0 00 03 f0 00
					39 00 00 40 00 00 0d c8 00 2f bf 00 00 00 50 81
					83 08 20 41 15 00 00 00 00 00 02 c4 00 39 00 00
					40 00 00 03 f0 aa 19 39 00 00 40 00 00 03 c7 00
					15 15 00 00 40 00 00 02 c4 80 39 00 00 40 00 00
					0d c8 f0 00 00 00 00 00 f8 20 00 00 00 00 39 00
					00 40 00 00 0d c8 ff ff c0 00 00 00 f3 ef ff 00
					00 00 39 00 00 40 00 00 0d c8 f3 ff ff fc 00 00
					fb ff c0 ff f0 00 39 00 00 40 00 00 0d c8 f7 df
					bf 00 0f c0 5c a1 c4 0c 20 81 39 00 00 40 00 00
					0d c8 f4 00 00 00 00 00 ff f0 00 00 00 00 39 00
					00 40 00 00 0d c8 ff ff c0 00 00 00 f7 ff c0 00
					00 00 39 00 00 40 00 00 0d c8 fb ef ff 00 00 00
					fb ff ff fc 00 00 39 00 00 40 00 00 0d c8 ff ff
					ff ff f0 00 3c 81 84 0c 20 41 39 00 00 40 00 00
					0d c8 f4 00 00 00 00 00 f4 00 00 00 00 00 39 00
					00 40 00 00 0d c8 f8 0f c0 00 00 00 f7 ff c0 00
					00 00 39 00 00 40 00 00 0d c8 f7 d0 00 00 00 00
					f7 ef fe ff f0 00 39 00 00 40 00 00 0d c8 f8 0f
					c1 03 ff c0 5c 81 02 08 20 40 15 00 00 00 00 00
					02 c4 00 39 00 00 40 00 00 03 f0 aa 19 39 00 00
					40 00 00 03 c7 00 2a 15 00 00 40 00 00 02 c4 80
					39 00 00 40 00 00 0d c8 f4 00 00 00 00 00 f4 00
					00 00 00 00 39 00 00 40 00 00 0d c8 f7 ef c0 00
					00 00 f7 ff c0 00 00 00 39 00 00 40 00 00 0d c8
					fb f0 3f 00 00 00 f3 ef bf ff f0 00 39 00 00 40
					00 00 0d c8 ff ff ff fc 00 00 54 81 84 0c 20 41
					39 00 00 40 00 00 0d c8 f8 00 00 00 00 00 f7 f0
					00 00 00 00 39 00 00 40 00 00 0d c8 f7 f0 00 00
					00 00 f7 ff c0 00 00 00 39 00 00 40 00 00 0d c8
					fb ff fe fc 00 00 f7 ff c0 00 00 00 39 00 00 40
					00 00 0d c8 ff ff c0 00 00 00 50 71 43 08 10 41
					39 00 00 40 00 00 0d c8 f8 00 00 00 00 00 f7 f0
					00 00 00 00 39 00 00 40 00 00 0d c8 f3 ff 00 00
					00 00 f7 b0 c0 00 00 00 39 00 00 40 00 00 0d c8
					f8 3f ff f0 00 00 fb ff ff fc 00 00 39 00 00 40
					00 00 0d c8 ff f0 00 13 f0 00 50 71 03 08 20 41
					15 00 00 00 00 00 02 c4 00 39 00 00 40 00 00 03
					f0 aa 19 39 00 00 40 00 00 03 c7 00 3f 15 00 00
					40 00 00 02 c4 80 39 00 00 40 00 00 0d c8 20 40
					40 60 60 60 80 80 80 80 a0 a0 39 00 00 40 00 00
					0d c8 a0 a0 a0 c0 c0 c0 c0 c0 c0 e0 e0 e0 39 00
					00 40 00 00 0d c8 e0 e0 e0 e0 ff ff ff ff ff ff
					ff ff 39 00 00 40 00 00 0d c8 1b 1c 2f 1e 4c 5b
					1f 56 5c 6e a0 a0 39 00 00 40 00 00 0d c8 a0 a0
					a0 c0 c0 c0 c0 c0 c0 e0 e0 e0 39 00 00 40 00 00
					0d c8 e0 e0 e0 e0 ff ff ff ff ff ff ff ff 39 00
					00 40 00 00 0d c8 20 40 40 60 60 60 80 80 80 80
					a0 a0 39 00 00 40 00 00 0d c8 a0 a0 a0 c0 c0 c0
					c0 c0 c0 e0 e0 e0 39 00 00 40 00 00 0d c8 e0 e0
					e0 e0 ff ff ff ff ff ff ff ff 15 00 00 00 00 00
					02 c4 00 39 00 00 40 00 00 03 f0 aa 19 39 00 00
					40 00 00 03 c7 00 c6 15 00 00 40 00 00 02 c4 80
					39 00 00 40 00 00 0d c8 f8 00 00 00 00 00 d8 00
					00 00 00 00 39 00 00 40 00 00 0d c8 03 f0 00 00
					00 00 00 00 40 00 00 00 39 00 00 40 00 00 0d c8
					ec 00 00 fc 00 00 00 00 00 00 00 00 39 00 00 40
					00 00 0d c8 00 00 00 03 f0 00 50 50 c2 08 20 41
					39 00 00 40 00 00 0d c8 c8 00 00 00 00 00 00 00
					00 00 00 00 39 00 00 40 00 00 0d c8 00 40 00 00
					00 00 0b df fe 00 00 00 39 00 00 40 00 00 0d c8
					fc 1f c1 f8 00 00 fc 10 3e 04 10 00 39 00 00 40
					00 00 0d c8 00 00 00 fb ff c0 78 82 06 14 30 c1
					39 00 00 40 00 00 0d c8 00 00 00 00 00 00 03 f0
					00 00 00 00 39 00 00 40 00 00 0d c8 f7 cf 80 00
					00 00 07 ef ff 00 00 00 39 00 00 40 00 00 0d c8
					03 f0 00 fc 00 00 03 f0 00 03 f0 00 39 00 00 40
					00 00 0d c8 00 2f bf 00 00 00 50 81 83 08 20 41
					15 00 00 00 00 00 02 c4 00 39 00 00 40 00 00 03
					f0 aa 19 39 00 00 40 00 00 03 c7 00 db 15 00 00
					40 00 00 02 c4 80 39 00 00 40 00 00 0d c8 f0 00
					00 00 00 00 f8 20 00 00 00 00 39 00 00 40 00 00
					0d c8 ff ff c0 00 00 00 f3 ef ff 00 00 00 39 00
					00 40 00 00 0d c8 f3 ff ff fc 00 00 fb ff c0 ff
					f0 00 39 00 00 40 00 00 0d c8 f7 df bf 00 0f c0
					5c a1 c4 0c 20 81 39 00 00 40 00 00 0d c8 f8 00
					00 00 00 00 ff f0 00 00 00 00 39 00 00 40 00 00
					0d c8 ff ff c0 00 00 00 f7 ff c0 00 00 00 39 00
					00 40 00 00 0d c8 fb ef ff 00 00 00 fb ff ff fc
					00 00 39 00 00 40 00 00 0d c8 ff ff ff ff f0 00
					3c 81 84 0c 20 41 39 00 00 40 00 00 0d c8 f4 00
					00 00 00 00 f4 00 00 00 00 00 39 00 00 40 00 00
					0d c8 f8 0f c0 00 00 00 f7 ff c0 00 00 00 39 00
					00 40 00 00 0d c8 f7 d0 00 00 00 00 f7 ef fe ff
					f0 00 39 00 00 40 00 00 0d c8 f8 0f c1 03 ff c0
					5c 81 02 08 20 40 15 00 00 00 00 00 02 c4 00 39
					00 00 40 00 00 03 f0 aa 19 39 00 00 40 00 00 03
					c7 01 05 15 00 00 40 00 00 02 c4 80 39 00 00 40
					00 00 0d c8 20 40 40 60 60 60 80 80 80 80 a0 a0
					39 00 00 40 00 00 0d c8 a0 a0 a0 c0 c0 c0 c0 c0
					c0 e0 e0 e0 39 00 00 40 00 00 0d c8 e0 e0 e0 e0
					ff ff ff ff ff ff ff ff 39 00 00 40 00 00 0d c8
					20 40 40 60 60 60 80 80 80 80 a0 a0 39 00 00 40
					00 00 0d c8 a0 a0 a0 c0 c0 c0 c0 c0 c0 e0 e0 e0
					39 00 00 40 00 00 0d c8 e0 e0 e0 e0 ff ff ff ff
					ff ff ff ff 39 00 00 40 00 00 0d c8 20 40 40 60
					60 60 80 80 80 80 a0 a0 39 00 00 40 00 00 0d c8
					a0 a0 a0 c0 c0 c0 c0 c0 c0 e0 e0 e0 39 00 00 40
					00 00 0d c8 e0 e0 e0 e0 ff ff ff ff ff ff ff ff
					15 00 00 00 00 00 02 c4 00
				];
				mi,mdss-dsi-timing-switch-pwm-command = [
					15 00 00 40 00 00 02 a4 01 39 00 00 40 00 00 03
					f0 aa 14 15 00 00 40 00 00 02 65 0c 39 00 00 40
					00 00 03 b5 18 0c 39 00 00 40 00 00 05 bc 10 10
					00 1e 15 00 00 40 00 00 02 65 0c 39 00 00 40 00
					00 03 b6 0f 0b 39 00 00 40 00 00 05 bd 10 10 00
					21 15 00 00 40 00 00 02 65 0c 39 00 00 40 00 00
					05 c6 03 07 1f 03 39 00 00 40 00 00 06 ca 10 10
					00 1e 13 39 00 00 40 00 00 03 f0 aa 1b 15 00 00
					40 00 00 02 65 09 39 00 00 40 00 00 04 de 1e 01
					03 15 00 00 00 00 00 02 a4 00 15 00 00 40 00 00
					02 6c 02 39 00 00 40 00 00 03 75 c0 07 39 00 00
					40 00 00 04 71 00 00 00 39 00 00 40 00 00 03 f0
					aa 16 15 00 00 40 00 00 02 d0 01 15 00 00 40 00
					00 02 65 07 15 00 00 40 00 00 02 d1 0b 15 00 00
					40 00 00 02 d2 02 15 00 00 40 00 00 02 76 00 15
					00 00 40 00 00 02 77 00 39 00 00 40 00 00 03 f0
					aa 10 15 00 00 40 00 00 02 cf 17 15 00 00 00 00
					00 02 a6 01
				];
				qcom,mdss-dsi-timing-switch-command = [
					15 00 00 40 00 00 02 a4 01 39 00 00 40 00 00 03
					f0 aa 14 15 00 00 40 00 00 02 65 0c 39 00 00 40
					00 00 03 b5 17 0b 39 00 00 40 00 00 05 bc 10 10
					00 1d 15 00 00 40 00 00 02 65 0c 39 00 00 40 00
					00 03 b6 10 0c 39 00 00 40 00 00 05 bd 10 10 00
					22 15 00 00 40 00 00 02 65 0c 39 00 00 40 00 00
					05 c6 02 06 1e 02 39 00 00 40 00 00 06 ca 10 10
					00 1f 22 39 00 00 40 00 00 03 f0 aa 1b 15 00 00
					40 00 00 02 65 09 39 00 00 40 00 00 04 de 1f 02
					02 15 00 00 40 00 00 02 6c 00 39 00 00 40 00 00
					03 75 c0 03 39 00 00 40 00 00 04 71 00 00 00 39
					00 00 40 00 00 03 f0 aa 16 15 00 00 40 00 00 02
					d0 01 15 00 00 40 00 00 02 65 01 15 00 00 40 00
					00 02 d1 01 15 00 00 40 00 00 02 d2 01 15 00 00
					40 00 00 02 76 00 15 00 00 40 00 00 02 77 00 39
					00 00 40 00 00 03 f0 aa 10 15 00 00 40 00 00 02
					cf 17 39 00 00 40 00 00 03 f0 aa 00 15 00 00 40
					00 00 02 a4 00 15 00 00 00 00 00 02 a6 01
				];
				mi,mdss-dsi-ddic-min-framerate = <10>;
				mi,mdss-dsi-sf-framerate = <120>;
				mi,mdss-dsi-ddic-mode = "qsync";
				qcom,mdss-dsi-h-sync-skew = <64522>;
				qcom,dsi-qsync-mode-avr-step-fps = <360>;
				qcom,mdss-dsi-panel-framerate = <120>;
				cell-index = <9>;
			};
		};
	};
};
